VERSION ""

NS_ :

BS_:

BU_: TBOX Tester WCM MFS HUD CGW IHU

BO_ 3221225472 VECTOR__INDEPENDENT_SIG_MSG: 0 Vector__XXX
 SG_ SET_Rmirror_UD_Locaton : 0|6@0+ (2,-2) [0|100] "%" Vector__XXX
 SG_ SET_Rmirror_LR_Locaton : 0|6@0+ (2,-2) [0|100] "%" Vector__XXX
 SG_ SET_Lmirror_UD_Locaton : 0|6@0+ (2,-2) [0|100] "%" Vector__XXX
 SG_ SET_Lmirror_LR_Locaton : 0|6@0+ (2,-2) [0|100] "%" Vector__XXX
 SG_ HCU_HundECHis : 0|9@0+ (0.1,0) [0|51] "Kwh" Vector__XXX
 SG_ HCU_HundECAver : 0|9@0+ (0.1,0) [0|51] "Kwh" Vector__XXX
 SG_ CEM_IPM_FRSeatHeatVentSwSts : 0|3@0+ (1,0) [0|7] "Bit" Vector__XXX
 SG_ CEM_IPM_FLSeatHeatVentSwSts : 0|3@0+ (1,0) [0|7] "Bit" Vector__XXX
 SG_ IHU_StopChargeSW : 0|1@0+ (1,0) [0|1] "" Vector__XXX
 SG_ R_MsgAliveCounter : 0|4@0+ (1,0) [0|15] "" Vector__XXX

BO_ 1796 eLSD_Request: 8 IHU
 SG_ eLSD_Request_frame_type : 7|64@0+ (1,0) [0|7] ""  CGW

BO_ 1812 eLSD_response: 8 CGW
 SG_ eLSD_response_frame_type : 7|64@0+ (1,0) [0|7] ""  IHU

BO_ 1794 AWD_Request: 8 IHU
 SG_ AWD_Request_frame_type : 7|64@0+ (1,0) [0|7] ""  CGW

BO_ 1810 AWD_response: 8 CGW
 SG_ AWD_response_frame_type : 7|64@0+ (1,0) [0|7] ""  IHU

BO_ 1854 Diag_FCM_RES: 8 CGW
 SG_ Diag_FCM_RES : 7|64@0+ (1,0) [0|7] ""  IHU

BO_ 1838 Diag_FCM_REQ: 8 IHU
 SG_ FCM_Request_Frame_Type : 7|64@0+ (1,0) [0|7] ""  CGW

BO_ 1906 Diag_CGW_RES: 8 CGW
 SG_ Diag_CGW_RES : 7|64@0+ (1,0) [0|1] ""  IHU

BO_ 1890 Diag_CGW_REQ: 8 IHU
 SG_ Diag_CGW_REQ : 7|64@0+ (1,0) [0|1] ""  CGW

BO_ 933 FCM_FRM_2: 8 CGW
 SG_ PEBSObjectType : 54|3@0+ (1,0) [0|7] ""  IHU

BO_ 2015 Request_Broadcast: 8 IHU
 SG_ Request_Broadcast : 7|64@0+ (1,0) [0|1] ""  CGW

BO_ 1793 DVR_Request: 8 IHU
 SG_ DVR_Request_Frame_Type : 7|64@0+ (1,0) [0|1] ""  CGW

BO_ 1798 FPLA_Request: 8 IHU
 SG_ FPLA_Request_Frame_Type : 7|64@0+ (1,0) [0|1] ""  CGW

BO_ 1804 EAC_Request: 8 IHU
 SG_ EAC_Request_Frame_Type : 7|64@0+ (1,0) [0|1] ""  CGW

BO_ 1809 DVR_Response: 8 CGW
 SG_ DVR_Response_Frame_Type : 7|64@0+ (1,0) [0|1] ""  IHU

BO_ 1814 FPLA_Response: 8 CGW
 SG_ FPLA_Response_Frame_Type : 7|64@0+ (1,0) [0|1] ""  IHU

BO_ 1820 EAC_response: 8 CGW
 SG_ EAC_response_frame_type : 7|64@0+ (1,0) [0|1] ""  IHU

BO_ 1827 DWD_Request: 8 IHU
 SG_ DWD_Request_Frame_Type : 7|64@0+ (1,0) [0|1] ""  CGW

BO_ 1830 PLG_Request: 8 IHU
 SG_ PLG_Request : 7|64@0+ (1,0) [0|1] ""  CGW

BO_ 1833 ATCM_Request: 8 IHU
 SG_ ATCM_Request_frame_type : 7|64@0+ (1,0) [0|1] ""  CGW

BO_ 1843 DWD_Response: 8 CGW
 SG_ DWD_Response_Frame_Type : 7|64@0+ (1,0) [0|1] ""  IHU

BO_ 1846 PLG_response: 8 CGW
 SG_ PLG_response : 7|64@0+ (1,0) [0|1] ""  IHU

BO_ 1849 ATCM_Response: 8 CGW
 SG_ ATCMResponse_Frame_Type : 7|64@0+ (1,0) [0|1] ""  IHU

BO_ 1860 WCM_Request: 8 IHU
 SG_ WCM_Request_Frame_Type : 7|64@0+ (1,0) [0|1] ""  CGW

BO_ 1864 BSD_Request: 8 IHU
 SG_ BSD_Request_frame_type : 7|64@0+ (1,0) [0|1] ""  CGW

BO_ 1867 IPM_Request: 8 IHU
 SG_ IPM_Request_Frame_Type : 7|64@0+ (1,0) [0|1] ""  CGW

BO_ 1869 IMMO_Request: 8 IHU
 SG_ IMMO_Request_Frame_Type : 7|64@0+ (1,0) [0|1] ""  CGW

BO_ 1870 PTC_Request: 8 IHU
 SG_ PTC_Request_Frame_Type : 7|64@0+ (1,0) [0|1] ""  CGW

BO_ 1876 WCM_Response: 8 CGW
 SG_ WCM_Response_Frame_Type : 7|64@0+ (1,0) [0|1] ""  IHU

BO_ 1880 BSD_response: 8 CGW
 SG_ BSD_response_frame_type : 7|64@0+ (1,0) [0|1] ""  IHU

BO_ 1883 IPM_response: 8 CGW
 SG_ IPM_response_frame_type : 7|64@0+ (1,0) [0|1] ""  IHU

BO_ 1885 IMMO_response: 8 CGW
 SG_ IMMO_response_frame_type : 7|64@0+ (1,0) [0|1] ""  IHU

BO_ 1886 PTC_response: 8 CGW
 SG_ PTC_response_frame_type : 7|64@0+ (1,0) [0|1] ""  IHU

BO_ 1888 CEM_Request: 8 IHU
 SG_ CEM_Request_frame_type : 7|64@0+ (1,0) [0|1] ""  CGW

BO_ 1891 Radar_Request: 8 IHU
 SG_ Radar_Request_Frame_Type : 7|64@0+ (1,0) [0|1] ""  CGW

BO_ 1898 RFR_Request: 8 IHU
 SG_ RFR_Request_Frame_Type : 7|64@0+ (1,0) [0|1] ""  CGW

BO_ 1899 APM_Request: 8 IHU
 SG_ APM_Request_Frame_Type : 7|64@0+ (1,0) [0|1] ""  CGW

BO_ 1904 CEM_response: 8 CGW
 SG_ CEM_response_frame_type : 7|64@0+ (1,0) [0|1] ""  IHU

BO_ 1907 Radar_response: 8 CGW
 SG_ Radar_response_frame_type : 7|64@0+ (1,0) [0|1] ""  IHU

BO_ 1914 RFR_response: 8 CGW
 SG_ RFR_response_frame_type : 7|64@0+ (1,0) [0|1] ""  IHU

BO_ 1915 APM_response: 8 CGW
 SG_ APM_response_frame_type : 7|64@0+ (1,0) [0|1] ""  IHU

BO_ 1927 AMP_Request: 8 IHU
 SG_ AMPRequest_Frame_Type : 7|64@0+ (1,0) [0|1] ""  CGW

BO_ 1943 AMP_Response: 8 CGW
 SG_ AMPResponse_Frame_Type : 7|64@0+ (1,0) [0|1] ""  IHU

BO_ 1997 TRM_Request: 8 IHU
 SG_ TRM_Request_frame_type : 7|64@0+ (1,0) [0|1] ""  CGW

BO_ 2013 TRM_response: 8 CGW
 SG_ TRM_response_frame_type : 7|64@0+ (1,0) [0|1] ""  IHU

BO_ 1811 Diag_TCU_RES: 8 CGW
 SG_ DIAG_RESP_TCU : 7|64@0+ (1,0) [0|1] ""  IHU

BO_ 2017 Diag_TCU_REQ: 8 IHU
 SG_ Diag_TCU_REQ : 7|64@0+ (1,0) [0|1] ""  CGW

BO_ 1884 Diag_TBOX_RES: 8 CGW
 SG_ Diag_TBOX_RES : 7|64@0+ (1,0) [0|1] ""  IHU

BO_ 1868 Diag_TBOX_REQ: 8 IHU
 SG_ Diag_TBOX_REQ : 7|64@0+ (1,0) [0|1] ""  CGW

BO_ 1940 Diag_RRCR_RES: 8 CGW
 SG_ Diag_RRCR_RES : 7|64@0+ (1,0) [0|1] ""  IHU

BO_ 1924 Diag_RRCR_REQ: 8 IHU
 SG_ RRCR_Request_Frame_Type : 7|64@0+ (1,0) [0|1] ""  CGW

BO_ 1939 Diag_RLCR_RES: 8 CGW
 SG_ Diag_RLCR_RES : 7|64@0+ (1,0) [0|1] ""  IHU

BO_ 1923 Diag_RLCR_REQ: 8 IHU
 SG_ RLCR_Request_Frame_Type : 7|64@0+ (1,0) [0|1] ""  CGW

BO_ 1795 DIAG_REQ_TCU: 8 IHU
 SG_ DIAG_REQ_TCU : 7|64@0+ (1,0) [0|1] ""  CGW

BO_ 2031 Diag_OBDII_IPB_RES: 8 CGW
 SG_ Diag_OBD_ESP_RES : 7|64@0+ (1,0) [0|1] ""  IHU

BO_ 2023 Diag_OBDII_IPB_REQ: 8 IHU
 SG_ Diag_OBD_ESP_REQ : 7|64@0+ (1,0) [0|1] ""  CGW

BO_ 2025 DIAG_OBD_RESP_TCU: 8 CGW
 SG_ DIAG_OBD_RESP_TCU : 7|64@0+ (1,0) [0|1] ""  IHU

BO_ 2042 Diag_OBD_ESP_RES: 8 CGW
 SG_ Diag_OBD_ESP_RES : 7|64@0+ (1,0) [0|1] ""  IHU

BO_ 2034 Diag_OBD_ESP_REQ: 8 IHU
 SG_ Diag_OBD_ESP_REQ : 7|64@0+ (1,0) [0|1] ""  CGW

BO_ 1844 Diag_OBD_EPS_RES: 8 CGW
 SG_ Diag_OBD_EPS_RES : 7|64@0+ (1,0) [0|1] ""  IHU

BO_ 1828 Diag_OBD_EPS_REQ: 8 IHU
 SG_ Diag_OBD_EPS_REQ : 7|64@0+ (1,0) [0|1] ""  CGW

BO_ 1919 Diag_MFSR_RES: 8 CGW
 SG_ MFS_response_frame_type : 7|64@0+ (1,0) [0|1] ""  IHU

BO_ 1903 Diag_MFSR_Request: 8 IHU
 SG_ MFS_Request_Frame_Type : 7|64@0+ (1,0) [0|1] ""  CGW

BO_ 1918 Diag_MFSL_RES: 8 CGW
 SG_ MFS_response_frame_type : 7|64@0+ (1,0) [0|1] ""  IHU

BO_ 1902 Diag_MFSL_Request: 8 IHU
 SG_ MFS_Request_Frame_Type : 7|64@0+ (1,0) [0|1] ""  CGW

BO_ 1946 Diag_MCUR_RES: 8 CGW
 SG_ Diag_MCUR_RES : 7|64@0+ (1,0) [0|1] ""  IHU

BO_ 1818 Diag_MCUR_REQ: 8 IHU
 SG_ Diag_MCUR_REQ : 7|64@0+ (1,0) [0|1] ""  CGW

BO_ 2027 Diag_MCUF_RES: 8 CGW
 SG_ Diag_MCUF_RES : 7|64@0+ (1,0) [0|1] ""  IHU

BO_ 2019 Diag_MCUF_REQ: 8 IHU
 SG_ Diag_MCUF_REQ : 7|64@0+ (1,0) [0|1] ""  CGW

BO_ 1819 Diag_ISGF_RES: 8 CGW
 SG_ Diag_ISGF_RES : 7|64@0+ (1,0) [0|1] ""  IHU

BO_ 1803 Diag_ISGF_REQ: 8 IHU
 SG_ Diag_ISGF_REQ : 7|64@0+ (1,0) [0|1] ""  CGW

BO_ 1972 Diag_IPB2_RES: 8 CGW
 SG_ Diag_IPB2_RES : 7|64@0+ (1,0) [0|1] ""  IHU

BO_ 1953 Diag_IPB2_REQ: 8 IHU
 SG_ Diag_IPB2_REQ : 7|64@0+ (1,0) [0|1] ""  CGW

BO_ 1840 Diag_IPB_RES: 8 CGW
 SG_ Diag_IPB_RES : 7|64@0+ (1,0) [0|1] ""  IHU

BO_ 1824 Diag_IPB_REQ: 8 IHU
 SG_ Diag_IPB_REQ : 7|64@0+ (1,0) [0|1] ""  CGW

BO_ 1882 Diag_IHU_RES_1: 8 IHU
 SG_ IHU_Response_Frame_Type_1 : 7|64@0+ (1,0) [0|1] ""  CGW

BO_ 1866 Diag_IHU_Request_1: 8 CGW
 SG_ HUD_Request_Frame_Type : 7|64@0+ (1,0) [0|1] ""  IHU

BO_ 2026 DIAG_HCU_RES: 8 CGW
 SG_ DIAG_HCU_RES : 7|64@0+ (1,0) [0|1] ""  IHU

BO_ 2018 DIAG_HCU_REQ: 8 IHU
 SG_ DIAG_HCU_REQ : 7|64@0+ (1,0) [0|1] ""  CGW

BO_ 1855 Diag_FRM_RES: 8 CGW
 SG_ Diag_FRM_RES : 7|64@0+ (1,0) [0|1] ""  IHU

BO_ 1839 Diag_FRM_REQ: 8 IHU
 SG_ FRM_Request_Frame_Type : 7|64@0+ (1,0) [0|1] ""  CGW

BO_ 1841 DIAG_EPB_RES: 8 CGW
 SG_ DIAG_EPB_RES : 7|64@0+ (1,0) [0|1] ""  IHU

BO_ 1825 DIAG_EPB_REQ: 8 IHU
 SG_ DIAG_EPB_REQ : 7|64@0+ (1,0) [0|1] ""  CGW

BO_ 1822 Diag_EOP_RES: 8 CGW
 SG_ Diag_EOP_RES : 7|64@0+ (1,0) [0|1] ""  IHU

BO_ 1806 Diag_EOP_REQ: 8 IHU
 SG_ Diag_EOP_REQ : 7|64@0+ (1,0) [0|1] ""  CGW

BO_ 2024 Diag_EMS_RES: 8 CGW
 SG_ Diag_EMS_RES : 7|64@0+ (1,0) [0|1] ""  IHU

BO_ 2016 Diag_EMS_REQ: 8 IHU
 SG_ Diag_EMS_REQ : 7|64@0+ (1,0) [0|1] ""  CGW

BO_ 1947 Diag_EGS_SecondaryMCU_RES: 8 CGW
 SG_ EGS_Response_Frame_Type : 7|64@0+ (1,0) [0|1] ""  IHU

BO_ 1931 Diag_EGS_SecondaryMCU_REQ: 8 IHU
 SG_ EGS_Request_Frame_type : 7|64@0+ (1,0) [0|1] ""  CGW

BO_ 2008 Diag_EGS_RES: 8 CGW
 SG_ EGS_Response_Frame_Type1 : 7|64@0+ (1,0) [0|1] ""  IHU

BO_ 2000 Diag_EGS_REQ: 8 IHU
 SG_ EGS_Request_Frame_type1 : 7|64@0+ (1,0) [0|1] ""  CGW

BO_ 2030 Diag_CDU_RES: 8 CGW
 SG_ Diag_CDU_RES : 7|64@0+ (1,0) [0|1] ""  IHU

BO_ 2022 Diag_CDU_REQ: 8 IHU
 SG_ Diag_CDU_REQ : 7|64@0+ (1,0) [0|1] ""  CGW

BO_ 1942 Diag_BSCU_RES: 8 CGW
 SG_ BSCU_response_frame_type : 7|64@0+ (1,0) [0|1] ""  IHU

BO_ 1926 Diag_BSCU_REQ: 8 IHU
 SG_ BSCU_Request_Frame_Type : 7|64@0+ (1,0) [0|1] ""  CGW

BO_ 2029 Diag_BMS_RES: 8 CGW
 SG_ Diag_BMS_RES : 7|64@0+ (1,0) [0|1] ""  IHU

BO_ 2021 Diag_BMS_REQ: 8 IHU
 SG_ Diag_BMS_REQ : 7|64@0+ (1,0) [0|1] ""  CGW

BO_ 1968 Diag_BBCM_RES: 8 CGW
 SG_ BBCM_response_frame_type : 7|64@0+ (1,0) [0|1] ""  IHU

BO_ 1952 Diag_BBCM_REQ: 8 IHU
 SG_ BBCM_Request_Frame_Type : 7|64@0+ (1,0) [0|1] ""  CGW

BO_ 1975 Diag_AVAS_Response: 8 CGW
 SG_ AVAS_Response_Frame_Type : 7|64@0+ (1,0) [0|1] ""  IHU

BO_ 1959 Diag_AVAS_Request: 8 IHU
 SG_ AVAS_Request_frame_type : 7|64@0+ (1,0) [0|1] ""  CGW

BO_ 1910 Diag_APA_RES: 8 CGW
 SG_ APA_response_frame_type : 7|64@0+ (1,0) [0|1] ""  IHU

BO_ 1894 Diag_APA_REQ: 8 IHU
 SG_ APA_Request_Frame_Type : 7|64@0+ (1,0) [0|1] ""  CGW

BO_ 1845 Diag_ADCC_RES: 8 CGW
 SG_ Diag_ADCC_RES : 7|64@0+ (1,0) [0|1] ""  IHU

BO_ 1829 Diag_ADCC_REQ: 8 IHU
 SG_ ADCC_Request_Frame_Type : 7|64@0+ (1,0) [0|1] ""  CGW

BO_ 2041 Diag_ABM_RES_1: 8 CGW
 SG_ ABM_Response_Frame_Type_1 : 7|64@0+ (1,0) [0|1] ""  IHU

BO_ 2033 Diag_ABM_REQ_1: 8 IHU
 SG_ ABM_Request_Frame_Type_1 : 7|64@0+ (1,0) [0|1] ""  CGW

BO_ 1887 CLM_response: 8 CGW
 SG_ CLM_response_frame_type : 7|64@0+ (1,0) [0|1] ""  IHU

BO_ 1871 CLM_Request: 8 IHU
 SG_ CLM_Request_Frame_Type : 7|64@0+ (1,0) [0|1] ""  CGW

BO_ 1533 ADCC_4: 8 CGW
 SG_ AVM_1_BlindModeFeedback : 0|2@0+ (1,0) [0|3] ""  IHU
 SG_ AVM_1_AVM_Assist_DisplayMode : 14|4@0+ (1,0) [0|15] ""  IHU
 SG_ GearR_Open_APA_AVM_Feedback : 10|2@0+ (1,0) [0|3] ""  IHU
 SG_ AVM_1_SetPDCTriggerClassFeedback : 7|3@0+ (1,0) [0|7] ""  IHU
 SG_ AVM_1_OverspeedSwFeedback : 4|2@0+ (1,0) [0|3] ""  IHU
 SG_ AVM_1_BVSetFeedback : 2|2@0+ (1,0) [0|3] ""  IHU

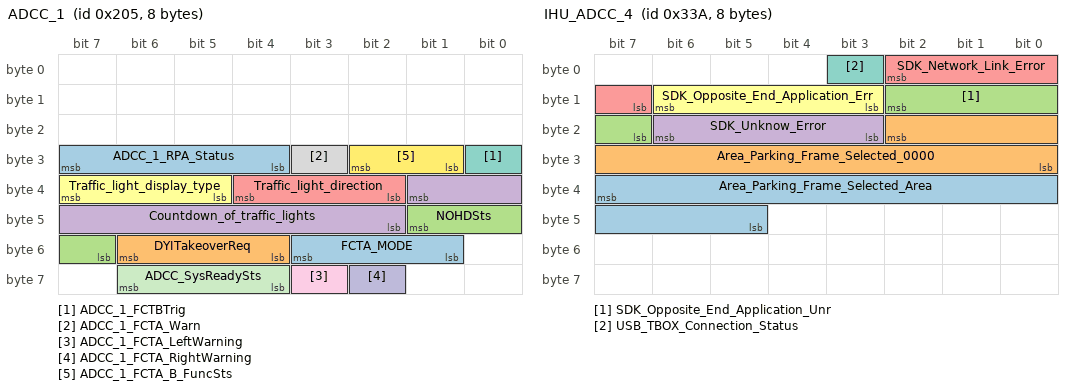
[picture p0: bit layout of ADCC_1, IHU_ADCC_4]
BO_ 517 ADCC_1: 8 CGW
 SG_ FCTA_MODE : 51|3@0+ (1,0) [0|7] ""  IHU
 SG_ DYITakeoverReq : 54|3@0+ (1,0) [0|7] ""  IHU
 SG_ NOHDSts : 41|3@0+ (1,0) [0|7] ""  IHU
 SG_ Countdown_of_traffic_lights : 33|8@0+ (1,0) [0|255] ""  IHU
 SG_ Traffic_light_direction : 36|3@0+ (1,0) [0|7] ""  IHU
 SG_ Traffic_light_display_type : 39|3@0+ (1,0) [0|7] ""  IHU
 SG_ ADCC_1_FCTBTrig : 24|1@0+ (1,0) [0|1] ""  IHU
 SG_ ADCC_1_FCTA_Warn : 27|1@0+ (1,0) [0|1] ""  IHU
 SG_ ADCC_1_FCTA_LeftWarning : 59|1@0+ (1,0) [0|1] ""  IHU
 SG_ ADCC_1_FCTA_RightWarning : 58|1@0+ (1,0) [0|1] ""  IHU
 SG_ ADCC_SysReadySts : 62|3@0+ (1,0) [0|5] ""  IHU
 SG_ ADCC_1_FCTA_B_FuncSts : 26|2@0+ (1,0) [0|3] ""  IHU
 SG_ ADCC_1_RPA_Status : 31|4@0+ (1,0) [0|15] ""  IHU

BO_ 826 IHU_ADCC_4: 8 IHU
 SG_ Area_Parking_Frame_Selected_Area : 39|11@0+ (20,-20480) [-20480|20460] ""  CGW
 SG_ Area_Parking_Frame_Selected_0000 : 18|11@0+ (20,-20480) [-20480|20460] ""  CGW
 SG_ SDK_Opposite_End_Application_Unr : 10|4@0+ (1,0) [0|15] ""  CGW
 SG_ SDK_Unknow_Error : 22|4@0+ (1,0) [0|15] ""  CGW
 SG_ SDK_Network_Link_Error : 2|4@0+ (1,0) [0|15] ""  CGW
 SG_ SDK_Opposite_End_Application_Err : 14|4@0+ (1,0) [0|15] ""  CGW
 SG_ USB_TBOX_Connection_Status : 3|1@0+ (1,0) [0|1] ""  CGW

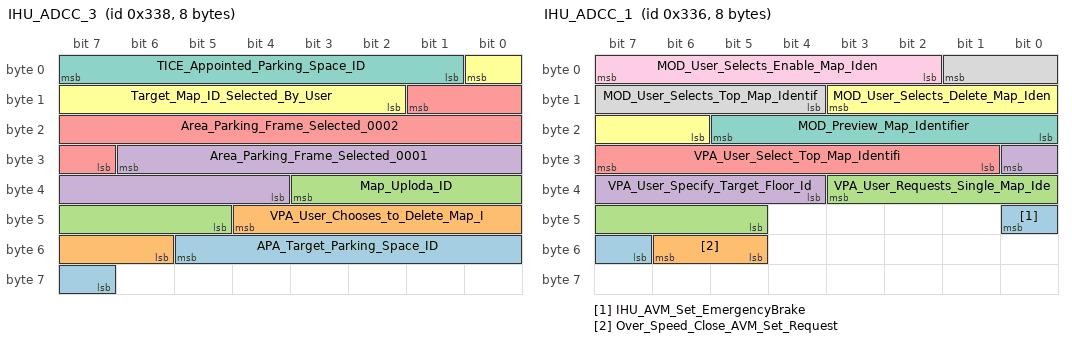
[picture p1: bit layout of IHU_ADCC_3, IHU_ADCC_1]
BO_ 824 IHU_ADCC_3: 8 IHU
 SG_ APA_Target_Parking_Space_ID : 53|7@0+ (1,0) [0|127] ""  CGW
 SG_ VPA_User_Chooses_to_Delete_Map_I : 44|7@0+ (1,0) [0|127] ""  CGW
 SG_ Map_Uploda_ID : 35|7@0+ (1,0) [0|127] ""  CGW
 SG_ Area_Parking_Frame_Selected_0001 : 30|11@0+ (20,-20480) [-20480|20460] ""  CGW
 SG_ Area_Parking_Frame_Selected_0002 : 9|11@0+ (20,-20480) [-20480|20460] ""  CGW
 SG_ Target_Map_ID_Selected_By_User : 0|7@0+ (1,0) [0|127] ""  CGW
 SG_ TICE_Appointed_Parking_Space_ID : 7|7@0+ (1,0) [0|127] ""  CGW

BO_ 823 IHU_ADCC_2: 8 IHU
 SG_ IHU_GearR_APA_AVM_OP_SW : 52|2@0+ (1,0) [0|3] ""  CGW
 SG_ Over_Speed_Remind_Warning_Mode_S : 47|2@0+ (1,0) [0|3] ""  CGW
 SG_ Map_Train_Type : 45|2@0+ (1,0) [0|3] ""  CGW
 SG_ IHU_AVM_Set_BV_OP_SW : 43|2@0+ (1,0) [0|3] ""  CGW
 SG_ Low_Speed_Auto_Parking_Space_Det : 39|2@0+ (1,0) [0|3] ""  CGW
 SG_ Map_Operation_Command : 37|4@0+ (1,0) [0|15] ""  CGW
 SG_ Trained_Parking_Mode_Selection : 33|2@0+ (1,0) [0|3] ""  CGW
 SG_ TRA_Command : 16|3@0+ (1,0) [0|7] ""  CGW
 SG_ TICE_Vehicle_Restore_Factory_Set : 29|1@0+ (1,0) [0|1] ""  CGW
 SG_ TICE_Vehicle_Restore_Factor_0000 : 28|1@0+ (1,0) [0|1] ""  CGW
 SG_ Initial_D_Gear_Open_AVM_Switch_S : 27|2@0+ (1,0) [0|3] ""  CGW
 SG_ Low_Speed_Auto_Location_Function : 25|2@0+ (1,0) [0|3] ""  CGW
 SG_ TICE_Trained_Parking_Command : 8|3@0+ (1,0) [0|7] ""  CGW
 SG_ TICE_Trained_Parking_Out_Command : 21|2@0+ (1,0) [0|3] ""  CGW
 SG_ Trained_Parking_Self_Learning_An : 19|3@0+ (1,0) [0|7] ""  CGW
 SG_ Driving_Function_User_Learning_S : 0|2@0+ (1,0) [0|3] ""  CGW
 SG_ MOD_Route_Map_Operation_Command : 14|4@0+ (1,0) [0|15] ""  CGW
 SG_ Location_Command : 10|2@0+ (1,0) [0|3] ""  CGW
 SG_ VPA_Request_to_Display_Route_Lis : 7|1@0+ (1,0) [0|1] ""  CGW
 SG_ Parking_Function_User_Learning_S : 6|2@0+ (1,0) [0|3] ""  CGW
 SG_ MOD_Function_Run_Operation_Comma : 4|3@0+ (1,0) [0|7] ""  CGW
 SG_ MOD_Request_to_Display_Route_Lis : 1|1@0+ (1,0) [0|1] ""  CGW

BO_ 822 IHU_ADCC_1: 8 IHU
 SG_ IHU_AVM_Set_EmergencyBrake : 40|2@0+ (1,0) [0|2] ""  CGW
 SG_ Over_Speed_Close_AVM_Set_Request : 54|2@0+ (1,0) [0|2] ""  CGW
 SG_ VPA_User_Requests_Single_Map_Ide : 35|7@0+ (1,0) [0|127] ""  CGW
 SG_ VPA_User_Specify_Target_Floor_Id : 24|5@0+ (1,0) [0|31] ""  CGW
 SG_ VPA_User_Select_Top_Map_Identifi : 31|7@0+ (1,0) [0|127] ""  CGW
 SG_ MOD_User_Selects_Delete_Map_Iden : 11|6@0+ (1,0) [0|63] ""  CGW
 SG_ MOD_Preview_Map_Identifier : 21|6@0+ (1,0) [0|63] ""  CGW
 SG_ MOD_User_Selects_Top_Map_Identif : 1|6@0+ (1,0) [0|63] ""  CGW
 SG_ MOD_User_Selects_Enable_Map_Iden : 7|6@0+ (1,0) [0|63] ""  CGW

BO_ 828 IHU_AVM_APA_RPA: 8 IHU
 SG_ APA_Pullout_Engage_Confirm : 63|2@0+ (1,0) [0|3] ""  CGW
 SG_ IHU_APA_PullOut_Direction : 61|4@0+ (1,0) [0|15] ""  CGW
 SG_ IHU_APA_Combi_Sw : 57|2@0+ (1,0) [0|3] ""  CGW
 SG_ IHU_APA_Prompt_Confirm : 55|1@0+ (1,0) [0|1] ""  CGW
 SG_ IHU_APA_Heartbeat : 54|1@0+ (1,0) [0|1] ""  CGW
 SG_ IHU_RPA_Engage_Confirm : 52|3@0+ (1,0) [0|7] ""  CGW
 SG_ IHU_RPA_OP_SW : 49|2@0+ (1,0) [0|3] ""  CGW
 SG_ IHU_AVM_Set_AutoExit : 47|2@0+ (1,0) [0|3] ""  CGW
 SG_ IHU_AVM_Set_LicensePlate : 45|2@0+ (1,0) [0|3] ""  CGW
 SG_ IHU_AVM_Set_GuideLine : 43|2@0+ (1,0) [0|3] ""  CGW
 SG_ IHU_AVM_Set_FactoryDefault : 41|2@0+ (1,0) [0|3] ""  CGW
 SG_ IHU_AVM_Set_PASTrigger : 24|2@0+ (1,0) [0|3] ""  CGW
 SG_ APA_Parkin_Engage_Confirm : 38|2@0+ (1,0) [0|3] ""  CGW
 SG_ DataCollAuthSw : 36|1@0+ (1,0) [0|1] ""  CGW
 SG_ FCTASwtSet : 35|2@0+ (1,0) [0|3] ""  CGW
 SG_ FCTBrkSwtSet : 33|2@0+ (1,0) [0|3] ""  CGW
 SG_ IHU_AVM_Set_TurnIndication : 31|2@0+ (1,0) [0|3] ""  CGW
 SG_ IHU_AVM_Set_BodyColor : 29|3@0+ (1,0) [0|7] ""  CGW
 SG_ IHU_AVM_Set_AutoZoom : 26|2@0+ (1,0) [0|3] ""  CGW
 SG_ IHU_AVM_OP_SW : 8|2@0+ (1,0) [0|3] ""  CGW
 SG_ IHU_AVM_Set_SteeringWheel : 22|2@0+ (1,0) [0|3] ""  CGW
 SG_ IHU_AVM_Set_Language : 20|3@0+ (1,0) [0|7] ""  CGW
 SG_ IHU_AVM_Set_RadarWarining : 17|2@0+ (1,0) [0|3] ""  CGW
 SG_ IHU_APA_PullOut_Option : 15|2@0+ (1,0) [0|3] ""  CGW
 SG_ IHU_APA_ParkIn_Direction : 10|2@0+ (1,0) [0|3] ""  CGW
 SG_ IHU_APA_Suspend_Resume : 1|2@0+ (1,0) [0|3] ""  CGW
 SG_ IHU_APA_Engage_Confirm : 13|3@0+ (1,0) [0|7] ""  CGW
 SG_ IHU_APA_Slot_Chosen : 5|4@0+ (1,0) [0|15] ""  CGW
 SG_ IHU_APA_OP_SW : 7|2@0+ (1,0) [0|3] ""  CGW

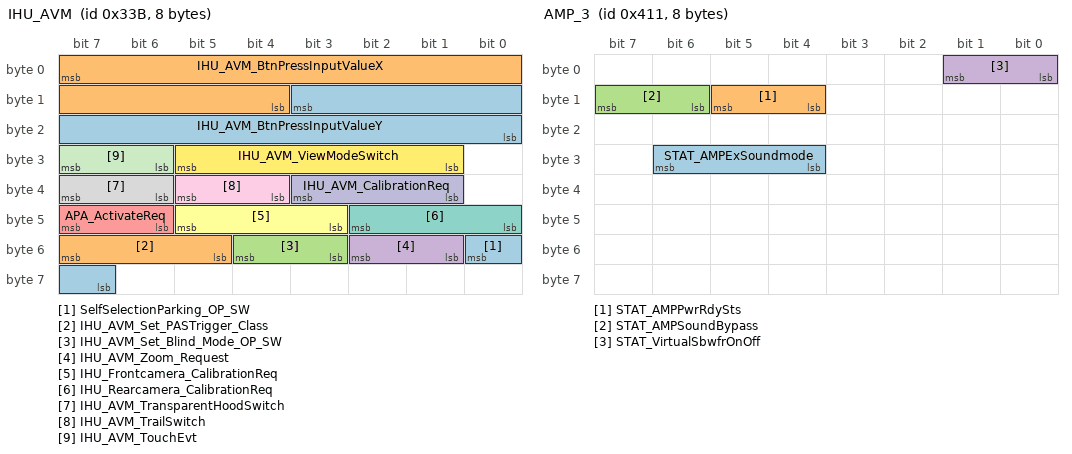
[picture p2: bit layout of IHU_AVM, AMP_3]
BO_ 827 IHU_AVM: 8 IHU
 SG_ SelfSelectionParking_OP_SW : 48|2@0+ (1,0) [0|3] ""  CGW
 SG_ IHU_AVM_Set_PASTrigger_Class : 55|3@0+ (1,0) [0|7] ""  CGW
 SG_ IHU_AVM_Set_Blind_Mode_OP_SW : 52|2@0+ (1,0) [0|3] ""  CGW
 SG_ IHU_AVM_Zoom_Request : 50|2@0+ (1,0) [0|3] ""  CGW
 SG_ APA_ActivateReq : 47|2@0+ (1,0) [0|3] ""  CGW
 SG_ IHU_Frontcamera_CalibrationReq : 45|3@0+ (1,0) [0|7] ""  CGW
 SG_ IHU_Rearcamera_CalibrationReq : 42|3@0+ (1,0) [0|7] ""  CGW
 SG_ IHU_AVM_TransparentHoodSwitch : 39|2@0+ (1,0) [0|3] ""  CGW
 SG_ IHU_AVM_TrailSwitch : 37|2@0+ (1,0) [0|3] ""  CGW
 SG_ IHU_AVM_CalibrationReq : 35|3@0+ (1,0) [0|7] ""  CGW
 SG_ IHU_AVM_TouchEvt : 31|2@0+ (1,0) [0|3] ""  CGW
 SG_ IHU_AVM_ViewModeSwitch : 29|5@0+ (1,0) [0|31] ""  CGW
 SG_ IHU_AVM_BtnPressInputValueY : 11|12@0+ (1,0) [0|4095] ""  CGW
 SG_ IHU_AVM_BtnPressInputValueX : 7|12@0+ (1,0) [0|4095] ""  CGW

BO_ 1073 CEM_BCM_9: 8 CGW
 SG_ CEM_CarMode : 7|3@0+ (1,0) [0|7] ""  IHU

BO_ 1015 ADCC_9: 8 CGW
 SG_ ADCC_9_HighVoltageReq : 17|1@0+ (1,0) [0|1] ""  IHU
 SG_ ADCC_9_SentinelModeExitReasonSts : 11|4@0+ (1,0) [0|15] ""  IHU
 SG_ ADCC_9_SentinelModeAlarmSts : 23|2@0+ (1,0) [0|3] ""  IHU
 SG_ ADCC_9_SentrySts : 13|2@0+ (1,0) [0|3] ""  IHU
 SG_ ADCC_9_SentinelModeWorkingSts : 3|4@0+ (1,0) [0|15] ""  IHU
 SG_ ADCC_9_SentinelModeSts : 15|2@0+ (1,0) [0|3] ""  IHU
 SG_ ADCC_9_SentinelModeSwitchSts : 5|2@0+ (1,0) [0|3] ""  IHU
 SG_ ADCC_9_SentinelMode_SensitivityS : 7|2@0+ (1,0) [0|3] ""  IHU

BO_ 934 CEM_BCM_12: 8 CGW
 SG_ BCM_12_EBS_Current : 39|16@0+ (0.0078125,-200) [0|200] ""  IHU
 SG_ BCM_12_EBS_Voltage : 21|14@0+ (0.0009765625,3) [3|18] ""  IHU

BO_ 1105 CGW_1: 8 CGW
 SG_ OBDDiagnosisReqInd : 7|1@0+ (1,0) [0|1] ""  IHU

BO_ 746 CEM_BCM_10: 8 CGW
 SG_ OTAPwrOnReqFb : 19|2@0+ (1,0) [0|3] ""  IHU
 SG_ OTAPwrDwnReqFb : 17|2@0+ (1,0) [0|3] ""  IHU
 SG_ OTAModStsFb : 7|1@0+ (1,0) [0|1] ""  IHU

BO_ 1216 SCU_1: 8 CGW
 SG_ RestAreaFb : 57|2@0+ (1,0) [0|3] ""  IHU

BO_ 1041 AMP_3: 8 CGW
 SG_ STAT_AMPExSoundmode : 30|3@0+ (1,0) [0|7] ""  IHU
 SG_ STAT_AMPPwrRdySts : 13|2@0+ (1,0) [0|3] ""  IHU
 SG_ STAT_AMPSoundBypass : 15|2@0+ (1,0) [0|3] ""  IHU
 SG_ STAT_VirtualSbwfrOnOff : 1|2@0+ (1,0) [0|3] ""  IHU

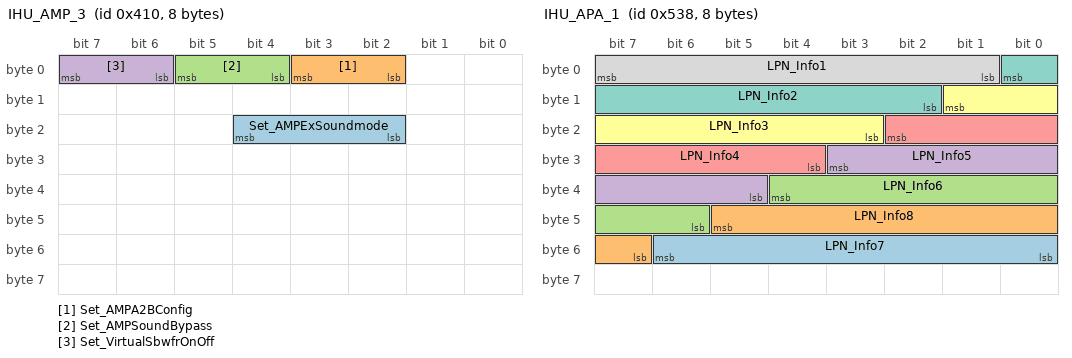
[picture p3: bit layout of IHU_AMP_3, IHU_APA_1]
BO_ 1040 IHU_AMP_3: 8 IHU
 SG_ Set_AMPExSoundmode : 20|3@0+ (1,0) [0|7] ""  CGW
 SG_ Set_AMPA2BConfig : 3|2@0+ (1,0) [0|3] ""  CGW
 SG_ Set_AMPSoundBypass : 5|2@0+ (1,0) [0|3] ""  CGW
 SG_ Set_VirtualSbwfrOnOff : 7|2@0+ (1,0) [0|1] ""  CGW

BO_ 1167 ICC: 8 IHU
 SG_ ICC_DrivePowerDispSet : 15|2@0+ (1,0) [0|3] ""  CGW
 SG_ ICC_V2L_IntlDisChg : 7|8@0+ (1,0) [0|255] ""  CGW

BO_ 1143 OBC: 8 CGW
 SG_ OBC_InnerDischgReq : 33|1@0+ (1,0) [0|1] ""  IHU

BO_ 1299 IHU_22: 8 IHU
 SG_ Queen_bed_mode_Swt : 7|3@0+ (1,0) [0|7] ""  CGW

BO_ 1336 IHU_APA_1: 8 IHU
 SG_ LPN_Info7 : 54|7@0+ (1,0) [0|127] ""  CGW
 SG_ LPN_Info8 : 45|7@0+ (1,0) [0|127] ""  CGW
 SG_ LPN_Info6 : 36|7@0+ (1,0) [0|127] ""  CGW
 SG_ LPN_Info5 : 27|7@0+ (1,0) [0|127] ""  CGW
 SG_ LPN_Info4 : 18|7@0+ (1,0) [0|127] ""  CGW
 SG_ LPN_Info3 : 9|7@0+ (1,0) [0|127] ""  CGW
 SG_ LPN_Info2 : 0|7@0+ (1,0) [0|127] ""  CGW
 SG_ LPN_Info1 : 7|7@0+ (1,0) [0|127] ""  CGW

BO_ 1526 CEM_BCM_DoorSrv_Sts: 8 CGW
 SG_ FRSeatliedownwarning : 7|1@0+ (1,0) [0|1] ""  IHU
 SG_ FRSeatliedownsts : 6|2@0+ (1,0) [0|3] ""  IHU

BO_ 1298 IHU_18: 8 IHU
 SG_ IHU_RestAreaSet : 16|2@0+ (1,0) [0|3] ""  CGW
 SG_ SET_DriverSeat_MassageModeReq : 2|4@0+ (1,0) [0|15] ""  CGW
 SG_ SET_DriverSeat_MassageStsReq : 7|2@0+ (1,0) [0|3] ""  CGW
 SG_ SET_DriverSeat_MassageVibrationR : 5|3@0+ (1,0) [0|7] ""  CGW

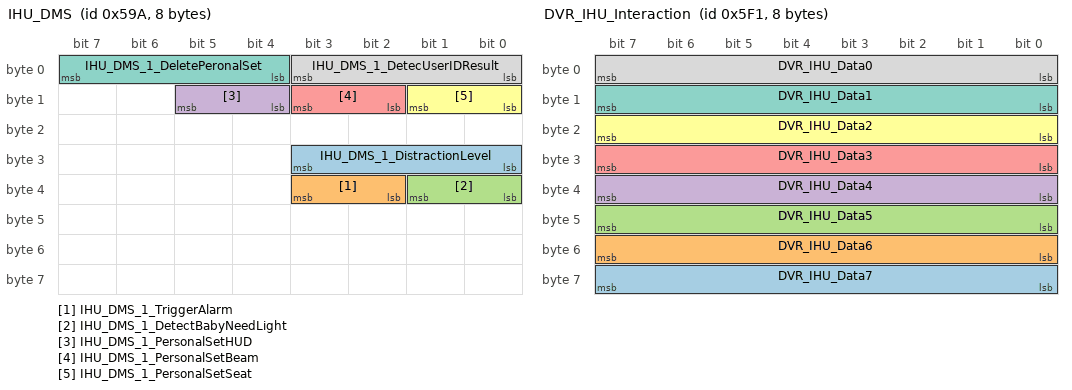
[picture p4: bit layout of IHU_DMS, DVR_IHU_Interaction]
BO_ 1434 IHU_DMS: 8 IHU
 SG_ IHU_DMS_1_DistractionLevel : 27|4@0+ (1,0) [0|15] ""  CGW
 SG_ IHU_DMS_1_TriggerAlarm : 35|2@0+ (1,0) [0|3] ""  CGW
 SG_ IHU_DMS_1_DetectBabyNeedLight : 33|2@0+ (1,0) [0|3] ""  CGW
 SG_ IHU_DMS_1_PersonalSetHUD : 13|2@0+ (1,0) [0|3] ""  CGW
 SG_ IHU_DMS_1_PersonalSetBeam : 11|2@0+ (1,0) [0|3] ""  CGW
 SG_ IHU_DMS_1_PersonalSetSeat : 9|2@0+ (1,0) [0|3] ""  CGW
 SG_ IHU_DMS_1_DeletePeronalSet : 7|4@0+ (1,0) [0|15] ""  CGW
 SG_ IHU_DMS_1_DetecUserIDResult : 3|4@0+ (1,0) [0|15] ""  CGW

BO_ 1184 WCM_NFC: 8 CGW
 SG_ WCM_NFC_Status : 0|1@0+ (1,0) [0|1] ""  IHU

BO_ 1418 DVR_1: 8 CGW
 SG_ DVR_1_RecordSts : 25|2@0+ (1,0) [0|3] ""  IHU
 SG_ DVR_1_Sdcard_Sts : 2|3@0+ (1,0) [0|7] "bit"  IHU
 SG_ DVR_1_SystemSts : 21|1@0+ (1,0) [0|1] ""  IHU

BO_ 1521 DVR_IHU_Interaction: 8 CGW
 SG_ DVR_IHU_Data7 : 63|8@0+ (1,0) [0|255] ""  IHU
 SG_ DVR_IHU_Data6 : 55|8@0+ (1,0) [0|255] ""  IHU
 SG_ DVR_IHU_Data5 : 47|8@0+ (1,0) [0|255] ""  IHU
 SG_ DVR_IHU_Data4 : 39|8@0+ (1,0) [0|0] ""  IHU
 SG_ DVR_IHU_Data3 : 31|8@0+ (1,0) [0|255] ""  IHU
 SG_ DVR_IHU_Data2 : 23|8@0+ (1,0) [0|255] ""  IHU
 SG_ DVR_IHU_Data1 : 15|8@0+ (1,0) [0|255] ""  IHU
 SG_ DVR_IHU_Data0 : 7|8@0+ (1,0) [0|255] ""  IHU

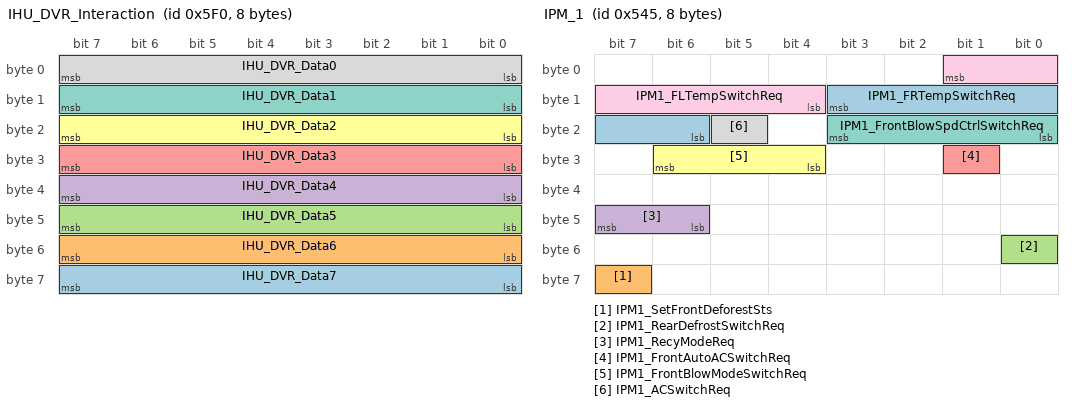
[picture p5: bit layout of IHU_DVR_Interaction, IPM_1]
BO_ 1520 IHU_DVR_Interaction: 8 IHU
 SG_ IHU_DVR_Data7 : 63|8@0+ (1,0) [0|255] ""  CGW
 SG_ IHU_DVR_Data6 : 55|8@0+ (1,0) [0|255] ""  CGW
 SG_ IHU_DVR_Data5 : 47|8@0+ (1,0) [0|255] ""  CGW
 SG_ IHU_DVR_Data4 : 39|8@0+ (1,0) [0|255] ""  CGW
 SG_ IHU_DVR_Data3 : 31|8@0+ (1,0) [0|255] ""  CGW
 SG_ IHU_DVR_Data2 : 23|8@0+ (1,0) [0|255] ""  CGW
 SG_ IHU_DVR_Data1 : 15|8@0+ (1,0) [0|255] ""  CGW
 SG_ IHU_DVR_Data0 : 7|8@0+ (1,0) [0|255] ""  CGW

BO_ 1487 TRM_1: 8 CGW
 SG_ TRM_1_MotorHomeConnectSts : 6|1@0+ (1,0) [0|1] ""  IHU

BO_ 1349 IPM_1: 8 CGW
 SG_ IPM1_FRTempSwitchReq : 11|6@0+ (0.5,0) [16|30] ""  IHU
 SG_ IPM1_SetFrontDeforestSts : 63|1@0+ (1,0) [0|1] ""  IHU
 SG_ IPM1_RearDefrostSwitchReq : 48|1@0+ (1,0) [0|1] ""  IHU
 SG_ IPM1_RecyModeReq : 47|2@0+ (1,0) [0|3] ""  IHU
 SG_ IPM1_FrontAutoACSwitchReq : 25|1@0+ (1,0) [0|1] ""  IHU
 SG_ IPM1_FrontBlowModeSwitchReq : 30|3@0+ (1,0) [0|7] ""  IHU
 SG_ IPM1_FrontBlowSpdCtrlSwitchReq : 19|4@0+ (1,0) [0|15] ""  IHU
 SG_ IPM1_ACSwitchReq : 21|1@0+ (1,0) [0|1] ""  IHU
 SG_ IPM1_FLTempSwitchReq : 1|6@0+ (0.5,0) [16|30] "℃"  IHU

BO_ 809 ZDC_DCLC_1: 8 CGW
 SG_ Rear_Camera_Textinfo : 27|3@0+ (1,0) [0|3] ""  IHU
 SG_ ELK_Sts : 32|3@0+ (1,0) [0|7] ""  IHU
 SG_ RCW_OnOffStFeedback : 44|1@0+ (1,0) [0|1] ""  IHU
 SG_ RCTB_OnOffStFeedback : 43|1@0+ (1,0) [0|1] ""  IHU
 SG_ TJA_ICA_WarmingSwitchFeedback : 42|1@0+ (1,0) [0|1] ""  IHU
 SG_ IESSwtSetFeedback : 41|1@0+ (1,0) [0|1] ""  IHU
 SG_ LDPSwitchFeedback : 40|1@0+ (1,0) [0|1] ""  IHU
 SG_ RCW_Warning : 37|2@0+ (1,0) [0|3] ""  IHU
 SG_ LDW_Status : 35|3@0+ (1,0) [0|7] ""  IHU
 SG_ RCTB_Mode : 31|2@0+ (1,0) [0|3] ""  IHU
 SG_ RCW_Mode : 29|2@0+ (1,0) [0|3] ""  IHU
 SG_ DCLCChange_Status : 8|3@0+ (1,0) [0|7] ""  IHU
 SG_ DCLC_Warning : 21|1@0+ (1,0) [0|1] ""  IHU
 SG_ RCTB_LeftWarning : 20|2@0+ (1,0) [0|3] ""  IHU
 SG_ RCTB_RightWarning : 18|2@0+ (1,0) [0|3] ""  IHU
 SG_ DCLCLaneChangePossible : 0|2@0+ (1,0) [0|3] ""  IHU
 SG_ DCLCLaneChangeReason : 14|4@0+ (1,0) [0|15] ""  IHU
 SG_ DCLCLaneChange_Type : 10|2@0+ (1,0) [0|3] ""  IHU
 SG_ IES_Status : 7|2@0+ (1,0) [0|3] ""  IHU
 SG_ ELKA_On_Off_Feedback : 5|2@0+ (1,0) [0|3] ""  IHU
 SG_ ELKA_Active : 3|1@0+ (1,0) [0|1] ""  IHU
 SG_ DCLCEnabled_Request : 2|2@0+ (1,0) [0|3] ""  IHU

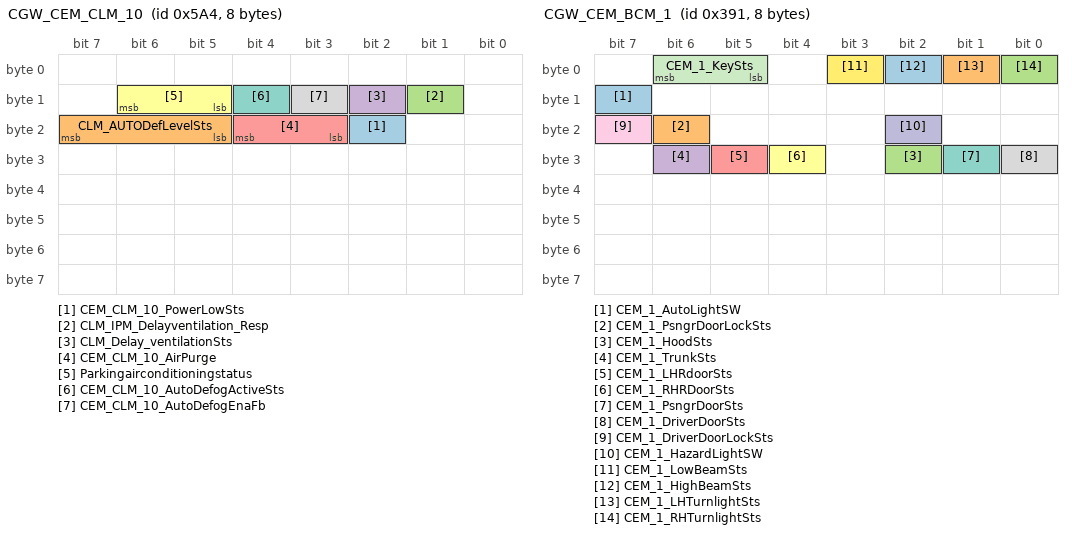
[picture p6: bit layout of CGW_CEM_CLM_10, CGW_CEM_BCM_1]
BO_ 1444 CGW_CEM_CLM_10: 8 Vector__XXX
 SG_ CEM_CLM_10_PowerLowSts : 18|1@0+ (1,0) [0|1] ""  IHU
 SG_ CLM_AUTODefLevelSts : 23|3@0+ (1,0) [0|7] ""  IHU
 SG_ CLM_IPM_Delayventilation_Resp : 9|1@0+ (1,0) [0|1] ""  IHU
 SG_ CLM_Delay_ventilationSts : 10|1@0+ (1,0) [0|1] ""  IHU
 SG_ CEM_CLM_10_AirPurge : 20|2@0+ (1,0) [0|3] ""  IHU
 SG_ Parkingairconditioningstatus : 14|2@0+ (1,0) [0|3] ""  IHU
 SG_ CEM_CLM_10_AutoDefogActiveSts : 12|1@0+ (1,0) [0|1] ""  IHU
 SG_ CEM_CLM_10_AutoDefogEnaFb : 11|1@0+ (1,0) [0|1] ""  IHU

BO_ 1534 CGW_CLM_UVC: 8 CGW
 SG_ CEM_3_UVC_LuminanceBf : 47|3@0+ (1,0) [0|7] ""  IHU
 SG_ CEM_3_UVC_WorkingBf : 36|2@0+ (1,0) [0|3] ""  IHU
 SG_ CLM_Coollantfillsts : 0|1@0+ (1,0) [0|1] ""  IHU

BO_ 1480 TIHU_IHU_20: 8 IHU
 SG_ NextTrafficSts : 31|2@0+ (1,0) [0|3] ""  CGW
 SG_ TrafficSts : 17|2@0+ (1,0) [0|3] ""  CGW
 SG_ NavDistance : 7|22@0+ (20,0) [0|83886060] ""  CGW

BO_ 1416 IHU_24: 8 IHU
 SG_ IHU_24_Reservation_SentinelReq : 41|2@0+ (1,0) [0|3] ""  CGW
 SG_ IHU_24_TimeToStopSentinelMinuteS : 47|6@0+ (1,0) [0|63] ""  CGW
 SG_ IHU_24_TimeToStopSentinelHourSet : 36|5@0+ (1,0) [0|31] ""  CGW
 SG_ IHU_24_TimeToStartSentinelMinute : 26|6@0+ (1,0) [0|63] ""  CGW
 SG_ IHU_24_TimeToStartSentinelHourSe : 31|5@0+ (1,0) [0|31] ""  CGW
 SG_ IHU_24_TimeToStartSentinelDaySet : 17|2@0+ (1,0) [0|3] ""  CGW
 SG_ IHU_24_SentinelMode_SensitivityR : 19|2@0+ (1,0) [0|3] ""  CGW
 SG_ IHU_24_SentinelModeSwitchReq : 21|2@0+ (1,0) [0|3] ""  CGW
 SG_ IHU_24_Sentinel_RemoteLockFeedba : 23|2@0+ (1,0) [0|3] ""  CGW
 SG_ FollowingTrackToReverse : 9|1@0+ (1,0) [0|1] ""  CGW
 SG_ RPASwitch : 8|1@0+ (1,0) [0|1] ""  CGW
 SG_ Ready2GoSwitch : 11|2@0+ (1,0) [0|3] ""  CGW
 SG_ IESSwtSet : 13|2@0+ (1,0) [0|3] ""  CGW
 SG_ IHU_11_TSISwtSet : 15|2@0+ (1,0) [0|3] ""  CGW
 SG_ ELK_Switch : 7|2@0+ (1,0) [0|3] ""  CGW
 SG_ DCLC_Switch : 5|2@0+ (1,0) [0|3] ""  CGW
 SG_ RCW_OnOffSt : 3|2@0+ (1,0) [0|3] ""  CGW
 SG_ RCTB_OnOffSt : 1|2@0+ (1,0) [0|3] ""  CGW

BO_ 1330 IHU_29: 8 IHU
 SG_ ElectcUnlckCmd : 15|1@0+ (1,0) [0|1] ""  CGW
 SG_ IHU_29_DchaSet : 57|2@0+ (1,0) [0|3] ""  CGW

BO_ 805 ABS_ESP_17: 8 CGW
 SG_ TMF_TMFSysFault : 8|1@0+ (1,0) [0|1] ""  IHU
 SG_ TMF_SpdAct : 39|16@0+ (1,0) [0|131071] ""  IHU
 SG_ ABS_ESP_17_ATM_ESPShiftAllwd : 9|1@0+ (1,0) [0|1] ""  IHU

BO_ 896 CGW_EPS_1: 3 TBOX
 SG_ EPS_1__MFS_ShakeSts : 7|1@0+ (1,0) [0|1] ""  IHU
 SG_ EPS_1_EPSModeSts : 9|2@0+ (1,0) [0|3] ""  IHU
 SG_ EPS_1_RecoverableFault : 23|5@0+ (1,0) [0|31] ""  IHU
 SG_ EPS_1_AssociWithDriverModeSts : 11|1@0+ (1,0) [0|1] ""  IHU

BO_ 913 CGW_CEM_BCM_1: 8 CGW
 SG_ CEM_1_AutoLightSW : 15|1@0+ (1,0) [0|1] ""  IHU
 SG_ CEM_1_PsngrDoorLockSts : 22|1@0+ (1,0) [0|1] ""  IHU
 SG_ CEM_1_HoodSts : 26|1@0+ (1,0) [0|1] ""  IHU
 SG_ CEM_1_TrunkSts : 30|1@0+ (1,0) [0|1] ""  IHU
 SG_ CEM_1_LHRdoorSts : 29|1@0+ (1,0) [0|1] ""  IHU
 SG_ CEM_1_RHRDoorSts : 28|1@0+ (1,0) [0|1] ""  IHU
 SG_ CEM_1_PsngrDoorSts : 25|1@0+ (1,0) [0|1] ""  IHU
 SG_ CEM_1_DriverDoorSts : 24|1@0+ (1,0) [0|1] ""  IHU
 SG_ CEM_1_DriverDoorLockSts : 23|1@0+ (1,0) [0|1] ""  IHU
 SG_ CEM_1_HazardLightSW : 18|1@0+ (1,0) [0|1] ""  IHU
 SG_ CEM_1_KeySts : 6|2@0+ (1,0) [0|3] ""  IHU
 SG_ CEM_1_LowBeamSts : 3|1@0+ (1,0) [0|1] ""  IHU
 SG_ CEM_1_HighBeamSts : 2|1@0+ (1,0) [0|1] ""  IHU
 SG_ CEM_1_LHTurnlightSts : 1|1@0+ (1,0) [0|1] ""  IHU
 SG_ CEM_1_RHTurnlightSts : 0|1@0+ (1,0) [0|1] ""  IHU

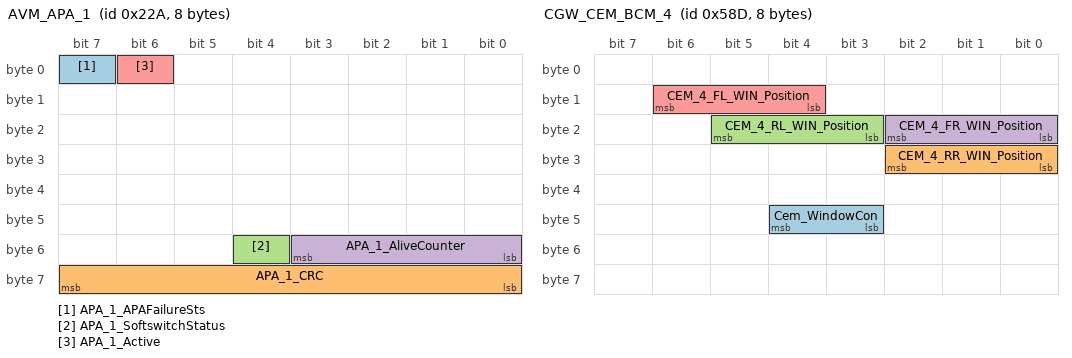
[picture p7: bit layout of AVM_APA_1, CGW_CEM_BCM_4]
BO_ 554 AVM_APA_1: 8 CGW
 SG_ APA_1_APAFailureSts : 7|1@0+ (1,0) [0|1] ""  IHU
 SG_ APA_1_CRC : 63|8@0+ (1,0) [0|255] ""  IHU
 SG_ APA_1_SoftswitchStatus : 52|1@0+ (1,0) [0|1] ""  IHU
 SG_ APA_1_AliveCounter : 51|4@0+ (1,0) [0|15] ""  IHU
 SG_ APA_1_Active : 6|1@0+ (1,0) [0|1] ""  IHU

BO_ 1421 CGW_CEM_BCM_4: 8 CGW
 SG_ Cem_WindowCon : 44|2@0+ (1,0) [0|3] ""  IHU
 SG_ CEM_4_RR_WIN_Position : 26|3@0+ (1,0) [0|7] ""  IHU
 SG_ CEM_4_RL_WIN_Position : 21|3@0+ (1,0) [0|7] ""  IHU
 SG_ CEM_4_FR_WIN_Position : 18|3@0+ (1,0) [0|7] ""  IHU
 SG_ CEM_4_FL_WIN_Position : 14|3@0+ (1,0) [0|7] ""  IHU

BO_ 1253 CGW_ABS_ESP_5: 8 TBOX
 SG_ ESP_5_LHFPulseCounter : 44|13@0+ (1,0) [0|8191] ""  IHU
 SG_ ESP_5_RHFPulseCounter : 25|13@0+ (1,0) [0|8191] ""  IHU
 SG_ ESP_5_RHRPulseCounter : 23|13@0+ (1,0) [0|8191] ""  IHU
 SG_ ESP_5_LHRPulseCounter : 7|13@0+ (1,0) [0|8191] ""  IHU

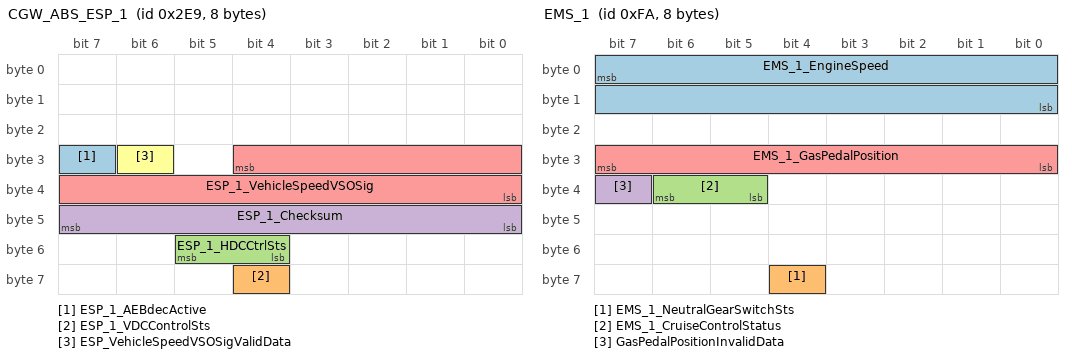
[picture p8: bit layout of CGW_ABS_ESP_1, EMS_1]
BO_ 745 CGW_ABS_ESP_1: 8 CGW
 SG_ ESP_1_AEBdecActive : 31|1@0+ (1,0) [0|1] ""  IHU
 SG_ ESP_1_VDCControlSts : 60|1@0+ (1,0) [0|1] ""  IHU
 SG_ ESP_1_HDCCtrlSts : 53|2@0+ (1,0) [0|3] ""  IHU
 SG_ ESP_1_Checksum : 47|8@0+ (1,0) [0|255] ""  IHU
 SG_ ESP_1_VehicleSpeedVSOSig : 28|13@0+ (0.0625,0) [0|511.9375] "km/h"  IHU
 SG_ ESP_VehicleSpeedVSOSigValidData : 30|1@0+ (1,0) [0|1] ""  IHU

BO_ 250 EMS_1: 8 CGW
 SG_ EMS_1_EngineSpeed : 7|16@0+ (0.25,0) [0|16383] ""  IHU
 SG_ EMS_1_NeutralGearSwitchSts : 60|1@0+ (1,0) [0|1] ""  IHU
 SG_ EMS_1_CruiseControlStatus : 38|2@0+ (1,0) [0|3] ""  IHU
 SG_ GasPedalPositionInvalidData : 39|1@0+ (1,0) [0|1] ""  IHU
 SG_ EMS_1_GasPedalPosition : 31|8@0+ (0.392,0) [0|99.96] ""  IHU

BO_ 932 CGW_ABS_ESP_18: 8 CGW
 SG_ ESP_18_CCO_Warn : 9|2@0+ (1,0) [0|3] ""  IHU
 SG_ ESP_18_CCO_TgtVel : 6|5@0+ (1,0) [0|30] ""  IHU
 SG_ CCO_Active : 1|2@0+ (1,0) [0|3] ""  IHU

BO_ 1414 IHU_AMP_2: 8 IHU
 SG_ IHU_AMP_2_Set_AMPENCReq : 17|2@0+ (1,0) [0|3] ""  CGW
 SG_ IHU_AMP_2__AMPA2BENCSound : 20|3@0+ (1,0) [0|7] ""  CGW
 SG_ IHU_AMP_2_SoundEffectMidtreble : 63|4@0+ (1,0) [0|15] ""  CGW
 SG_ IHU_AMP_2_SoundEffectBassMid : 59|4@0+ (1,0) [0|15] ""  CGW
 SG_ IHU_19_Set_HdrestSpkrMod : 40|3@0+ (1,0) [0|7] ""  CGW
 SG_ REQ_AMPA2BMediaSound : 9|2@0+ (1,0) [0|3] ""  CGW
 SG_ IHU_19_SetIHUAlarm : 53|6@0+ (1,0) [0|63] ""  CGW
 SG_ IHU_19_Set_AMPESEVol : 46|6@0+ (1,0) [0|63] ""  CGW
 SG_ IHU_19_Set_AMPWelVol : 36|6@0+ (1,0) [0|63] ""  CGW
 SG_ IHU_19_Set_AMPBTMediVol : 26|6@0+ (1,0) [0|63] ""  CGW
 SG_ IHU_19_REQ_AMPA2BMediSound : 29|3@0+ (1,0) [0|7] ""  CGW
 SG_ IHU_19_REQ_AMPA2BESESound : 31|2@0+ (1,0) [0|3] ""  CGW
 SG_ REQ_AMPA2BKeyTone : 22|2@0+ (1,0) [0|3] ""  CGW
 SG_ REQ_AMPA2BTTSSound : 15|2@0+ (1,0) [0|3] ""  CGW
 SG_ REQ_AMPA2BVRSound : 13|2@0+ (1,0) [0|3] ""  CGW
 SG_ REQ_AMPA2BNaviSound : 11|2@0+ (1,0) [0|3] ""  CGW
 SG_ Set_AMPMute : 7|2@0+ (1,0) [0|3] ""  CGW
 SG_ Set_AMPSpeedVolume : 5|3@0+ (1,0) [0|7] ""  CGW
 SG_ REQ_AMPA2BPhoneSound : 2|3@0+ (1,0) [0|7] ""  CGW

BO_ 1413 IHU_AMP_1: 8 IHU
 SG_ Set_AMPAlarmVolume : 63|4@0+ (1,0) [0|15] ""  CGW
 SG_ Set_AMPLoudness : 59|2@0+ (1,0) [0|3] ""  CGW
 SG_ Set_AMPLiveAcoustics : 57|2@0+ (1,0) [0|3] ""  CGW
 SG_ Set_AMPSoundFieldFader : 55|4@0+ (1,0) [0|15] ""  CGW
 SG_ Set_AMPSoundFieldBalance : 51|4@0+ (1,0) [0|15] ""  CGW
 SG_ Set_AMPSoundEffectTreble : 47|4@0+ (1,0) [0|15] ""  CGW
 SG_ Set_AMPSoundEffectMidrange : 43|4@0+ (1,0) [0|15] ""  CGW
 SG_ Set_AMPSoundEffectBass : 39|4@0+ (1,0) [0|15] ""  CGW
 SG_ Set_AMPSoundEffect : 35|4@0+ (1,0) [0|15] ""  CGW
 SG_ Set_AMPRestoreDefaults : 31|2@0+ (1,0) [0|3] ""  CGW
 SG_ Set_AMPDefaultVolume : 29|6@0+ (1,0) [0|63] ""  CGW
 SG_ Set_AMPSoundFocus : 23|3@0+ (1,0) [0|7] ""  CGW
 SG_ Set_AMPPhoneVolume : 20|5@0+ (1,0) [0|31] ""  CGW
 SG_ Set_AMPMediaVolume : 15|6@0+ (1,0) [0|63] ""  CGW
 SG_ Set_AMPKeyTone : 9|2@0+ (1,0) [0|3] ""  CGW
 SG_ Set_AMPVRVolume : 7|4@0+ (1,0) [0|15] ""  CGW
 SG_ Set_AMPNaviVolume : 3|4@0+ (1,0) [0|15] ""  CGW

BO_ 923 AMP_2: 8 CGW
 SG_ AMP_2_STAT_AMPENC : 55|2@0+ (1,0) [0|3] ""  IHU
 SG_ STAT_AMPA2BENCSound : 26|3@0+ (1,0) [0|7] ""  IHU
 SG_ AMP_2_STAT_SoundEffectMidtreble : 35|4@0+ (1,0) [0|15] ""  IHU
 SG_ AMP_2_STAT_AMPSoundEffectBassMid : 39|4@0+ (1,0) [0|15] ""  IHU
 SG_ STAT_A2B_MUTE_IN : 63|1@0+ (1,0) [0|1] ""  IHU
 SG_ STAT_AMPSlot7 : 62|1@0+ (1,0) [0|1] ""  IHU
 SG_ STAT_AMPSlot6 : 61|1@0+ (1,0) [0|1] ""  IHU
 SG_ STAT_AMPSlot4_5 : 60|1@0+ (1,0) [0|1] ""  IHU
 SG_ STAT_AMPSlot3 : 59|1@0+ (1,0) [0|1] ""  IHU
 SG_ STAT_AMPSlot2 : 58|1@0+ (1,0) [0|1] ""  IHU
 SG_ STAT_AMPSlot1 : 57|1@0+ (1,0) [0|1] ""  IHU
 SG_ STAT_AMPSlot0 : 56|1@0+ (1,0) [0|1] ""  IHU
 SG_ STAT_AMPA2BESESound : 53|2@0+ (1,0) [0|3] ""  IHU
 SG_ STAT_IHU19_AMPA2BMediSound : 51|3@0+ (1,0) [0|7] ""  IHU
 SG_ STAT_ICMAlarm : 48|1@0+ (1,0) [0|1] ""  IHU
 SG_ STAT_AMPA2BPhoneSound : 47|2@0+ (1,0) [0|3] ""  IHU
 SG_ STAT_AMPA2BTTSSound : 45|2@0+ (1,0) [0|3] ""  IHU
 SG_ STAT_AMPA2BNaviSound : 43|2@0+ (1,0) [0|3] ""  IHU
 SG_ STAT_AMPA2BKeyTone : 41|2@0+ (1,0) [0|3] ""  IHU
 SG_ STAT_AMPTEMP : 15|3@0+ (1,0) [0|7] ""  IHU
 SG_ EAMP_2_HdrestSpkrMod : 2|3@0+ (1,0) [0|7] ""  IHU
 SG_ STAT_AMPESEVol : 16|6@0+ (1,0) [0|63] ""  IHU
 SG_ STAT_AMPWelVol : 22|6@0+ (1,0) [0|63] ""  IHU
 SG_ STAT_AMPBTMediVol : 12|6@0+ (1,0) [0|63] ""  IHU
 SG_ STAT_AMPMute : 7|2@0+ (1,0) [0|3] ""  IHU
 SG_ STAT_AMPSpeedVolume : 5|3@0+ (1,0) [0|7] ""  IHU

BO_ 922 AMP_1: 8 CGW
 SG_ STAT_AMPAlarmVolume : 63|4@0+ (1,0) [0|15] ""  IHU
 SG_ STAT_AMPLoudness : 59|2@0+ (1,0) [0|3] ""  IHU
 SG_ STAT_AMPLiveAcoustics : 57|2@0+ (1,0) [0|3] ""  IHU
 SG_ STAT_AMPSoundFieldFader : 55|4@0+ (1,0) [0|15] ""  IHU
 SG_ STAT_AMPSoundFieldBalance : 51|4@0+ (1,0) [0|15] ""  IHU
 SG_ STAT_AMPSoundEffectTreble : 47|4@0+ (1,0) [0|15] ""  IHU
 SG_ STAT_AMPSoundEffectMidrange : 43|4@0+ (1,0) [0|15] ""  IHU
 SG_ STAT_AMPSoundEffectBass : 39|4@0+ (1,0) [0|15] ""  IHU
 SG_ STAT_AMPSoundEffect : 35|4@0+ (1,0) [0|15] ""  IHU
 SG_ STAT_AMPRestoreDefaults : 31|2@0+ (1,0) [0|3] ""  IHU
 SG_ STAT_AMPDefaultVolume : 29|6@0+ (1,0) [0|63] ""  IHU
 SG_ STAT_AMPSoundFocus : 23|3@0+ (1,0) [0|7] ""  IHU
 SG_ STAT_AMPPhoneVolume : 20|5@0+ (1,0) [0|31] ""  IHU
 SG_ STAT_AMPMediaVolume : 15|6@0+ (1,0) [0|63] ""  IHU
 SG_ STAT_AMPKeyTone : 9|2@0+ (1,0) [0|3] ""  IHU
 SG_ STAT_AMPVRVolume : 7|4@0+ (1,0) [0|15] ""  IHU
 SG_ STAT_AMPNaviVolume : 3|4@0+ (1,0) [0|15] ""  IHU

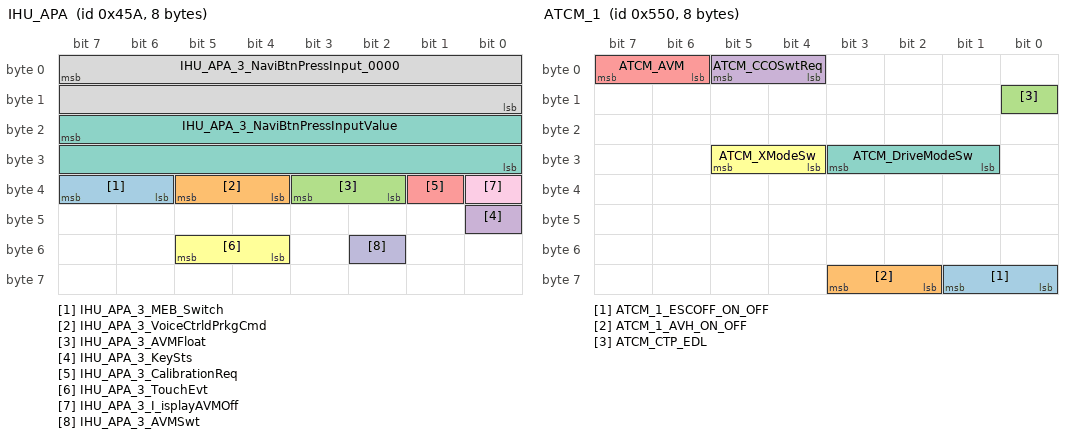
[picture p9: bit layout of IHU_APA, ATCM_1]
BO_ 1114 IHU_APA: 8 IHU
 SG_ IHU_APA_3_MEB_Switch : 39|2@0+ (1,0) [0|3] ""  CGW
 SG_ IHU_APA_3_VoiceCtrldPrkgCmd : 37|2@0+ (1,0) [0|3] ""  CGW
 SG_ IHU_APA_3_AVMFloat : 35|2@0+ (1,0) [0|3] ""  CGW
 SG_ IHU_APA_3_KeySts : 40|1@0+ (1,0) [0|1] "Bit"  CGW
 SG_ IHU_APA_3_CalibrationReq : 33|1@0+ (1,0) [0|1] "Bit"  CGW
 SG_ IHU_APA_3_TouchEvt : 53|2@0+ (1,0) [0|3] "Bit"  CGW
 SG_ IHU_APA_3_NaviBtnPressInputValue : 23|16@0+ (1,0) [0|65535] "Bit"  CGW
 SG_ IHU_APA_3_NaviBtnPressInput_0000 : 7|16@0+ (1,0) [0|65535] "Bit"  CGW
 SG_ IHU_APA_3_I_isplayAVMOff : 32|1@0+ (1,0) [0|1] "Bit"  CGW
 SG_ IHU_APA_3_AVMSwt : 50|1@0+ (1,0) [0|1] "Bit"  CGW

BO_ 804 MFS_2: 8 MFS
 SG_ MFS_Customize : 51|2@0+ (1,0) [0|3] ""  IHU
 SG_ MFS_Voice_SW : 47|2@0+ (1,0) [0|3] ""  IHU
 SG_ MFS_Mute_SW : 37|2@0+ (1,0) [0|3] ""  IHU
 SG_ MFS_Next_SW : 35|2@0+ (1,0) [0|3] ""  IHU
 SG_ MFS_Previous_SW : 33|2@0+ (1,0) [0|3] ""  IHU
 SG_ MFS_Volume_reduction_SW : 31|2@0+ (1,0) [0|3] ""  IHU
 SG_ MFS_Volume_increase_SW : 29|2@0+ (1,0) [0|3] ""  IHU
 SG_ MFS_OK_SW_324h : 25|2@0+ (1,0) [0|3] ""  IHU
 SG_ R_GearPlusSW : 17|2@0+ (1,0) [0|3] ""  IHU
 SG_ R_USER_SW : 11|2@0+ (1,0) [0|3] ""  IHU
 SG_ R_Checksum_CRC : 63|8@0+ (1,0) [0|255] ""  IHU
 SG_ R_MODE_SW : 15|2@0+ (1,0) [0|3] ""  IHU
 SG_ R_SPEECH_SW : 13|2@0+ (1,0) [0|3] ""  IHU
 SG_ R_MUTE_SW : 9|2@0+ (1,0) [0|3] ""  IHU
 SG_ R_RIGHT_SW : 7|2@0+ (1,0) [0|3] ""  IHU
 SG_ R_LEFT_SW : 5|2@0+ (1,0) [0|3] ""  IHU
 SG_ R_DW_SW : 3|2@0+ (1,0) [0|3] ""  IHU
 SG_ R_UP_SW : 1|2@0+ (1,0) [0|3] ""  IHU

BO_ 1360 ATCM_1: 8 CGW
 SG_ ATCM_1_ESCOFF_ON_OFF : 57|2@0+ (1,0) [0|3] ""  IHU
 SG_ ATCM_1_AVH_ON_OFF : 59|2@0+ (1,0) [0|3] ""  IHU,HUD
 SG_ ATCM_CTP_EDL : 8|1@0+ (1,0) [0|1] ""  IHU
 SG_ ATCM_CCOSwtReq : 5|2@0+ (1,0) [0|3] ""  IHU
 SG_ ATCM_AVM : 7|2@0+ (1,0) [0|3] ""  IHU
 SG_ ATCM_XModeSw : 29|2@0+ (1,0) [0|3] ""  IHU
 SG_ ATCM_DriveModeSw : 27|3@0+ (1,0) [0|7] ""  IHU

BO_ 1240 CGW_EMS_3_G: 8 CGW
 SG_ EMS_3_G_electric_fan_on_feedback : 31|8@0+ (1,0) [0|255] "%"  IHU

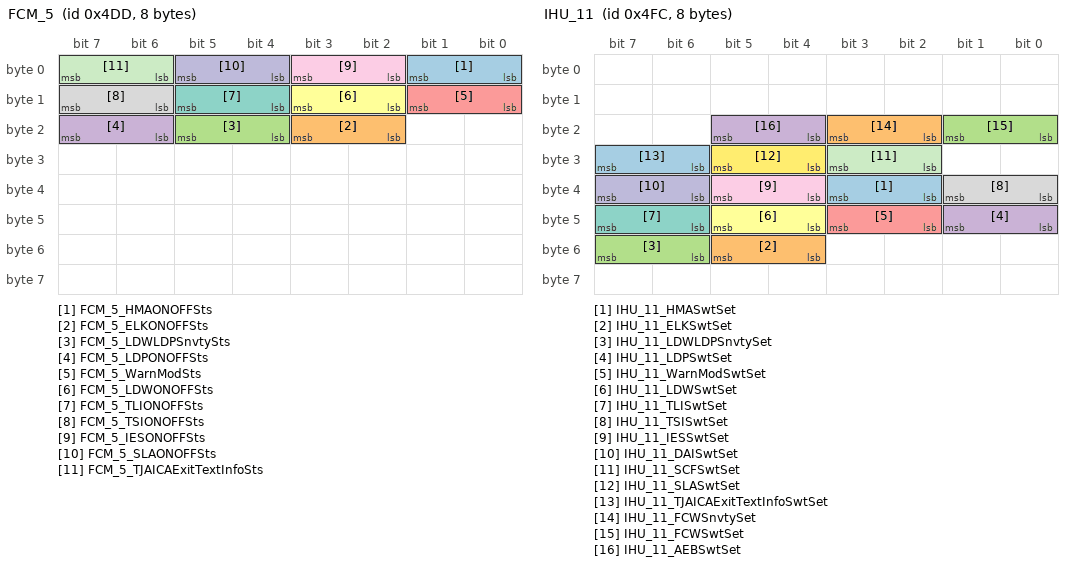
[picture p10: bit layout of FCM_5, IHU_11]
BO_ 1245 FCM_5: 8 CGW
 SG_ FCM_5_HMAONOFFSts : 1|2@0+ (1,0) [0|3] "bit"  IHU
 SG_ FCM_5_ELKONOFFSts : 19|2@0+ (1,0) [0|3] ""  IHU
 SG_ FCM_5_LDWLDPSnvtySts : 21|2@0+ (1,0) [0|3] ""  IHU
 SG_ FCM_5_LDPONOFFSts : 23|2@0+ (1,0) [0|3] ""  IHU
 SG_ FCM_5_WarnModSts : 9|2@0+ (1,0) [0|3] ""  IHU
 SG_ FCM_5_LDWONOFFSts : 11|2@0+ (1,0) [0|3] ""  IHU
 SG_ FCM_5_TLIONOFFSts : 13|2@0+ (1,0) [0|3] ""  IHU
 SG_ FCM_5_TSIONOFFSts : 15|2@0+ (1,0) [0|3] ""  IHU
 SG_ FCM_5_IESONOFFSts : 3|2@0+ (1,0) [0|3] ""  IHU
 SG_ FCM_5_SLAONOFFSts : 5|2@0+ (1,0) [0|3] ""  IHU
 SG_ FCM_5_TJAICAExitTextInfoSts : 7|2@0+ (1,0) [0|3] ""  IHU

BO_ 1276 IHU_11: 8 IHU
 SG_ IHU_11_HMASwtSet : 35|2@0+ (1,0) [0|3] "bit"  CGW
 SG_ IHU_11_ELKSwtSet : 53|2@0+ (1,0) [0|3] ""  CGW
 SG_ IHU_11_LDWLDPSnvtySet : 55|2@0+ (1,0) [0|3] ""  CGW
 SG_ IHU_11_LDPSwtSet : 41|2@0+ (1,0) [0|3] ""  CGW
 SG_ IHU_11_WarnModSwtSet : 43|2@0+ (1,0) [0|3] ""  CGW
 SG_ IHU_11_LDWSwtSet : 45|2@0+ (1,0) [0|3] ""  CGW
 SG_ IHU_11_TLISwtSet : 47|2@0+ (1,0) [0|3] ""  CGW
 SG_ IHU_11_TSISwtSet : 33|2@0+ (1,0) [0|3] ""  CGW
 SG_ IHU_11_IESSwtSet : 37|2@0+ (1,0) [0|3] ""  CGW
 SG_ IHU_11_DAISwtSet : 39|2@0+ (1,0) [0|3] ""  CGW
 SG_ IHU_11_SCFSwtSet : 27|2@0+ (1,0) [0|3] ""  CGW
 SG_ IHU_11_SLASwtSet : 29|2@0+ (1,0) [0|3] ""  CGW
 SG_ IHU_11_TJAICAExitTextInfoSwtSet : 31|2@0+ (1,0) [0|3] ""  CGW
 SG_ IHU_11_FCWSnvtySet : 19|2@0+ (1,0) [0|3] ""  CGW
 SG_ IHU_11_FCWSwtSet : 17|2@0+ (1,0) [0|3] ""  CGW
 SG_ IHU_11_AEBSwtSet : 21|2@0+ (1,0) [0|3] ""  CGW

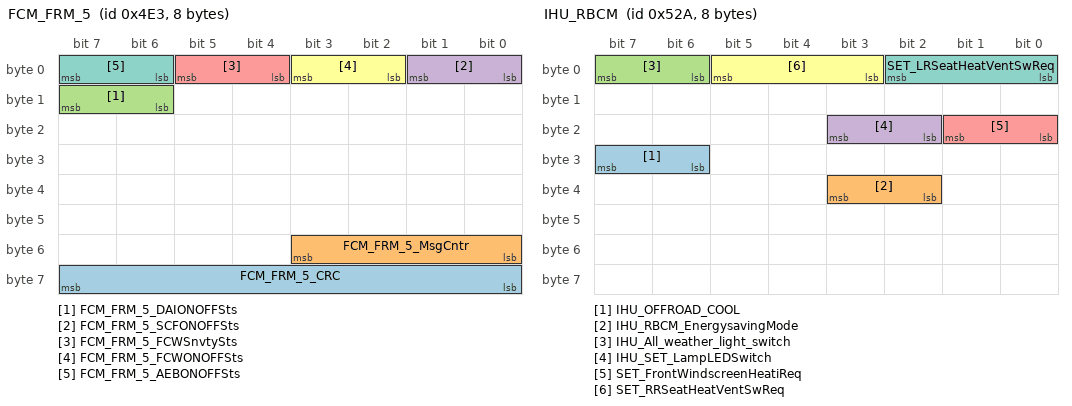
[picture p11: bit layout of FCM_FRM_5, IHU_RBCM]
BO_ 1251 FCM_FRM_5: 8 CGW
 SG_ FCM_FRM_5_CRC : 63|8@0+ (1,0) [0|255] ""  IHU
 SG_ FCM_FRM_5_MsgCntr : 51|4@0+ (1,0) [0|15] ""  IHU
 SG_ FCM_FRM_5_DAIONOFFSts : 15|2@0+ (1,0) [0|3] ""  IHU
 SG_ FCM_FRM_5_SCFONOFFSts : 1|2@0+ (1,0) [0|3] ""  IHU
 SG_ FCM_FRM_5_FCWSnvtySts : 5|2@0+ (1,0) [0|3] ""  IHU
 SG_ FCM_FRM_5_FCWONOFFSts : 3|2@0+ (1,0) [0|3] ""  IHU
 SG_ FCM_FRM_5_AEBONOFFSts : 7|2@0+ (1,0) [0|3] ""  IHU

BO_ 1262 RLC_1: 8 CGW
 SG_ LightShowSts : 22|5@0+ (1,0) [0|31] ""  IHU

BO_ 1322 IHU_RBCM: 8 IHU
 SG_ IHU_OFFROAD_COOL : 31|2@0+ (1,0) [0|3] ""  CGW
 SG_ IHU_RBCM_EnergysavingMode : 35|2@0+ (1,0) [0|3] ""  CGW
 SG_ IHU_All_weather_light_switch : 7|2@0+ (1,0) [0|3] "Bit"  CGW
 SG_ IHU_SET_LampLEDSwitch : 19|2@0+ (1,0) [0|3] "Bit"  CGW
 SG_ SET_FrontWindscreenHeatiReq : 17|2@0+ (1,0) [0|3] "Bit"  CGW
 SG_ SET_RRSeatHeatVentSwReq : 5|3@0+ (1,0) [0|7] "Bit"  CGW
 SG_ SET_LRSeatHeatVentSwReq : 2|3@0+ (1,0) [0|7] "Bit"  CGW

BO_ 295 YAS_1: 8 CGW
 SG_ YAS_1_YawRate : 39|16@0+ (0.01,-180) [-180|180] "Deg/sec"  IHU
 SG_ YAS_1_LateraAccaleleration : 23|16@0+ (0.001,-2) [-2|2] "G"  IHU

BO_ 1111 AVAS_1: 8 CGW
 SG_ AVAS_FunctionSts : 4|1@0+ (1,0) [0|1] ""  IHU

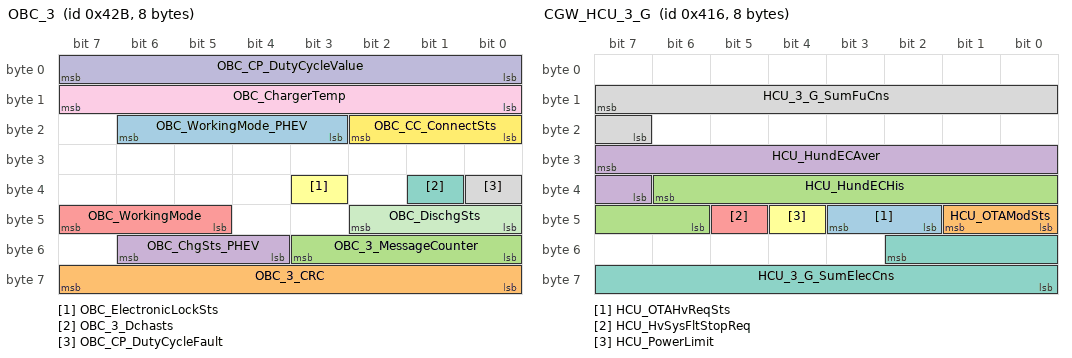
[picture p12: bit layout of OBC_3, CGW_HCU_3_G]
BO_ 1067 OBC_3: 8 CGW
 SG_ OBC_WorkingMode_PHEV : 22|4@0+ (1,0) [0|0] ""  IHU
 SG_ OBC_3_CRC : 63|8@0+ (1,0) [0|255] ""  IHU
 SG_ OBC_3_MessageCounter : 51|4@0+ (1,0) [0|15] ""  IHU
 SG_ OBC_ChgSts_PHEV : 54|3@0+ (1,0) [0|7] ""  IHU
 SG_ OBC_WorkingMode : 47|3@0+ (1,0) [0|7] ""  IHU
 SG_ OBC_ElectronicLockSts : 35|1@0+ (1,0) [0|1] ""  IHU
 SG_ OBC_3_Dchasts : 33|1@0+ (1,0) [0|1] ""  IHU
 SG_ OBC_CP_DutyCycleFault : 32|1@0+ (1,0) [0|1] ""  IHU
 SG_ OBC_ChargerTemp : 15|8@0+ (1,-40) [-40|213] ""  IHU
 SG_ OBC_CP_DutyCycleValue : 7|8@0+ (1,0) [0|100] "%"  IHU
 SG_ OBC_DischgSts : 42|3@0+ (1,0) [0|7] ""  IHU
 SG_ OBC_CC_ConnectSts : 18|3@0+ (1,0) [0|7] ""  IHU

BO_ 1057 HCU_EMS_2_G: 8 CGW
 SG_ LimitSpeedSts : 10|3@0+ (1,0) [0|7] ""  IHU
 SG_ CruiseLimitSpeedValue : 7|13@0+ (0.0625,0) [0|511.875] "Km/h"  IHU

BO_ 1046 CGW_HCU_3_G: 8 CGW
 SG_ HCU_OTAHvReqSts : 43|2@0+ (1,0) [0|3] ""  IHU
 SG_ HCU_OTAModSts : 41|2@0+ (1,0) [0|3] ""  IHU
 SG_ HCU_HundECHis : 38|9@0+ (0.1,0) [0|51] ""  IHU
 SG_ HCU_HundECAver : 31|9@0+ (0.1,0) [0|51] ""  IHU
 SG_ HCU_HvSysFltStopReq : 45|1@0+ (1,0) [0|1] ""  IHU
 SG_ HCU_PowerLimit : 44|1@0+ (1,0) [0|1] ""  IHU
 SG_ HCU_3_G_SumElecCns : 50|11@0+ (0.1,-100) [-100|100] "Kw.h/100km"  IHU
 SG_ HCU_3_G_SumFuCns : 15|9@0+ (0.1,0) [0|51] "L/100km"  IHU

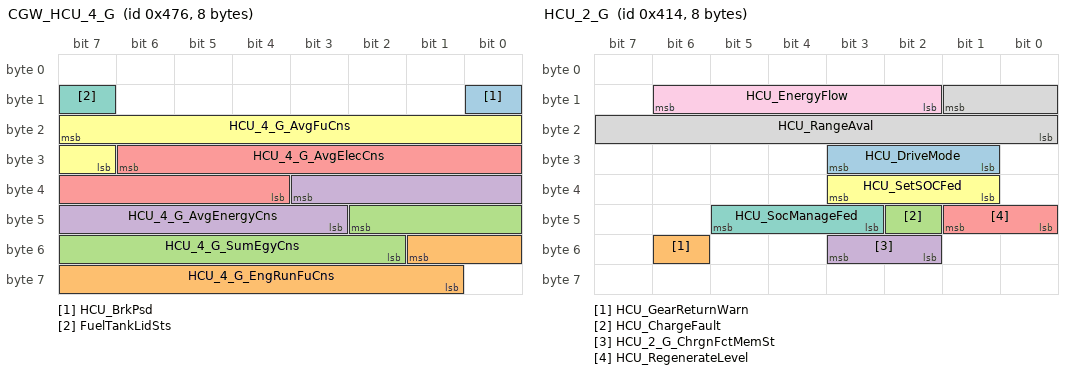
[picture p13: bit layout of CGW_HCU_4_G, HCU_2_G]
BO_ 1142 CGW_HCU_4_G: 8 CGW
 SG_ HCU_BrkPsd : 8|1@0+ (1,0) [0|1] "Bit"  IHU
 SG_ HCU_4_G_EngRunFuCns : 49|9@0+ (0.1,0) [0|50] "L/km"  IHU
 SG_ HCU_4_G_SumEgyCns : 42|9@0+ (0.1,-25) [-25|25] "L/100km"  IHU
 SG_ HCU_4_G_AvgEnergyCns : 35|9@0+ (0.1,-25) [-25|25] "L/100km"  IHU
 SG_ HCU_4_G_AvgElecCns : 30|11@0+ (0.1,-100) [-100|100] "kW.h/100km"  IHU
 SG_ HCU_4_G_AvgFuCns : 23|9@0+ (0.1,0) [0|50] "L/100km"  IHU
 SG_ FuelTankLidSts : 15|1@0+ (1,0) [0|1] ""  IHU

BO_ 1044 HCU_2_G: 8 CGW
 SG_ HCU_DriveMode : 27|3@0+ (1,0) [0|7] ""  IHU
 SG_ HCU_GearReturnWarn : 54|1@0+ (1,0) [0|1] ""  IHU
 SG_ HCU_ChargeFault : 42|1@0+ (1,0) [0|1] ""  IHU
 SG_ HCU_2_G_ChrgnFctMemSt : 51|2@0+ (1,0) [0|3] ""  IHU
 SG_ HCU_RegenerateLevel : 41|2@0+ (1,0) [0|3] ""  IHU
 SG_ HCU_SetSOCFed : 35|3@0+ (1,0) [0|7] ""  IHU
 SG_ HCU_SocManageFed : 45|3@0+ (1,0) [0|7] ""  IHU
 SG_ HCU_RangeAval : 9|10@0+ (1,0) [0|1022] "km"  IHU
 SG_ HCU_EnergyFlow : 14|5@0+ (1,0) [0|31] ""  IHU

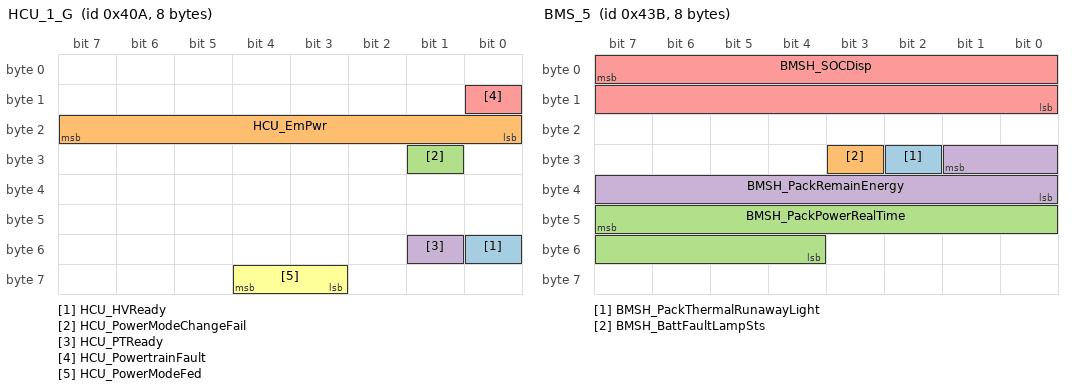
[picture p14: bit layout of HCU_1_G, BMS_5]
BO_ 1034 HCU_1_G: 8 CGW
 SG_ HCU_HVReady : 48|1@0+ (1,0) [0|1] ""  IHU
 SG_ HCU_EmPwr : 23|8@0+ (1,-128) [-100|100] "%"  IHU
 SG_ HCU_PowerModeChangeFail : 25|1@0+ (1,0) [0|1] ""  IHU
 SG_ HCU_PTReady : 49|1@0+ (1,0) [0|1] ""  IHU
 SG_ HCU_PowertrainFault : 8|1@0+ (1,0) [0|1] ""  IHU
 SG_ HCU_PowerModeFed : 60|2@0+ (1,0) [0|3] ""  IHU

BO_ 1183 CGW_BMS_24: 8 CGW
 SG_ BMSH_SOC : 7|16@0+ (0.01,0) [0|100] "%"  IHU
 SG_ BMSH_InsulationSts : 55|2@0+ (1,0) [0|3] ""  IHU
 SG_ BMSH_PackChargingThermalSt : 60|3@0+ (1,0) [0|7] ""  IHU
 SG_ BMSH_BattVolt : 39|16@0+ (0.05,0) [0|1000] "V"  IHU
 SG_ BMSH_BatteryCurrent : 23|16@0+ (0.05,-1600) [-700|700] "A"  IHU

BO_ 1472 BMS_20: 8 CGW
 SG_ BMSH_SingleDisChargeEnergy : 23|16@0+ (0.01,0) [0|655] "Kwh"  IHU
 SG_ BMSH_SingleChargeEnergy : 7|16@0+ (0.01,0) [0|655] "Kwh"  IHU

BO_ 1449 BMS_11: 8 CGW
 SG_ BMSH_CellVoltMin_Num : 31|8@0+ (1,0) [0|255] ""  IHU
 SG_ BMSH_CellVoltMax_Num : 23|8@0+ (1,0) [0|255] ""  IHU
 SG_ BMSH_CellVoltMin : 55|16@0+ (1,0) [0|5000] "mV"  IHU
 SG_ BMSH_CellVoltMax : 39|16@0+ (1,0) [0|5000] "mV"  IHU

BO_ 1448 BMS_10: 8 CGW
 SG_ BMSH_TempSensor_TempMinNum : 39|8@0+ (1,0) [0|255] ""  IHU
 SG_ BMSH_TempSensor_TempMaxNum : 23|8@0+ (1,0) [0|255] ""  IHU
 SG_ BMSH_TempSensor_MinTemp : 47|8@0+ (1,-40) [-40|123] "oC"  IHU
 SG_ BMSH_TempSensor_MaxTemp : 31|8@0+ (1,-40) [-40|123] "oC"  IHU

BO_ 1436 BMS_9: 8 CGW
 SG_ BMSH_InsulationResis : 55|16@0+ (10,0) [0|65533] "10k"  IHU

BO_ 1103 BMS_8: 8 CGW
 SG_ BMS_8_CC2Sts : 33|1@0+ (1,0) [0|1] ""  IHU
 SG_ BMSH_SOH : 47|8@0+ (1,0) [0|100] "%"  IHU
 SG_ BMS_8_PackDCChargingSt : 37|4@0+ (1,0) [0|15] "Bit"  IHU
 SG_ BMSH_LeftChargeTime : 31|10@0+ (1,0) [0|1022] "Minute"  IHU

BO_ 1083 BMS_5: 8 CGW
 SG_ BMSH_PackThermalRunawayLight : 26|1@0+ (1,0) [0|1] ""  IHU
 SG_ BMSH_BattFaultLampSts : 27|1@0+ (1,0) [0|1] ""  IHU
 SG_ BMSH_PackPowerRealTime : 47|12@0+ (1,-2000) [-400|400] "Kw"  IHU
 SG_ BMSH_PackRemainEnergy : 25|10@0+ (0.1,0) [0|100] "KwH"  IHU
 SG_ BMSH_SOCDisp : 7|16@0+ (0.01,0) [0|100] "%"  IHU

BO_ 2047 TEST_MSG_FOR_FACTORY: 8 CGW
 SG_ Start_Aging : 7|8@0+ (1,0) [0|1] ""  IHU

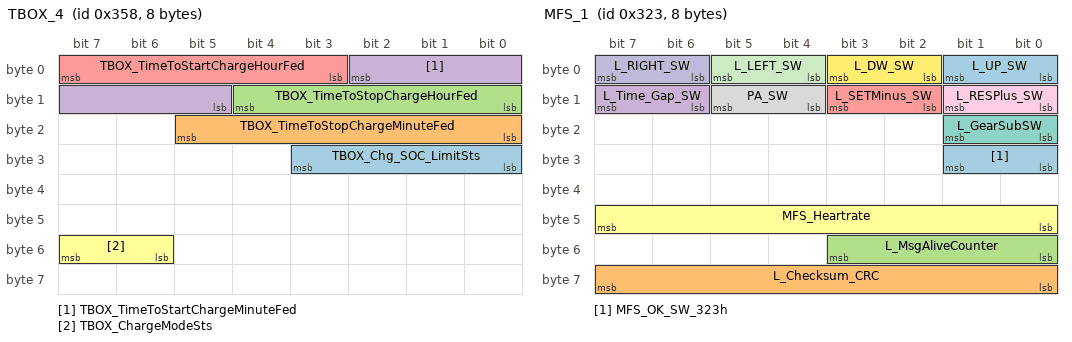
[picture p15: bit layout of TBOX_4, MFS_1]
BO_ 856 TBOX_4: 8 CGW
 SG_ TBOX_Chg_SOC_LimitSts : 27|4@0+ (1,0) [0|15] ""  IHU
 SG_ TBOX_TimeToStopChargeMinuteFed : 21|6@0+ (1,0) [0|59] "Minute"  IHU
 SG_ TBOX_TimeToStopChargeHourFed : 12|5@0+ (1,0) [0|23] "h"  IHU
 SG_ TBOX_TimeToStartChargeMinuteFed : 2|6@0+ (1,0) [0|59] "minute"  IHU
 SG_ TBOX_TimeToStartChargeHourFed : 7|5@0+ (1,0) [0|23] "h"  IHU
 SG_ TBOX_ChargeModeSts : 55|2@0+ (1,0) [0|3] ""  IHU

BO_ 1314 TBOX_3: 8 CGW
 SG_ HCU_V2l_IntlDisChgBck : 23|2@0+ (1,0) [0|3] ""  IHU
 SG_ TBOX_3_BatteryPowerLimit : 1|2@0+ (1,0) [0|3] "Bit"  IHU

BO_ 1025 CGW_WSD_1: 4 CGW
 SG_ Welcome_OutsoundSts : 3|2@0+ (1,0) [0|3] "Bit"  IHU
 SG_ Person_RemindSts : 1|1@0+ (1,0) [0|1] ""  IHU
 SG_ Welcome_Outsound_SwitchSts : 0|1@0+ (1,0) [0|1] "Bit"  IHU

BO_ 803 MFS_1: 8 MFS
 SG_ MFS_OK_SW_323h : 25|2@0+ (1,0) [0|3] ""  IHU
 SG_ L_Checksum_CRC : 63|8@0+ (1,0) [0|255] ""  IHU
 SG_ L_MsgAliveCounter : 51|4@0+ (1,0) [0|15] ""  IHU
 SG_ L_Time_Gap_SW : 15|2@0+ (1,0) [0|3] "bit"  IHU
 SG_ L_SETMinus_SW : 11|2@0+ (1,0) [0|3] "bit"  IHU
 SG_ MFS_Heartrate : 47|8@0+ (1,0) [0|255] ""  IHU
 SG_ L_GearSubSW : 17|2@0+ (1,0) [0|3] "bit"  IHU
 SG_ PA_SW : 13|2@0+ (1,0) [0|3] "bit"  IHU
 SG_ L_RESPlus_SW : 9|2@0+ (1,0) [0|3] "bit"  IHU
 SG_ L_RIGHT_SW : 7|2@0+ (1,0) [0|3] "bit"  IHU
 SG_ L_LEFT_SW : 5|2@0+ (1,0) [0|3] "bit"  IHU
 SG_ L_DW_SW : 3|2@0+ (1,0) [0|3] "bit"  IHU
 SG_ L_UP_SW : 1|2@0+ (1,0) [0|3] "bit"  IHU

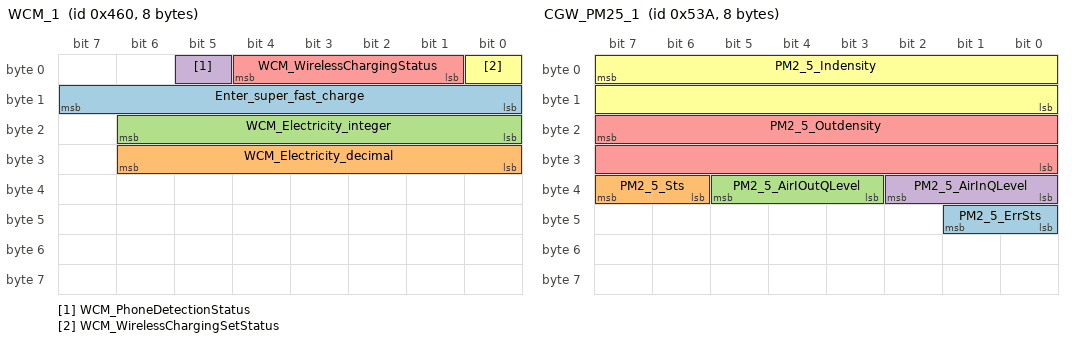
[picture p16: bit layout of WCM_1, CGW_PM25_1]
BO_ 1120 WCM_1: 8 WCM
 SG_ Enter_super_fast_charge : 15|8@0+ (1,0) [0|255] "Bit"  IHU
 SG_ WCM_Electricity_decimal : 30|7@0+ (1,0) [0|100] "%"  IHU
 SG_ WCM_Electricity_integer : 22|7@0+ (1,0) [0|100] "%"  IHU
 SG_ WCM_PhoneDetectionStatus : 5|1@0+ (1,0) [0|1] "Bit"  IHU
 SG_ WCM_WirelessChargingStatus : 4|4@0+ (1,0) [0|15] "Bit"  IHU
 SG_ WCM_WirelessChargingSetStatus : 0|1@0+ (1,0) [0|1] "Bit"  IHU

BO_ 1338 CGW_PM25_1: 8 CGW
 SG_ PM2_5_ErrSts : 41|2@0+ (1,0) [0|3] "Bit"  IHU
 SG_ PM2_5_Sts : 39|2@0+ (1,0) [0|3] "Bit"  IHU
 SG_ PM2_5_AirIOutQLevel : 37|3@0+ (1,0) [0|7] "Bit"  IHU
 SG_ PM2_5_AirInQLevel : 34|3@0+ (1,0) [0|7] "Bit"  IHU
 SG_ PM2_5_Outdensity : 23|16@0+ (1,0) [0|999] "Ug/m^3"  IHU
 SG_ PM2_5_Indensity : 7|16@0+ (1,0) [0|999] "Ug/m^3"  IHU

BO_ 787 CGW_ABS_ESP_3: 8 CGW
 SG_ IPB_RHFWheelSpeedRPM : 23|16@0+ (0.0625,0) [0|4095.9375] "Rpm"  IHU
 SG_ IPB_LHFWheelSpeedRPM : 7|16@0+ (0.0625,0) [0|4095.9375] "Rpm"  IHU
 SG_ ESP_3_AVHSts : 53|2@0+ (1,0) [0|3] "Bit"  IHU

BO_ 1136 CGW_YAS_2: 8 CGW
 SG_ YAS_2_LongitudinalAcceleration : 23|16@0+ (0.001,-2) [-2|2] "G"  IHU

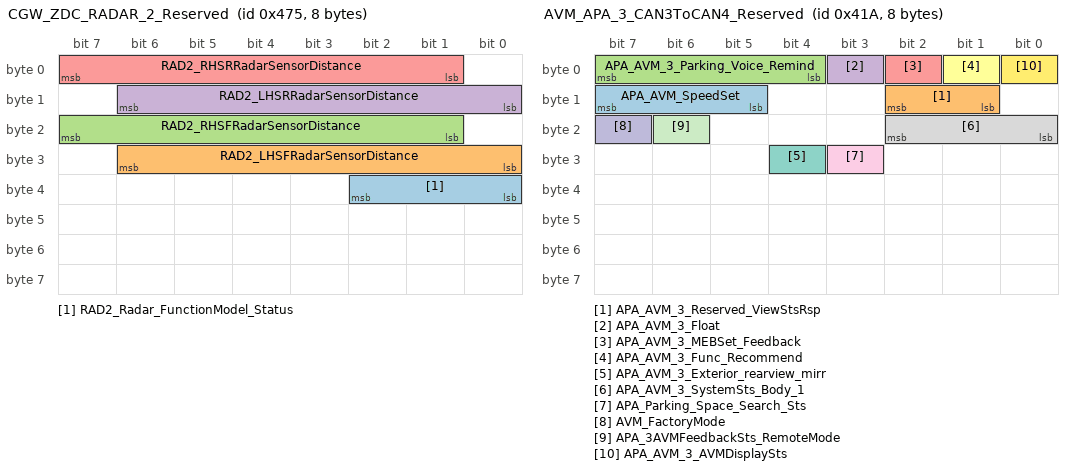
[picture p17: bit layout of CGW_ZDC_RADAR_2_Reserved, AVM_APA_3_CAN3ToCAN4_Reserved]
BO_ 1141 CGW_ZDC_RADAR_2_Reserved: 8 CGW
 SG_ RAD2_Radar_FunctionModel_Status : 34|3@0+ (1,0) [0|7] "bit"  IHU
 SG_ RAD2_LHSFRadarSensorDistance : 30|7@0+ (5,30) [30|180] "Cm"  IHU
 SG_ RAD2_RHSFRadarSensorDistance : 23|7@0+ (5,30) [30|180] "Cm"  IHU
 SG_ RAD2_LHSRRadarSensorDistance : 14|7@0+ (5,30) [30|180] "Cm"  IHU
 SG_ RAD2_RHSRRadarSensorDistance : 7|7@0+ (5,30) [30|180] "Cm"  IHU

BO_ 1050 AVM_APA_3_CAN3ToCAN4_Reserved: 8 CGW
 SG_ APA_AVM_SpeedSet : 15|3@0+ (1,0) [0|7] ""  IHU
 SG_ APA_AVM_3_Reserved_ViewStsRsp : 10|2@0+ (1,0) [0|3] ""  IHU
 SG_ APA_AVM_3_Parking_Voice_Remind : 7|4@0+ (1,0) [0|15] ""  IHU
 SG_ APA_AVM_3_Float : 3|1@0+ (1,0) [0|1] ""  IHU
 SG_ APA_AVM_3_MEBSet_Feedback : 2|1@0+ (1,0) [0|1] ""  IHU
 SG_ APA_AVM_3_Func_Recommend : 1|1@0+ (1,0) [0|1] ""  IHU
 SG_ APA_AVM_3_Exterior_rearview_mirr : 28|1@0+ (1,0) [0|1] ""  IHU
 SG_ APA_AVM_3_SystemSts_Body_1 : 18|3@0+ (1,0) [0|7] "Bit"  IHU
 SG_ APA_Parking_Space_Search_Sts : 27|1@0+ (1,0) [0|1] "Bit"  IHU
 SG_ AVM_FactoryMode : 23|1@0+ (1,0) [0|1] "Bit"  IHU
 SG_ APA_3AVMFeedbackSts_RemoteMode : 22|1@0+ (1,0) [0|1] "Bit"  IHU
 SG_ APA_AVM_3_AVMDisplaySts : 0|1@0+ (1,0) [0|1] "Bit"  IHU

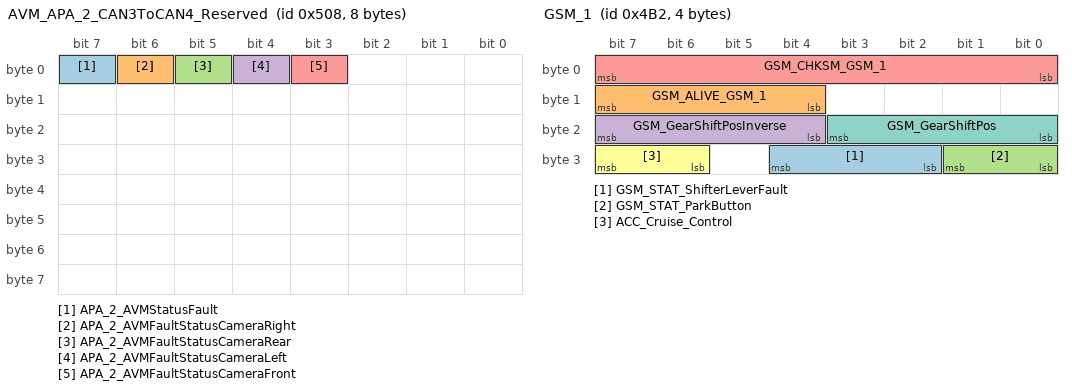
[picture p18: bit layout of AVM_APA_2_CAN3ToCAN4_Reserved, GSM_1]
BO_ 1288 AVM_APA_2_CAN3ToCAN4_Reserved: 8 CGW
 SG_ APA_2_AVMStatusFault : 7|1@0+ (1,0) [0|1] "Bit"  IHU
 SG_ APA_2_AVMFaultStatusCameraRight : 6|1@0+ (1,0) [0|1] "Bit"  IHU
 SG_ APA_2_AVMFaultStatusCameraRear : 5|1@0+ (1,0) [0|1] "Bit"  IHU
 SG_ APA_2_AVMFaultStatusCameraLeft : 4|1@0+ (1,0) [0|1] "Bit"  IHU
 SG_ APA_2_AVMFaultStatusCameraFront : 3|1@0+ (1,0) [0|1] "Bit"  IHU

BO_ 773 CGW_FRM_3: 8 CGW
 SG_ FRM_3_CRC : 63|8@0+ (1,0) [0|255] "Bit"  IHU
 SG_ FRM_3_MessageCounter : 51|4@0+ (1,0) [0|15] "Bit"  IHU
 SG_ FRM_3_AEB_ON_OFF_Sts : 53|1@0+ (1,0) [0|1] "Bit"  IHU
 SG_ FRM_3_FCW_OPTION_Sts : 55|2@0+ (1,0) [0|3] "Bit"  IHU
 SG_ FRM_3_FCW_ON_OFF_Sts : 40|1@0+ (1,0) [0|1] "Bit"  IHU
 SG_ FRM_3_FCW_PreWarning : 42|1@0+ (1,0) [0|1] "Bit"  IHU
 SG_ FRM_3_DistanceWarning : 43|1@0+ (1,0) [0|1] "Bit"  IHU
 SG_ FRM_3_AEBMode : 46|3@0+ (1,0) [0|7] "Bit"  IHU
 SG_ FRM_3_FCWMode : 33|3@0+ (1,0) [0|7] "Bit"  IHU
 SG_ FRM_3_Obiect_Dx : 29|8@0+ (0.5,0) [0|127] "M"  IHU
 SG_ FRM_3_ACCMode : 37|4@0+ (1,0) [0|15] "Bit"  IHU
 SG_ FRM_3_TimeGapSet_ICM : 17|2@0+ (1,0) [0|3] "Bit"  IHU
 SG_ FRM_3_TakeOverReq : 18|1@0+ (1,0) [0|1] "Bit"  IHU
 SG_ FRM_3_Textinfo : 23|5@0+ (1,0) [0|31] "Bit"  IHU
 SG_ FRM_3_FrontObject_Type : 11|3@0+ (1,0) [0|7] "Bit"  IHU
 SG_ FRM_3_ObjValid : 8|1@0+ (1,0) [0|1] "Bit"  IHU
 SG_ FRM_3_DxTarObj : 14|3@0+ (1,0) [0|7] "Bit"  IHU
 SG_ FRM_3_VSetDis : 7|9@0+ (0.5,0) [0|255.5] "KPH"  IHU

BO_ 1241 CGW_EMS_4_G: 8 CGW
 SG_ FuelTankLidSystemFailureSts : 18|1@0+ (1,0) [0|1] ""  IHU
 SG_ FuelTankPressureConditionReached : 20|2@0+ (1,0) [0|3] ""  IHU

BO_ 632 CGW_EMS_4: 8 CGW
 SG_ EMS_4_IntakeAirPressure : 63|8@0+ (1,0) [0|254] "Kpa"  IHU
 SG_ EMS_4_EngineSts : 14|1@0+ (1,0) [0|1] "Bit"  IHU

BO_ 1202 GSM_1: 4 CGW
 SG_ GSM_STAT_ShifterLeverFault : 28|3@0+ (1,0) [0|7] ""  IHU
 SG_ GSM_ALIVE_GSM_1 : 15|4@0+ (1,0) [0|15] ""  IHU
 SG_ GSM_STAT_ParkButton : 25|2@0+ (1,0) [0|3] ""  IHU
 SG_ GSM_GearShiftPosInverse : 23|4@0+ (1,0) [0|15] ""  IHU
 SG_ GSM_CHKSM_GSM_1 : 7|8@0+ (1,0) [0|255] ""  IHU
 SG_ ACC_Cruise_Control : 31|2@0+ (1,0) [0|3] "Bit"  IHU
 SG_ GSM_GearShiftPos : 19|4@0+ (1,0) [0|15] "Bit"  IHU

BO_ 1507 CGW_DHM_1: 8 CGW
 SG_ DHM_1_Doorkonb_time_freeback : 35|2@0+ (1,0) [0|3] "bit"  IHU

BO_ 1518 CGW_CEM_DHM_Control: 8 CGW
 SG_ CEM_DHM_handlelockswitchfeedback : 4|1@0+ (1,0) [0|1] "bit"  IHU
 SG_ CEM_DHM_handleunlockswitchfeedba : 3|1@0+ (1,0) [0|1] "bit"  IHU

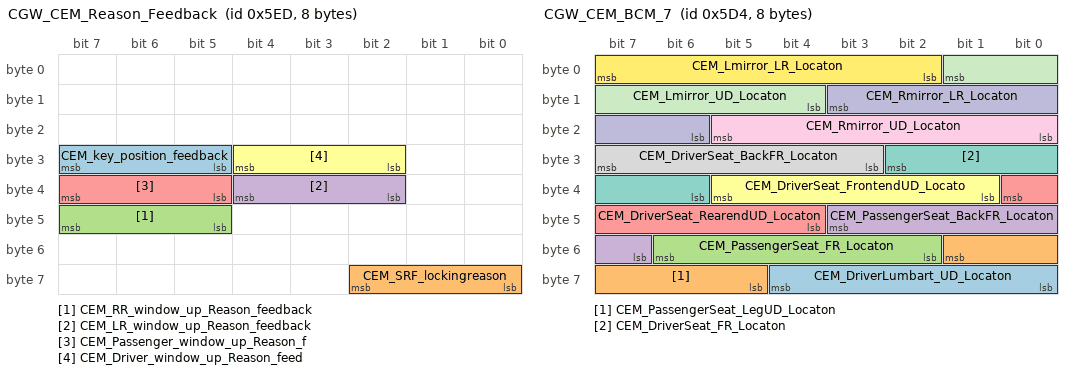
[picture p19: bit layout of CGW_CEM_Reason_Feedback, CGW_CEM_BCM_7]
BO_ 1517 CGW_CEM_Reason_Feedback: 8 CGW
 SG_ CEM_key_position_feedback : 31|3@0+ (1,0) [0|7] ""  IHU
 SG_ CEM_SRF_lockingreason : 58|3@0+ (1,0) [0|7] "Bit"  IHU
 SG_ CEM_RR_window_up_Reason_feedback : 47|3@0+ (1,0) [0|7] "Bit"  IHU
 SG_ CEM_LR_window_up_Reason_feedback : 36|3@0+ (1,0) [0|7] "Bit"  IHU
 SG_ CEM_Passenger_window_up_Reason_f : 39|3@0+ (1,0) [0|7] "Bit"  IHU
 SG_ CEM_Driver_window_up_Reason_feed : 28|3@0+ (1,0) [0|7] "Bit"  IHU

BO_ 1504 CGW_CEM_SRF: 8 CGW
 SG_ CEM_SRFclosingConditions : 15|4@0+ (1,0) [0|15] ""  IHU
 SG_ CEM_Abat_VentCMDSts : 7|4@0+ (1,0) [0|15] "Bit"  IHU
 SG_ CEM_PSRFCMDSts : 3|4@0+ (1,0) [0|15] "Bit"  IHU

BO_ 1168 CGW_CEM_ALM_1: 8 CGW
 SG_ ALM_1_SET_LampLEDSwitch : 26|1@0+ (1,0) [0|1] "Bit"  IHU
 SG_ ALM_1_NavigationSwitch : 25|1@0+ (1,0) [0|1] "Bit"  IHU
 SG_ CEM_ALM_1_SceneMode_ControlSwitc : 29|2@0+ (1,0) [0|3] "Bit"  IHU
 SG_ CEM_ALM_1_DeletePeronalSet_FB : 63|4@0+ (1,0) [0|15] "Bit"  IHU
 SG_ CEM_ALM_1_PersonalBeamEn : 59|2@0+ (1,0) [0|3] "Bit"  IHU
 SG_ CEM_ALM_1_PersonalSeatEn : 57|2@0+ (1,0) [0|3] "Bit"  IHU
 SG_ CEM_ALM_1_Seat_Set_Status : 55|4@0+ (1,0) [0|15] "Bit"  IHU
 SG_ CEM_ALM_1_Seat_Set_Pop_Up : 51|2@0+ (1,0) [0|3] "Bit"  IHU
 SG_ CEM_ALM_1_Wash_Car_Status : 49|2@0+ (1,0) [0|3] "Bit"  IHU
 SG_ CEM_ALM_1_PersonalSetSts : 38|1@0+ (1,0) [0|1] "Bit"  IHU
 SG_ CEM_ALM_1_STAT_WelcomeWaterLamp : 37|2@0+ (1,0) [0|3] "Bit"  IHU
 SG_ CEM_ALM_1_STAT_AssociatedWithDri : 35|2@0+ (1,0) [0|3] "Bit"  IHU
 SG_ CEM_ALM_1_STAT_Music : 33|2@0+ (1,0) [0|3] "Bit"  IHU
 SG_ CEM_ALM_1_STAT_Apiluminance : 19|4@0+ (1,0) [0|15] "Bit"  IHU
 SG_ CEM_ALM_1_STAT_Static_Colour : 23|4@0+ (1,0) [0|15] "Bit"  IHU
 SG_ CEM_ALM_1_STAT_StaticEffect : 12|3@0+ (1,0) [0|7] "Bit"  IHU
 SG_ CEM_ALM_1_STAT_ControlSwitch : 9|2@0+ (1,0) [0|3] "Bit"  IHU
 SG_ CEM_ALM_1_STAT_DMSMonitoring : 31|2@0+ (1,0) [0|3] "Bit"  IHU
 SG_ CEM_ALM_1_STAT_PM2_5Monitoring : 14|2@0+ (1,0) [0|3] "Bit"  IHU
 SG_ CEM_ALM_1_STAT_DriveApiluminance : 0|2@0+ (1,0) [0|3] "Bit"  IHU
 SG_ CEM_ALM_1_STAT_64Colour : 7|7@0+ (1,0) [0|64] "Bit"  IHU

BO_ 936 CGW_CEM_BCM_13_Reserved: 8 CGW
 SG_ BCM_13_EBS_SOC : 23|8@0+ (1,0) [0|255] "%"  IHU

BO_ 1492 CGW_CEM_BCM_7: 8 CGW
 SG_ CEM_DriverLumbart_UD_Locaton : 60|5@0+ (5,0) [0|100] "%"  IHU
 SG_ CEM_PassengerSeat_LegUD_Locaton : 49|5@0+ (5,0) [0|100] "%"  IHU
 SG_ CEM_PassengerSeat_FR_Locaton : 54|5@0+ (5,0) [0|100] "%"  IHU
 SG_ CEM_PassengerSeat_BackFR_Locaton : 43|5@0+ (5,0) [0|100] "%"  IHU
 SG_ CEM_DriverSeat_RearendUD_Locaton : 32|5@0+ (5,0) [0|100] "%"  IHU
 SG_ CEM_DriverSeat_FrontendUD_Locato : 37|5@0+ (5,0) [0|100] "%"  IHU
 SG_ CEM_DriverSeat_FR_Locaton : 26|5@0+ (5,0) [0|100] "%"  IHU
 SG_ CEM_DriverSeat_BackFR_Locaton : 31|5@0+ (5,0) [0|100] "%"  IHU
 SG_ CEM_Rmirror_UD_Locaton : 21|6@0+ (2,-2) [0|100] "%"  IHU
 SG_ CEM_Rmirror_LR_Locaton : 11|6@0+ (2,-2) [0|100] "%"  IHU
 SG_ CEM_Lmirror_UD_Locaton : 1|6@0+ (2,-2) [0|100] "%"  IHU
 SG_ CEM_Lmirror_LR_Locaton : 7|6@0+ (2,-2) [0|100] "%"  IHU

BO_ 1476 CGW_CEM_BCM_6: 8 CGW
 SG_ CEM_Psngrseat_Location : 55|4@0+ (1,0) [0|15] "bit"  IHU
 SG_ CEM_PassengerSeat_LegUDSts : 31|2@0+ (1,0) [0|3] "bit"  IHU
 SG_ CEM_PassengerSeat_BackFRSts : 39|2@0+ (1,0) [0|3] "bit"  IHU
 SG_ CEM_PassengerSeat_FRSts : 29|2@0+ (1,0) [0|3] "bit"  IHU
 SG_ CEM_massagemodeSts : 60|3@0+ (1,0) [0|4] "Bit"  IHU
 SG_ CEM_passageVibrationSts : 57|2@0+ (1,0) [0|3] "Bit"  IHU
 SG_ CEM_Passenger_massageSts : 51|1@0+ (1,0) [0|1] "Bit"  IHU
 SG_ CEM_DriverLumbart_FR_Locaton : 50|5@0+ (5,0) [0|100] "%"  IHU
 SG_ CEM_Mirror_Driverseat_Location : 47|5@0+ (1,0) [0|21] "Bit"  IHU
 SG_ CEM_UnderVoltageSts : 61|1@0+ (1,0) [0|1] "bit"  IHU
 SG_ CEM_RearWiper_SwitchSts : 42|1@0+ (1,0) [0|1] "bit"  IHU
 SG_ CEM_Wiper_MaintenanceSts : 41|1@0+ (1,0) [0|1] "bit"  IHU
 SG_ CEM_Mirror_Fold_SwitchSts : 40|1@0+ (1,0) [0|1] "bit"  IHU
 SG_ CEM_IPM__FRSeatHeatVentSwSts : 37|3@0+ (1,0) [0|7] "bit"  IHU
 SG_ CEM_IPM_FLSeatHeatVentSwSts : 34|3@0+ (1,0) [0|7] "bit"  IHU
 SG_ CEM_DriverLumbart_UDSts : 27|2@0+ (1,0) [0|3] "bit"  IHU
 SG_ CEM_DriverLumbart_FRSts : 25|2@0+ (1,0) [0|3] "bit"  IHU
 SG_ CEM_DriverSeat_RearendUDSts : 23|2@0+ (1,0) [0|3] "bit"  IHU
 SG_ CEM_DriverSeat_FrontendUDSts : 21|2@0+ (1,0) [0|3] "bit"  IHU
 SG_ CEM_DriverSeat_FRSts : 19|2@0+ (1,0) [0|3] "bit"  IHU
 SG_ CEM_DriverSeat_BackFRSts : 17|2@0+ (1,0) [0|3] "bit"  IHU
 SG_ CEM_MirrorFlip_CFGSts : 15|2@0+ (1,0) [0|3] "bit"  IHU
 SG_ CEM_RightMirrorCtrlSts : 13|3@0+ (1,0) [0|7] "bit"  IHU
 SG_ CEM_LeftMirrorCtrlSts : 10|3@0+ (1,0) [0|7] "bit"  IHU
 SG_ CEM_RHRdoor_buttonsts : 5|1@0+ (1,0) [0|1] "bit"  IHU
 SG_ CEM_LHRdoor_buttonsts : 4|1@0+ (1,0) [0|1] "bit"  IHU
 SG_ CEM_PsngrDoor_buttonsts : 3|1@0+ (1,0) [0|1] "bit"  IHU
 SG_ CEM_Smart_HighBeamSts : 2|1@0+ (1,0) [0|1] "bit"  IHU
 SG_ CEM_HighBeam_AdjustSts : 1|2@0+ (1,0) [0|3] "bit"  IHU

CM_ BO_ 3221225472 "This is a message for not used signals, created by Vector CANdb++ DBC OLE DB Provider.";
CM_ SG_ 3221225472 SET_Rmirror_UD_Locaton "右后视镜上下调节指定位置
Feedback:0x5D4：CEM_Rmirror_UD_Locaton";
CM_ SG_ 3221225472 SET_Rmirror_LR_Locaton "右后视镜左右调节指定位置
Feedback:0x5D4：CEM_Rmirror_LR_Locaton";
CM_ SG_ 3221225472 SET_Lmirror_UD_Locaton "左后视镜上下调节指定位置
Feedback:0x5D4：CEM_Lmirror_UD_Locaton";
CM_ SG_ 3221225472 SET_Lmirror_LR_Locaton "左后视镜左右调节指定位置
Feedback:0x5D4：CEM_Lmirror_LR_Locaton";
CM_ SG_ 3221225472 HCU_HundECHis "历史平均电量消耗";
CM_ SG_ 3221225472 HCU_HundECAver "当前平均电量消耗";
CM_ SG_ 3221225472 CEM_IPM_FRSeatHeatVentSwSts "副驾驶座椅通风加热状态
(主项目使用）";
CM_ SG_ 3221225472 CEM_IPM_FLSeatHeatVentSwSts "主驾驶座椅通风加热状态
（主项目使用）";
CM_ SG_ 3221225472 IHU_StopChargeSW "充电中止";
CM_ SG_ 1262 LightShowSts "灯光秀过程/状态
增加灯光秀状态反馈的逻辑：对于灯光秀反馈的ID：0x4EE是周期信号，在灯光秀没有启动之前一直反馈的是默认值(0x0)。
当灯光秀启动之后就会反馈灯光秀开启状态(0x1)，当灯光秀结束之后就会反馈灯光秀结束的状态，灯光秀结束（包含灯光秀正常结束和打断的结束）之后会持续反馈2s灯光秀结束状态(0x2)，
中途开启了任何灯光秀就会重新反馈开启的状态，在2s之内没有在收到灯光秀开启指令之后进行反馈默认值。";
CM_ BO_ 1322 "JX65国际二阶段用";
CM_ SG_ 1322 IHU_All_weather_light_switch "全天候灯激活开关";
CM_ SG_ 1322 IHU_SET_LampLEDSwitch "氛围灯照明开关";
CM_ SG_ 1322 SET_FrontWindscreenHeatiReq "前风挡电加热请求";
CM_ SG_ 1322 SET_RRSeatHeatVentSwReq "右后座位温度设置";
CM_ SG_ 1322 SET_LRSeatHeatVentSwReq "左后座位温度设置";
CM_ BO_ 295 "横向加速度";
CM_ SG_ 295 YAS_1_LateraAccaleleration "横向加速度";
CM_ SG_ 1111 AVAS_FunctionSts "行人提示设置反馈";
CM_ SG_ 1067 OBC_CC_ConnectSts "充电枪连接状态";
CM_ SG_ 1057 LimitSpeedSts "主动限速功能状态
Off:关闭主动限速功能
Standby:打开主动限速功能但未激活
Overspeed:限速功能激活后当前车速超过限速值
Limit:限速功能激活
Cancel:暂时退出主动限速状态
Kickdown:油门踩到底";
CM_ SG_ 1057 CruiseLimitSpeedValue "巡航设定值/限速值";
CM_ SG_ 1046 HCU_3_G_SumFuCns "SumFuelConsumption
自清零后累计百公里油耗 L/100km";
CM_ SG_ 1142 HCU_4_G_SumEgyCns "Sum Energy Consumption
自清零后累计百公里能耗 L/100km";
CM_ SG_ 1142 HCU_4_G_AvgEnergyCns "Avg Energy Consumption
近50km平均百公里能耗 L/100km";
CM_ SG_ 1142 HCU_4_G_AvgElecCns "Avg Electric Consumption
近50km平均百公里电耗 kW.h/100km";
CM_ SG_ 1142 HCU_4_G_AvgFuCns "Avg Fuel Consumption
近50km平均百公里油耗 L/100km";
CM_ SG_ 1142 FuelTankLidSts "加油小门开关状态";
CM_ SG_ 1044 HCU_RegenerateLevel "能量回收等级反馈";
CM_ SG_ 1044 HCU_SetSOCFed "SOC设置反馈";
CM_ SG_ 1044 HCU_SocManageFed "电量模式反馈";
CM_ SG_ 1044 HCU_RangeAval "纯电续航里程";
CM_ SG_ 1044 HCU_EnergyFlow "能量流";
CM_ SG_ 1034 HCU_PowertrainFault "动力系统故障";
CM_ SG_ 1034 HCU_PowerModeFed "动力模式反馈";
CM_ SG_ 1183 BMSH_PackChargingThermalSt "充电及加热状态
慢充充电状态及加热状态提示，0X5接受不处理，收到0x2,0x均为充电中；0x1为电池加热中；0x4为充电完成;0x6为均温充电中；0x7为电池冷却中";
CM_ SG_ 1183 BMSH_BattVolt "电池包系统电压";
CM_ SG_ 1183 BMSH_BatteryCurrent "高压电池包系统高压电流，针对电池包而言，负值表示给电池包充电:正值表示给电池包放电。";
CM_ SG_ 1472 BMSH_SingleDisChargeEnergy "单次放电能量";
CM_ SG_ 1472 BMSH_SingleChargeEnergy "单次充电能量";
CM_ SG_ 1449 BMSH_CellVoltMin "高压电池系统内最低单体电压";
CM_ SG_ 1449 BMSH_CellVoltMax "高压电池系统内最高单体电压";
CM_ SG_ 1448 BMSH_TempSensor_MinTemp "电池最低温度";
CM_ SG_ 1448 BMSH_TempSensor_MaxTemp "电池最高温度";
CM_ SG_ 1436 BMSH_InsulationResis "高压电池包检测的绝缘电阻值0xFFFE:Abnormal";
CM_ SG_ 1103 BMS_8_CC2Sts "仪表可用于显示充电连接";
CM_ SG_ 1103 BMSH_SOH "电池健康指数";
CM_ SG_ 1103 BMSH_LeftChargeTime "剩余充电时间";
CM_ SG_ 1083 BMSH_PackPowerRealTime "动力电池包实时功率";
CM_ SG_ 1083 BMSH_PackRemainEnergy "电池系统剩余电量";
CM_ SG_ 1083 BMSH_SOCDisp "电池电量显示";
CM_ SG_ 856 TBOX_TimeToStopChargeMinuteFed "充电时间反馈";
CM_ SG_ 856 TBOX_TimeToStopChargeHourFed "充电时间反馈";
CM_ SG_ 856 TBOX_TimeToStartChargeMinuteFed "充电时间反馈";
CM_ SG_ 856 TBOX_TimeToStartChargeHourFed "充电时间反馈";
CM_ SG_ 856 TBOX_ChargeModeSts "充电模式状态反馈";
CM_ SG_ 1314 TBOX_3_BatteryPowerLimit "电源限制等级";
CM_ BO_ 1025 "外部音效控制模块";
CM_ SG_ 1025 Welcome_OutsoundSts "车外迎宾音效选项状态";
CM_ SG_ 1025 Person_RemindSts "行人提醒开关";
CM_ SG_ 1025 Welcome_Outsound_SwitchSts "车外迎宾音效开关状态";
CM_ SG_ 803 PA_SW "左侧方控自定义按键";
CM_ SG_ 803 L_RESPlus_SW "左侧方控OK按键";
CM_ SG_ 803 L_RIGHT_SW "左侧方控右按键";
CM_ SG_ 803 L_LEFT_SW "左侧方控左按键";
CM_ SG_ 803 L_DW_SW "左侧方控向下按键";
CM_ SG_ 803 L_UP_SW "左侧方控向上按键";
CM_ SG_ 1120 Enter_super_fast_charge "进入超级快充信号反馈
0x00：未进入超级快充
0x01：进入华为超级快充
0x02：进入小米超级快充
0x03：进入OPPO超级快充
0x04~0xff：预留";
CM_ SG_ 1120 WCM_Electricity_decimal "无线充电电量反馈_小数部分";
CM_ SG_ 1120 WCM_Electricity_integer "无线充电电量反馈_整数部分";
CM_ SG_ 1120 WCM_PhoneDetectionStatus "手机遗忘提醒信号";
CM_ SG_ 1120 WCM_WirelessChargingStatus "无线充电工作状态反馈信号
0x01：待机
0x02：充电中
0x03：输入过压保护
0x04：输入欠压保护
0x05：FOD
0x06：过温保护
0x07：充电完成（需要手机支持该功能）
0x08：其它故障（一般为接收端故障）
0x09：PEPS停止充电
0x0A~0x0F：Reserved";
CM_ SG_ 1120 WCM_WirelessChargingSetStatus "无线充电模块设置反馈信号";
CM_ SG_ 1338 PM2_5_ErrSts "PM25错误状态";
CM_ SG_ 1338 PM2_5_Sts "PM25传感器状态";
CM_ SG_ 1338 PM2_5_AirIOutQLevel "室外空气质量等级";
CM_ SG_ 1338 PM2_5_AirInQLevel "室内空气质量等级";
CM_ SG_ 1338 PM2_5_Outdensity "室外空气PM2_5浓度";
CM_ SG_ 1338 PM2_5_Indensity "室内空气PM2_5浓度";
CM_ SG_ 787 ESP_3_AVHSts "AVH状态";
CM_ SG_ 1136 YAS_2_LongitudinalAcceleration "纵向加速度";
CM_ SG_ 1141 RAD2_Radar_FunctionModel_Status "雷达故障状态";
CM_ SG_ 1141 RAD2_LHSFRadarSensorDistance "左前侧探头信息";
CM_ SG_ 1141 RAD2_RHSFRadarSensorDistance "右前侧探头信息";
CM_ SG_ 1141 RAD2_LHSRRadarSensorDistance "左后侧探头信息";
CM_ SG_ 1141 RAD2_RHSRRadarSensorDistance "右后侧探头信息";
CM_ SG_ 1050 APA_AVM_3_SystemSts_Body_1 "APA功能内容状态
0x0:供应商内部没有开启APA功能时，此信号发0x0
0x1:standby模式
0x2:寻车过程中
0x3:泊车过程中
0x4:当车辆停止在目标的泊车位置时，此信号发0x4
0x5:APA故障
0x6:APA中断";
CM_ SG_ 1050 APA_Parking_Space_Search_Sts "车位搜索状态，用于中控声音提示";
CM_ SG_ 1050 AVM_FactoryMode "AVM工作模式";
CM_ SG_ 1050 APA_3AVMFeedbackSts_RemoteMode "远程状态下_AVM工作状态";
CM_ SG_ 1050 APA_AVM_3_AVMDisplaySts "AVM显示开关状态";
CM_ SG_ 1288 APA_2_AVMStatusFault "AVM系统故障_正常";
CM_ SG_ 1288 APA_2_AVMFaultStatusCameraRight "右摄像头故障_正常";
CM_ SG_ 1288 APA_2_AVMFaultStatusCameraRear "后摄像头故障_正常";
CM_ SG_ 1288 APA_2_AVMFaultStatusCameraLeft "左摄像头故障_正常";
CM_ SG_ 1288 APA_2_AVMFaultStatusCameraFront "前摄像头故障_正常";
CM_ SG_ 773 FRM_3_CRC "CRC (SAE J1850 CRC-8)";
CM_ SG_ 773 FRM_3_MessageCounter "报文计数";
CM_ SG_ 773 FRM_3_AEB_ON_OFF_Sts "紧急制动开关";
CM_ SG_ 773 FRM_3_FCW_OPTION_Sts "前碰撞预警距离设置";
CM_ SG_ 773 FRM_3_FCW_ON_OFF_Sts "前碰撞预警开关";
CM_ SG_ 773 FRM_3_FCW_PreWarning "FCW预警";
CM_ SG_ 773 FRM_3_DistanceWarning "FDW报警";
CM_ SG_ 773 FRM_3_AEBMode "AEB模式";
CM_ SG_ 773 FRM_3_FCWMode "FCW模式";
CM_ SG_ 773 FRM_3_Obiect_Dx "目标车辆在X向的位置";
CM_ SG_ 773 FRM_3_ACCMode "ACC模式";
CM_ SG_ 773 FRM_3_TimeGapSet_ICM "时距设置";
CM_ SG_ 773 FRM_3_TakeOverReq "脱手检测";
CM_ SG_ 773 FRM_3_Textinfo "文字提示";
CM_ SG_ 773 FRM_3_FrontObject_Type "触发报警时刻的目标车辆类型";
CM_ SG_ 773 FRM_3_ObjValid "发现目标车辆";
CM_ SG_ 773 FRM_3_DxTarObj "与其他车距距离";
CM_ SG_ 773 FRM_3_VSetDis "期望车速";
CM_ SG_ 1241 FuelTankLidSystemFailureSts "加油小门系统故障信号";
CM_ SG_ 1241 FuelTankPressureConditionReached "油箱压力状态信号";
CM_ SG_ 632 EMS_4_IntakeAirPressure "进气压力";
CM_ SG_ 632 EMS_4_EngineSts "发动机状态";
CM_ SG_ 1202 GSM_CHKSM_GSM_1 "((Byte0+Byte1+Byte2)AND 0xFF) XOR 0xFF";
CM_ SG_ 1202 ACC_Cruise_Control "ACC巡航控制";
CM_ SG_ 1202 GSM_GearShiftPos "挡位";
CM_ SG_ 1507 DHM_1_Doorkonb_time_freeback "门把手收回时间反馈";
CM_ SG_ 1518 CEM_DHM_handlelockswitchfeedback "隐藏式门把手闭锁反馈";
CM_ SG_ 1518 CEM_DHM_handleunlockswitchfeedba "隐藏式门把手解锁反馈";
CM_ SG_ 1517 CEM_SRF_lockingreason "天窗关闭原因反馈";
CM_ SG_ 1517 CEM_RR_window_up_Reason_feedback "右后乘客侧车窗上升原因反馈";
CM_ SG_ 1517 CEM_LR_window_up_Reason_feedback "左后乘客侧车窗上升原因反馈";
CM_ SG_ 1517 CEM_Passenger_window_up_Reason_f "副驾车窗上升原因反馈";
CM_ SG_ 1517 CEM_Driver_window_up_Reason_feed "主驾车窗上升原因反馈";
CM_ SG_ 1504 CEM_SRFclosingConditions "天窗关闭条件";
CM_ SG_ 1504 CEM_Abat_VentCMDSts "遮阳帘开启百分制反馈";
CM_ SG_ 1504 CEM_PSRFCMDSts "天窗开启百分制反馈";
CM_ SG_ 1168 CEM_ALM_1_SceneMode_ControlSwitc "关联智能场景氛围灯控制开关";
CM_ SG_ 1168 CEM_ALM_1_DeletePeronalSet_FB "删除自定义设置反馈";
CM_ SG_ 1168 CEM_ALM_1_PersonalBeamEn "灯光自定义设置使能信号";
CM_ SG_ 1168 CEM_ALM_1_PersonalSeatEn "座椅自定义设置使能信号";
CM_ SG_ 1168 CEM_ALM_1_Seat_Set_Status "座椅设置状态";
CM_ SG_ 1168 CEM_ALM_1_Seat_Set_Pop_Up "座椅设置弹出";
CM_ SG_ 1168 CEM_ALM_1_Wash_Car_Status "洗车模式状态";
CM_ SG_ 1168 CEM_ALM_1_PersonalSetSts "自定义设置状态";
CM_ SG_ 1168 CEM_ALM_1_STAT_WelcomeWaterLamp "迎宾流水灯开关";
CM_ SG_ 1168 CEM_ALM_1_STAT_AssociatedWithDri "关联驾驶模式开关";
CM_ SG_ 1168 CEM_ALM_1_STAT_Music "是否允许音乐律动";
CM_ SG_ 1168 CEM_ALM_1_STAT_Apiluminance "氛围灯亮度";
CM_ SG_ 1168 CEM_ALM_1_STAT_Static_Colour "静态颜色";
CM_ SG_ 1168 CEM_ALM_1_STAT_StaticEffect "静态效果";
CM_ SG_ 1168 CEM_ALM_1_STAT_ControlSwitch "氛围灯开关状态";
CM_ SG_ 1168 CEM_ALM_1_STAT_DMSMonitoring "DMS监测开关状态";
CM_ SG_ 1168 CEM_ALM_1_STAT_PM2_5Monitoring "PM2.5监测状态";
CM_ SG_ 1168 CEM_ALM_1_STAT_DriveApiluminance "行驶中氛围灯亮度状态";
CM_ SG_ 1168 CEM_ALM_1_STAT_64Colour "多元颜色设置状态";
CM_ SG_ 936 BCM_13_EBS_SOC "蓄电池电量";
CM_ SG_ 1492 CEM_DriverLumbart_UD_Locaton "主驾腰托上下调节位置反馈";
CM_ SG_ 1492 CEM_PassengerSeat_LegUD_Locaton "副驾腿托上下调节位置反馈";
CM_ SG_ 1492 CEM_PassengerSeat_FR_Locaton "副驾座椅前后调节位置反馈";
CM_ SG_ 1492 CEM_PassengerSeat_BackFR_Locaton "副驾靠背前后调节位置反馈";
CM_ SG_ 1492 CEM_DriverSeat_RearendUD_Locaton "主驾座椅后端上下调节位置反馈";
CM_ SG_ 1492 CEM_DriverSeat_FrontendUD_Locato "主驾座椅前端上下调节位置反馈";
CM_ SG_ 1492 CEM_DriverSeat_FR_Locaton "主驾座椅前后调节位置反馈";
CM_ SG_ 1492 CEM_DriverSeat_BackFR_Locaton "主驾靠背前后调节位置反馈";
CM_ SG_ 1492 CEM_Rmirror_UD_Locaton "右后视镜上下调节位置反馈";
CM_ SG_ 1492 CEM_Rmirror_LR_Locaton "右后视镜左右调节位置反馈";
CM_ SG_ 1492 CEM_Lmirror_UD_Locaton "左后视镜上下调节位置反馈";
CM_ SG_ 1492 CEM_Lmirror_LR_Locaton "左后视镜左右调节位置反馈";
CM_ SG_ 1476 CEM_Psngrseat_Location "副驾座椅记忆反馈";
CM_ SG_ 1476 CEM_PassengerSeat_LegUDSts "副驾座椅腿托上下调节反馈";
CM_ SG_ 1476 CEM_PassengerSeat_BackFRSts "副驾座椅靠背前后调节反馈";
CM_ SG_ 1476 CEM_PassengerSeat_FRSts "副驾座椅前后调节反馈";
CM_ SG_ 1476 CEM_massagemodeSts "副驾按摩模式设置反馈";
CM_ SG_ 1476 CEM_passageVibrationSts "副驾按摩强度设置反馈";
CM_ SG_ 1476 CEM_Passenger_massageSts "副驾按摩开关反馈";
CM_ SG_ 1476 CEM_DriverLumbart_FR_Locaton "主驾腰托前后调节位置反馈";
CM_ SG_ 1476 CEM_Mirror_Driverseat_Location "外后视镜及主驾座椅记忆反馈";
CM_ SG_ 1476 CEM_UnderVoltageSts "亏电提醒开关反馈";
CM_ SG_ 1476 CEM_RearWiper_SwitchSts "自动雨刮使能开关反馈";
CM_ SG_ 1476 CEM_Wiper_MaintenanceSts "雨刮维修模式状态";
CM_ SG_ 1476 CEM_Mirror_Fold_SwitchSts "当前后视镜折叠状态";
CM_ SG_ 1476 CEM_IPM__FRSeatHeatVentSwSts "副驾座椅通风加热状态
（PHEV项目使用）";
CM_ SG_ 1476 CEM_IPM_FLSeatHeatVentSwSts "主驾座椅通风加热状态
(PHEV项目使用）";
CM_ SG_ 1476 CEM_DriverLumbart_UDSts "主驾腰托上下调节反馈";
CM_ SG_ 1476 CEM_DriverLumbart_FRSts "主驾腰托前后调节反馈";
CM_ SG_ 1476 CEM_DriverSeat_RearendUDSts "主驾座椅后端上下调节反馈";
CM_ SG_ 1476 CEM_DriverSeat_FrontendUDSts "主驾座椅前端上下调节反馈";
CM_ SG_ 1476 CEM_DriverSeat_FRSts "主驾座椅前后调节反馈";
CM_ SG_ 1476 CEM_DriverSeat_BackFRSts "主机座椅靠背前后调节反馈";
CM_ SG_ 1476 CEM_MirrorFlip_CFGSts "外后视镜倒车翻转设置反馈";
CM_ SG_ 1476 CEM_RightMirrorCtrlSts "右后视镜镜片被控制状态";
CM_ SG_ 1476 CEM_LeftMirrorCtrlSts "左后视镜镜片被控制状态";
CM_ SG_ 1476 CEM_RHRdoor_buttonsts "右后侧自定义开关";
CM_ SG_ 1476 CEM_LHRdoor_buttonsts "左后侧自定义开关";
CM_ SG_ 1476 CEM_PsngrDoor_buttonsts "副驾侧自定义开关";
CM_ SG_ 1476 CEM_Smart_HighBeamSts "智能大灯使能开关状态";
CM_ SG_ 1476 CEM_HighBeam_AdjustSts "大灯高度调节状态";
BA_DEF_  "NmAsrCanMsgCycleTime" INT 1000 1000;
BA_DEF_  "NmAsrRepeatMessageTime" INT 3000 3000;
BA_DEF_  "NmAsrWaitBusSleepTime" INT 1500 1500;
BA_DEF_  "NmAsrTimeoutTime" INT 2500 2500;
BA_DEF_  "NmAsrBaseAddress" HEX 0 2047;
BA_DEF_  "NmAsrMessageCount" INT 128 128;
BA_DEF_  "NmType" STRING ;
BA_DEF_  "ILTxTimeout" INT 0 65535;
BA_DEF_  "Manufacturer" STRING ;
BA_DEF_ SG_  "GenSigTimeoutValue" INT 0 2147483647;
BA_DEF_ SG_  "GenSigStartValue" INT 0 2147483647;
BA_DEF_ SG_  "GenSigInactiveValue" INT 0 2147483647;
BA_DEF_ BO_  "TpTxIndex" INT 0 255;
BA_DEF_ BO_  "DiagUudtResponse" ENUM  "False","True";
BA_DEF_ BO_  "DiagResponse" ENUM  "No","Yes";
BA_DEF_ BO_  "DiagRequest" ENUM  "No","Yes";
BA_DEF_ BO_  "DiagState" ENUM  "No","Yes";
BA_DEF_ BO_  "NmAsrMessage" ENUM  "No","Yes";
BA_DEF_ BO_  "GenMsgFastOnStart" INT 0 65535;
BA_DEF_ BO_  "GenMsgCycleTimeFast" INT 0 65535;
BA_DEF_ BO_  "GenMsgNrOfRepetition" INT 0 65535;
BA_DEF_ BO_  "GenMsgStartDelayTime" INT 0 65535;
BA_DEF_ BO_  "GenMsgCycleTime" INT 0 65535;
BA_DEF_ BO_  "GenMsgDelayTime" INT 0 65535;
BA_DEF_ SG_  "GenSigSendType" ENUM  "Cyclic","OnWrite","OnWriteWithRepetition","OnChange","OnChangeWithRepetition","IfActive","IfActiveWithRepetition","NoSigSendType","OnChangeAndIfActive","OnChangeAndIfActiveWithRepetition";
BA_DEF_ BO_  "GenMsgSendType" ENUM  "Cyclic","NotUsed","NotUsed","NotUsed","NotUsed","NotUsed","NotUsed","IfActive","NoMsgSendType";
BA_DEF_ BO_  "GenMsgILSupport" ENUM  "No","Yes";
BA_DEF_ BU_  "NmStationAddress" HEX 0 255;
BA_DEF_ BU_  "NmAsrCanMsgReducedTime" INT 500 818;
BA_DEF_ BU_  "NmAsrCanMsgCycleOffset" INT 0 635;
BA_DEF_ BU_  "NmAsrNodeIdentifier" HEX 0 255;
BA_DEF_ BU_  "NmAsrNode" ENUM  "No","Yes";
BA_DEF_ BU_  "ILUsed" ENUM  "No","Yes";
BA_DEF_ SG_  "SystemSignalLongSymbol" STRING ;
BA_DEF_REL_ BU_SG_REL_  "GenSigTimeoutTime" INT 0 65535;
BA_DEF_DEF_  "NmAsrCanMsgCycleTime" 1000;
BA_DEF_DEF_  "NmAsrRepeatMessageTime" 3000;
BA_DEF_DEF_  "NmAsrWaitBusSleepTime" 1500;
BA_DEF_DEF_  "NmAsrTimeoutTime" 2500;
BA_DEF_DEF_  "NmAsrBaseAddress" 1536;
BA_DEF_DEF_  "NmAsrMessageCount" 128;
BA_DEF_DEF_  "NmType" "NmAsr";
BA_DEF_DEF_  "ILTxTimeout" 0;
BA_DEF_DEF_  "Manufacturer" "Vector";
BA_DEF_DEF_  "GenSigTimeoutValue" 0;
BA_DEF_DEF_  "GenSigStartValue" 0;
BA_DEF_DEF_  "GenSigInactiveValue" 0;
BA_DEF_DEF_  "TpTxIndex" 0;
BA_DEF_DEF_  "DiagUudtResponse" "False";
BA_DEF_DEF_  "DiagResponse" "No";
BA_DEF_DEF_  "DiagRequest" "No";
BA_DEF_DEF_  "DiagState" "No";
BA_DEF_DEF_  "NmAsrMessage" "No";
BA_DEF_DEF_  "GenMsgFastOnStart" 0;
BA_DEF_DEF_  "GenMsgCycleTimeFast" 0;
BA_DEF_DEF_  "GenMsgNrOfRepetition" 3;
BA_DEF_DEF_  "GenMsgStartDelayTime" 0;
BA_DEF_DEF_  "GenMsgCycleTime" 0;
BA_DEF_DEF_  "GenMsgDelayTime" 0;
BA_DEF_DEF_  "GenSigSendType" "Cyclic";
BA_DEF_DEF_  "GenMsgSendType" "Cyclic";
BA_DEF_DEF_  "GenMsgILSupport" "No";
BA_DEF_DEF_  "NmStationAddress" 255;
BA_DEF_DEF_  "NmAsrCanMsgReducedTime" 575;
BA_DEF_DEF_  "NmAsrCanMsgCycleOffset" 0;
BA_DEF_DEF_  "NmAsrNodeIdentifier" 255;
BA_DEF_DEF_  "NmAsrNode" "No";
BA_DEF_DEF_  "ILUsed" "No";
BA_DEF_DEF_REL_ "GenSigTimeoutTime" 0;
BA_DEF_DEF_  "SystemSignalLongSymbol" "";
BA_ "NmAsrNodeIdentifier" BU_ Tester 0;
BA_ "NmAsrNodeIdentifier" BU_ WCM 0;
BA_ "NmAsrNodeIdentifier" BU_ MFS 0;
BA_ "NmStationAddress" BU_ HUD 21;
BA_ "NmAsrNodeIdentifier" BU_ HUD 21;
BA_ "NmAsrNode" BU_ HUD 1;
BA_ "ILUsed" BU_ HUD 1;
BA_ "NmStationAddress" BU_ CGW 0;
BA_ "NmAsrNodeIdentifier" BU_ CGW 0;
BA_ "NmAsrNode" BU_ CGW 1;
BA_ "ILUsed" BU_ CGW 1;
BA_ "NmStationAddress" BU_ IHU 0;
BA_ "NmAsrNodeIdentifier" BU_ IHU 24;
BA_ "GenMsgSendType" BO_ 1796 8;
BA_ "GenMsgNrOfRepetition" BO_ 1796 0;
BA_ "DiagRequest" BO_ 1796 1;
BA_ "DiagResponse" BO_ 1812 1;
BA_ "GenMsgSendType" BO_ 1812 8;
BA_ "GenMsgNrOfRepetition" BO_ 1812 0;
BA_ "GenMsgSendType" BO_ 1794 8;
BA_ "GenMsgNrOfRepetition" BO_ 1794 0;
BA_ "DiagRequest" BO_ 1794 1;
BA_ "GenMsgSendType" BO_ 1810 8;
BA_ "GenMsgNrOfRepetition" BO_ 1810 0;
BA_ "DiagResponse" BO_ 1810 1;
BA_ "GenMsgSendType" BO_ 1854 8;
BA_ "GenMsgNrOfRepetition" BO_ 1854 0;
BA_ "DiagResponse" BO_ 1854 1;
BA_ "GenMsgSendType" BO_ 1838 8;
BA_ "GenMsgNrOfRepetition" BO_ 1838 0;
BA_ "DiagRequest" BO_ 1838 1;
BA_ "GenMsgSendType" BO_ 1906 8;
BA_ "GenMsgNrOfRepetition" BO_ 1906 0;
BA_ "DiagResponse" BO_ 1906 1;
BA_ "GenMsgSendType" BO_ 1890 8;
BA_ "GenMsgNrOfRepetition" BO_ 1890 0;
BA_ "DiagRequest" BO_ 1890 1;
BA_ "GenMsgILSupport" BO_ 933 1;
BA_ "GenMsgCycleTime" BO_ 933 20;
BA_ "GenMsgNrOfRepetition" BO_ 933 0;
BA_ "DiagRequest" BO_ 2015 1;
BA_ "GenMsgNrOfRepetition" BO_ 2015 0;
BA_ "GenMsgSendType" BO_ 2015 8;
BA_ "DiagRequest" BO_ 1793 1;
BA_ "GenMsgNrOfRepetition" BO_ 1793 0;
BA_ "GenMsgSendType" BO_ 1793 8;
BA_ "DiagRequest" BO_ 1798 1;
BA_ "GenMsgNrOfRepetition" BO_ 1798 0;
BA_ "GenMsgSendType" BO_ 1798 8;
BA_ "DiagRequest" BO_ 1804 1;
BA_ "GenMsgNrOfRepetition" BO_ 1804 0;
BA_ "GenMsgSendType" BO_ 1804 8;
BA_ "DiagResponse" BO_ 1809 1;
BA_ "GenMsgNrOfRepetition" BO_ 1809 0;
BA_ "GenMsgSendType" BO_ 1809 8;
BA_ "DiagResponse" BO_ 1814 1;
BA_ "GenMsgNrOfRepetition" BO_ 1814 0;
BA_ "GenMsgSendType" BO_ 1814 8;
BA_ "DiagResponse" BO_ 1820 1;
BA_ "GenMsgNrOfRepetition" BO_ 1820 0;
BA_ "GenMsgSendType" BO_ 1820 8;
BA_ "DiagRequest" BO_ 1827 1;
BA_ "GenMsgNrOfRepetition" BO_ 1827 0;
BA_ "GenMsgSendType" BO_ 1827 8;
BA_ "DiagRequest" BO_ 1830 1;
BA_ "GenMsgNrOfRepetition" BO_ 1830 0;
BA_ "GenMsgSendType" BO_ 1830 8;
BA_ "DiagRequest" BO_ 1833 1;
BA_ "GenMsgNrOfRepetition" BO_ 1833 0;
BA_ "GenMsgSendType" BO_ 1833 8;
BA_ "DiagResponse" BO_ 1843 1;
BA_ "GenMsgNrOfRepetition" BO_ 1843 0;
BA_ "GenMsgSendType" BO_ 1843 8;
BA_ "DiagResponse" BO_ 1846 1;
BA_ "GenMsgNrOfRepetition" BO_ 1846 0;
BA_ "GenMsgSendType" BO_ 1846 8;
BA_ "DiagResponse" BO_ 1849 1;
BA_ "GenMsgNrOfRepetition" BO_ 1849 0;
BA_ "GenMsgSendType" BO_ 1849 8;
BA_ "DiagRequest" BO_ 1860 1;
BA_ "GenMsgNrOfRepetition" BO_ 1860 0;
BA_ "GenMsgSendType" BO_ 1860 8;
BA_ "DiagRequest" BO_ 1864 1;
BA_ "GenMsgNrOfRepetition" BO_ 1864 0;
BA_ "GenMsgSendType" BO_ 1864 8;
BA_ "DiagRequest" BO_ 1867 1;
BA_ "GenMsgNrOfRepetition" BO_ 1867 0;
BA_ "GenMsgSendType" BO_ 1867 8;
BA_ "DiagRequest" BO_ 1869 1;
BA_ "GenMsgNrOfRepetition" BO_ 1869 0;
BA_ "GenMsgSendType" BO_ 1869 8;
BA_ "DiagRequest" BO_ 1870 1;
BA_ "GenMsgNrOfRepetition" BO_ 1870 0;
BA_ "GenMsgSendType" BO_ 1870 8;
BA_ "DiagResponse" BO_ 1876 1;
BA_ "GenMsgNrOfRepetition" BO_ 1876 0;
BA_ "GenMsgSendType" BO_ 1876 8;
BA_ "DiagResponse" BO_ 1880 1;
BA_ "GenMsgNrOfRepetition" BO_ 1880 0;
BA_ "GenMsgSendType" BO_ 1880 8;
BA_ "DiagResponse" BO_ 1883 1;
BA_ "GenMsgNrOfRepetition" BO_ 1883 0;
BA_ "GenMsgSendType" BO_ 1883 8;
BA_ "DiagResponse" BO_ 1885 1;
BA_ "GenMsgNrOfRepetition" BO_ 1885 0;
BA_ "GenMsgSendType" BO_ 1885 8;
BA_ "DiagResponse" BO_ 1886 1;
BA_ "GenMsgNrOfRepetition" BO_ 1886 0;
BA_ "GenMsgSendType" BO_ 1886 8;
BA_ "DiagRequest" BO_ 1888 1;
BA_ "GenMsgNrOfRepetition" BO_ 1888 0;
BA_ "GenMsgSendType" BO_ 1888 8;
BA_ "DiagRequest" BO_ 1891 1;
BA_ "GenMsgNrOfRepetition" BO_ 1891 0;
BA_ "GenMsgSendType" BO_ 1891 8;
BA_ "DiagRequest" BO_ 1898 1;
BA_ "GenMsgNrOfRepetition" BO_ 1898 0;
BA_ "GenMsgSendType" BO_ 1898 8;
BA_ "DiagRequest" BO_ 1899 1;
BA_ "GenMsgNrOfRepetition" BO_ 1899 0;
BA_ "GenMsgSendType" BO_ 1899 8;
BA_ "DiagResponse" BO_ 1904 1;
BA_ "GenMsgNrOfRepetition" BO_ 1904 0;
BA_ "GenMsgSendType" BO_ 1904 8;
BA_ "DiagResponse" BO_ 1907 1;
BA_ "GenMsgNrOfRepetition" BO_ 1907 0;
BA_ "GenMsgSendType" BO_ 1907 8;
BA_ "DiagResponse" BO_ 1914 1;
BA_ "GenMsgNrOfRepetition" BO_ 1914 0;
BA_ "GenMsgSendType" BO_ 1914 8;
BA_ "DiagResponse" BO_ 1915 1;
BA_ "GenMsgNrOfRepetition" BO_ 1915 0;
BA_ "GenMsgSendType" BO_ 1915 8;
BA_ "DiagRequest" BO_ 1927 1;
BA_ "GenMsgNrOfRepetition" BO_ 1927 0;
BA_ "GenMsgSendType" BO_ 1927 8;
BA_ "DiagResponse" BO_ 1943 1;
BA_ "GenMsgNrOfRepetition" BO_ 1943 0;
BA_ "GenMsgSendType" BO_ 1943 8;
BA_ "DiagRequest" BO_ 1997 1;
BA_ "GenMsgNrOfRepetition" BO_ 1997 0;
BA_ "GenMsgSendType" BO_ 1997 8;
BA_ "DiagResponse" BO_ 2013 1;
BA_ "GenMsgNrOfRepetition" BO_ 2013 0;
BA_ "GenMsgSendType" BO_ 2013 8;
BA_ "DiagResponse" BO_ 1811 1;
BA_ "GenMsgNrOfRepetition" BO_ 1811 0;
BA_ "GenMsgSendType" BO_ 1811 8;
BA_ "DiagRequest" BO_ 2017 1;
BA_ "GenMsgNrOfRepetition" BO_ 2017 0;
BA_ "GenMsgSendType" BO_ 2017 8;
BA_ "DiagResponse" BO_ 1884 1;
BA_ "GenMsgNrOfRepetition" BO_ 1884 0;
BA_ "GenMsgSendType" BO_ 1884 8;
BA_ "DiagRequest" BO_ 1868 1;
BA_ "GenMsgNrOfRepetition" BO_ 1868 0;
BA_ "GenMsgSendType" BO_ 1868 8;
BA_ "DiagResponse" BO_ 1940 1;
BA_ "GenMsgNrOfRepetition" BO_ 1940 0;
BA_ "GenMsgSendType" BO_ 1940 8;
BA_ "DiagRequest" BO_ 1924 1;
BA_ "GenMsgNrOfRepetition" BO_ 1924 0;
BA_ "GenMsgSendType" BO_ 1924 8;
BA_ "DiagResponse" BO_ 1939 1;
BA_ "GenMsgNrOfRepetition" BO_ 1939 0;
BA_ "GenMsgSendType" BO_ 1939 8;
BA_ "DiagRequest" BO_ 1923 1;
BA_ "GenMsgNrOfRepetition" BO_ 1923 0;
BA_ "GenMsgSendType" BO_ 1923 8;
BA_ "DiagRequest" BO_ 1795 1;
BA_ "GenMsgNrOfRepetition" BO_ 1795 0;
BA_ "GenMsgSendType" BO_ 1795 8;
BA_ "DiagResponse" BO_ 2031 1;
BA_ "GenMsgNrOfRepetition" BO_ 2031 0;
BA_ "GenMsgSendType" BO_ 2031 8;
BA_ "DiagRequest" BO_ 2023 1;
BA_ "GenMsgNrOfRepetition" BO_ 2023 0;
BA_ "GenMsgSendType" BO_ 2023 8;
BA_ "DiagResponse" BO_ 2025 1;
BA_ "GenMsgNrOfRepetition" BO_ 2025 0;
BA_ "GenMsgSendType" BO_ 2025 8;
BA_ "DiagResponse" BO_ 2042 1;
BA_ "GenMsgNrOfRepetition" BO_ 2042 0;
BA_ "GenMsgSendType" BO_ 2042 8;
BA_ "DiagRequest" BO_ 2034 1;
BA_ "GenMsgNrOfRepetition" BO_ 2034 0;
BA_ "GenMsgSendType" BO_ 2034 8;
BA_ "DiagResponse" BO_ 1844 1;
BA_ "GenMsgNrOfRepetition" BO_ 1844 0;
BA_ "GenMsgSendType" BO_ 1844 8;
BA_ "DiagRequest" BO_ 1828 1;
BA_ "GenMsgNrOfRepetition" BO_ 1828 0;
BA_ "GenMsgSendType" BO_ 1828 8;
BA_ "DiagResponse" BO_ 1919 1;
BA_ "GenMsgNrOfRepetition" BO_ 1919 0;
BA_ "GenMsgSendType" BO_ 1919 8;
BA_ "DiagRequest" BO_ 1903 1;
BA_ "GenMsgNrOfRepetition" BO_ 1903 0;
BA_ "GenMsgSendType" BO_ 1903 8;
BA_ "DiagResponse" BO_ 1918 1;
BA_ "GenMsgNrOfRepetition" BO_ 1918 0;
BA_ "GenMsgSendType" BO_ 1918 8;
BA_ "DiagRequest" BO_ 1902 1;
BA_ "GenMsgNrOfRepetition" BO_ 1902 0;
BA_ "GenMsgSendType" BO_ 1902 8;
BA_ "DiagResponse" BO_ 1946 1;
BA_ "GenMsgNrOfRepetition" BO_ 1946 0;
BA_ "GenMsgSendType" BO_ 1946 8;
BA_ "DiagRequest" BO_ 1818 1;
BA_ "GenMsgNrOfRepetition" BO_ 1818 0;
BA_ "GenMsgSendType" BO_ 1818 8;
BA_ "DiagResponse" BO_ 2027 1;
BA_ "GenMsgNrOfRepetition" BO_ 2027 0;
BA_ "GenMsgSendType" BO_ 2027 8;
BA_ "DiagRequest" BO_ 2019 1;
BA_ "GenMsgNrOfRepetition" BO_ 2019 0;
BA_ "GenMsgSendType" BO_ 2019 8;
BA_ "DiagResponse" BO_ 1819 1;
BA_ "GenMsgNrOfRepetition" BO_ 1819 0;
BA_ "GenMsgSendType" BO_ 1819 8;
BA_ "DiagRequest" BO_ 1803 1;
BA_ "GenMsgNrOfRepetition" BO_ 1803 0;
BA_ "GenMsgSendType" BO_ 1803 8;
BA_ "DiagResponse" BO_ 1972 1;
BA_ "GenMsgNrOfRepetition" BO_ 1972 0;
BA_ "GenMsgSendType" BO_ 1972 8;
BA_ "DiagRequest" BO_ 1953 1;
BA_ "GenMsgNrOfRepetition" BO_ 1953 0;
BA_ "GenMsgSendType" BO_ 1953 8;
BA_ "DiagResponse" BO_ 1840 1;
BA_ "GenMsgNrOfRepetition" BO_ 1840 0;
BA_ "GenMsgSendType" BO_ 1840 8;
BA_ "DiagRequest" BO_ 1824 1;
BA_ "GenMsgNrOfRepetition" BO_ 1824 0;
BA_ "GenMsgSendType" BO_ 1824 8;
BA_ "DiagResponse" BO_ 1882 1;
BA_ "GenMsgNrOfRepetition" BO_ 1882 0;
BA_ "GenMsgSendType" BO_ 1882 8;
BA_ "DiagRequest" BO_ 1866 1;
BA_ "GenMsgNrOfRepetition" BO_ 1866 0;
BA_ "GenMsgSendType" BO_ 1866 8;
BA_ "DiagResponse" BO_ 2026 1;
BA_ "GenMsgNrOfRepetition" BO_ 2026 0;
BA_ "GenMsgSendType" BO_ 2026 8;
BA_ "DiagRequest" BO_ 2018 1;
BA_ "GenMsgNrOfRepetition" BO_ 2018 0;
BA_ "GenMsgSendType" BO_ 2018 8;
BA_ "DiagResponse" BO_ 1855 1;
BA_ "GenMsgNrOfRepetition" BO_ 1855 0;
BA_ "GenMsgSendType" BO_ 1855 8;
BA_ "DiagRequest" BO_ 1839 1;
BA_ "GenMsgNrOfRepetition" BO_ 1839 0;
BA_ "GenMsgSendType" BO_ 1839 8;
BA_ "DiagResponse" BO_ 1841 1;
BA_ "GenMsgNrOfRepetition" BO_ 1841 0;
BA_ "GenMsgSendType" BO_ 1841 8;
BA_ "DiagRequest" BO_ 1825 1;
BA_ "GenMsgNrOfRepetition" BO_ 1825 0;
BA_ "GenMsgSendType" BO_ 1825 8;
BA_ "DiagResponse" BO_ 1822 1;
BA_ "GenMsgNrOfRepetition" BO_ 1822 0;
BA_ "GenMsgSendType" BO_ 1822 8;
BA_ "DiagRequest" BO_ 1806 1;
BA_ "GenMsgNrOfRepetition" BO_ 1806 0;
BA_ "GenMsgSendType" BO_ 1806 8;
BA_ "DiagResponse" BO_ 2024 1;
BA_ "GenMsgNrOfRepetition" BO_ 2024 0;
BA_ "GenMsgSendType" BO_ 2024 8;
BA_ "DiagRequest" BO_ 2016 1;
BA_ "GenMsgNrOfRepetition" BO_ 2016 0;
BA_ "GenMsgSendType" BO_ 2016 8;
BA_ "DiagResponse" BO_ 1947 1;
BA_ "GenMsgNrOfRepetition" BO_ 1947 0;
BA_ "GenMsgSendType" BO_ 1947 8;
BA_ "DiagRequest" BO_ 1931 1;
BA_ "GenMsgNrOfRepetition" BO_ 1931 0;
BA_ "GenMsgSendType" BO_ 1931 8;
BA_ "DiagResponse" BO_ 2008 1;
BA_ "GenMsgNrOfRepetition" BO_ 2008 0;
BA_ "GenMsgSendType" BO_ 2008 8;
BA_ "DiagRequest" BO_ 2000 1;
BA_ "GenMsgNrOfRepetition" BO_ 2000 0;
BA_ "GenMsgSendType" BO_ 2000 8;
BA_ "DiagResponse" BO_ 2030 1;
BA_ "GenMsgNrOfRepetition" BO_ 2030 0;
BA_ "GenMsgSendType" BO_ 2030 8;
BA_ "DiagRequest" BO_ 2022 1;
BA_ "GenMsgNrOfRepetition" BO_ 2022 0;
BA_ "GenMsgSendType" BO_ 2022 8;
BA_ "DiagResponse" BO_ 1942 1;
BA_ "GenMsgNrOfRepetition" BO_ 1942 0;
BA_ "GenMsgSendType" BO_ 1942 8;
BA_ "DiagRequest" BO_ 1926 1;
BA_ "GenMsgNrOfRepetition" BO_ 1926 0;
BA_ "GenMsgSendType" BO_ 1926 8;
BA_ "DiagResponse" BO_ 2029 1;
BA_ "GenMsgNrOfRepetition" BO_ 2029 0;
BA_ "GenMsgSendType" BO_ 2029 8;
BA_ "DiagRequest" BO_ 2021 1;
BA_ "GenMsgNrOfRepetition" BO_ 2021 0;
BA_ "GenMsgSendType" BO_ 2021 8;
BA_ "DiagResponse" BO_ 1968 1;
BA_ "GenMsgNrOfRepetition" BO_ 1968 0;
BA_ "GenMsgSendType" BO_ 1968 8;
BA_ "DiagRequest" BO_ 1952 1;
BA_ "GenMsgNrOfRepetition" BO_ 1952 0;
BA_ "GenMsgSendType" BO_ 1952 8;
BA_ "DiagResponse" BO_ 1975 1;
BA_ "GenMsgNrOfRepetition" BO_ 1975 0;
BA_ "GenMsgSendType" BO_ 1975 8;
BA_ "DiagRequest" BO_ 1959 1;
BA_ "GenMsgNrOfRepetition" BO_ 1959 0;
BA_ "GenMsgSendType" BO_ 1959 8;
BA_ "DiagResponse" BO_ 1910 1;
BA_ "GenMsgNrOfRepetition" BO_ 1910 0;
BA_ "GenMsgSendType" BO_ 1910 8;
BA_ "DiagRequest" BO_ 1894 1;
BA_ "GenMsgNrOfRepetition" BO_ 1894 0;
BA_ "GenMsgSendType" BO_ 1894 8;
BA_ "DiagResponse" BO_ 1845 1;
BA_ "GenMsgNrOfRepetition" BO_ 1845 0;
BA_ "GenMsgSendType" BO_ 1845 8;
BA_ "DiagRequest" BO_ 1829 1;
BA_ "GenMsgNrOfRepetition" BO_ 1829 0;
BA_ "GenMsgSendType" BO_ 1829 8;
BA_ "DiagResponse" BO_ 2041 1;
BA_ "GenMsgNrOfRepetition" BO_ 2041 0;
BA_ "GenMsgSendType" BO_ 2041 8;
BA_ "DiagRequest" BO_ 2033 1;
BA_ "GenMsgNrOfRepetition" BO_ 2033 0;
BA_ "GenMsgSendType" BO_ 2033 8;
BA_ "DiagResponse" BO_ 1887 1;
BA_ "GenMsgNrOfRepetition" BO_ 1887 0;
BA_ "GenMsgSendType" BO_ 1887 8;
BA_ "DiagRequest" BO_ 1871 1;
BA_ "GenMsgNrOfRepetition" BO_ 1871 0;
BA_ "GenMsgSendType" BO_ 1871 8;
BA_ "GenMsgILSupport" BO_ 1533 1;
BA_ "GenMsgSendType" BO_ 1533 8;
BA_ "GenMsgNrOfRepetition" BO_ 1533 2;
BA_ "GenMsgCycleTimeFast" BO_ 1533 100;
BA_ "GenMsgILSupport" BO_ 517 1;
BA_ "GenMsgCycleTime" BO_ 517 20;
BA_ "GenMsgNrOfRepetition" BO_ 517 0;
BA_ "GenMsgCycleTimeFast" BO_ 826 100;
BA_ "GenMsgNrOfRepetition" BO_ 826 2;
BA_ "GenMsgSendType" BO_ 826 8;
BA_ "GenMsgILSupport" BO_ 826 1;
BA_ "GenMsgCycleTimeFast" BO_ 824 100;
BA_ "GenMsgNrOfRepetition" BO_ 824 2;
BA_ "GenMsgSendType" BO_ 824 8;
BA_ "GenMsgILSupport" BO_ 824 1;
BA_ "GenMsgCycleTimeFast" BO_ 823 100;
BA_ "GenMsgNrOfRepetition" BO_ 823 2;
BA_ "GenMsgSendType" BO_ 823 8;
BA_ "GenMsgILSupport" BO_ 823 1;
BA_ "GenMsgCycleTimeFast" BO_ 822 100;
BA_ "GenMsgNrOfRepetition" BO_ 822 2;
BA_ "GenMsgSendType" BO_ 822 8;
BA_ "GenMsgILSupport" BO_ 822 1;
BA_ "GenMsgCycleTimeFast" BO_ 828 100;
BA_ "GenMsgNrOfRepetition" BO_ 828 2;
BA_ "GenMsgSendType" BO_ 828 8;
BA_ "GenMsgILSupport" BO_ 828 1;
BA_ "GenMsgILSupport" BO_ 827 1;
BA_ "GenMsgSendType" BO_ 827 8;
BA_ "GenMsgNrOfRepetition" BO_ 827 2;
BA_ "GenMsgCycleTimeFast" BO_ 827 100;
BA_ "GenMsgILSupport" BO_ 1073 1;
BA_ "GenMsgSendType" BO_ 1073 8;
BA_ "GenMsgNrOfRepetition" BO_ 1073 2;
BA_ "GenMsgCycleTimeFast" BO_ 1073 100;
BA_ "GenMsgNrOfRepetition" BO_ 1015 0;
BA_ "GenMsgCycleTime" BO_ 1015 100;
BA_ "GenMsgILSupport" BO_ 1015 1;
BA_ "GenMsgNrOfRepetition" BO_ 934 0;
BA_ "GenMsgCycleTime" BO_ 934 100;
BA_ "GenMsgILSupport" BO_ 934 1;
BA_ "GenMsgILSupport" BO_ 1105 1;
BA_ "GenMsgCycleTime" BO_ 1105 100;
BA_ "GenMsgNrOfRepetition" BO_ 1105 0;
BA_ "GenMsgILSupport" BO_ 746 1;
BA_ "GenMsgCycleTime" BO_ 746 20;
BA_ "GenMsgNrOfRepetition" BO_ 746 0;
BA_ "GenMsgNrOfRepetition" BO_ 1216 0;
BA_ "GenMsgCycleTime" BO_ 1216 500;
BA_ "GenMsgILSupport" BO_ 1216 1;
BA_ "GenMsgILSupport" BO_ 1041 1;
BA_ "GenMsgCycleTime" BO_ 1041 100;
BA_ "GenMsgNrOfRepetition" BO_ 1041 0;
BA_ "GenMsgILSupport" BO_ 1040 1;
BA_ "GenMsgSendType" BO_ 1040 8;
BA_ "GenMsgNrOfRepetition" BO_ 1040 2;
BA_ "GenMsgCycleTimeFast" BO_ 1040 100;
BA_ "GenMsgILSupport" BO_ 1167 1;
BA_ "GenMsgSendType" BO_ 1167 8;
BA_ "GenMsgNrOfRepetition" BO_ 1167 2;
BA_ "GenMsgCycleTimeFast" BO_ 1167 50;
BA_ "GenMsgILSupport" BO_ 1143 1;
BA_ "GenMsgCycleTime" BO_ 1143 100;
BA_ "GenMsgNrOfRepetition" BO_ 1143 0;
BA_ "GenMsgILSupport" BO_ 1299 1;
BA_ "GenMsgCycleTime" BO_ 1299 500;
BA_ "GenMsgNrOfRepetition" BO_ 1299 0;
BA_ "GenMsgNrOfRepetition" BO_ 1336 0;
BA_ "GenMsgCycleTime" BO_ 1336 500;
BA_ "GenMsgILSupport" BO_ 1336 1;
BA_ "GenMsgNrOfRepetition" BO_ 1526 0;
BA_ "GenMsgCycleTime" BO_ 1526 500;
BA_ "GenMsgILSupport" BO_ 1526 1;
BA_ "GenMsgILSupport" BO_ 1298 1;
BA_ "GenMsgCycleTime" BO_ 1298 1000;
BA_ "GenMsgNrOfRepetition" BO_ 1298 2;
BA_ "GenMsgCycleTimeFast" BO_ 1298 100;
BA_ "GenMsgILSupport" BO_ 1434 1;
BA_ "GenMsgCycleTime" BO_ 1434 1000;
BA_ "GenMsgNrOfRepetition" BO_ 1434 0;
BA_ "GenMsgNrOfRepetition" BO_ 1184 0;
BA_ "GenMsgCycleTime" BO_ 1184 500;
BA_ "GenMsgILSupport" BO_ 1184 1;
BA_ "GenMsgILSupport" BO_ 1418 1;
BA_ "GenMsgCycleTime" BO_ 1418 100;
BA_ "GenMsgNrOfRepetition" BO_ 1418 0;
BA_ "GenMsgSendType" BO_ 1521 8;
BA_ "GenMsgILSupport" BO_ 1521 1;
BA_ "GenMsgCycleTime" BO_ 1521 100;
BA_ "GenMsgNrOfRepetition" BO_ 1521 2;
BA_ "GenMsgSendType" BO_ 1520 8;
BA_ "GenMsgNrOfRepetition" BO_ 1520 2;
BA_ "GenMsgILSupport" BO_ 1520 1;
BA_ "GenMsgCycleTimeFast" BO_ 1520 100;
BA_ "GenMsgNrOfRepetition" BO_ 1487 0;
BA_ "GenMsgCycleTime" BO_ 1487 100;
BA_ "GenMsgILSupport" BO_ 1487 1;
BA_ "GenMsgNrOfRepetition" BO_ 1349 2;
BA_ "GenMsgCycleTime" BO_ 1349 100;
BA_ "GenMsgILSupport" BO_ 1349 1;
BA_ "GenMsgCycleTimeFast" BO_ 1349 20;
BA_ "GenMsgILSupport" BO_ 809 1;
BA_ "GenMsgCycleTime" BO_ 809 50;
BA_ "GenMsgNrOfRepetition" BO_ 809 0;
BA_ "GenMsgILSupport" BO_ 1444 1;
BA_ "GenMsgCycleTime" BO_ 1444 100;
BA_ "GenMsgNrOfRepetition" BO_ 1444 0;
BA_ "GenMsgCycleTime" BO_ 1534 500;
BA_ "GenMsgILSupport" BO_ 1534 1;
BA_ "GenMsgNrOfRepetition" BO_ 1534 0;
BA_ "GenMsgNrOfRepetition" BO_ 1480 0;
BA_ "GenMsgCycleTime" BO_ 1480 10000;
BA_ "GenMsgILSupport" BO_ 1480 1;
BA_ "GenMsgCycleTimeFast" BO_ 1416 100;
BA_ "GenMsgNrOfRepetition" BO_ 1416 2;
BA_ "GenMsgSendType" BO_ 1416 8;
BA_ "GenMsgILSupport" BO_ 1416 1;
BA_ "GenMsgILSupport" BO_ 1330 1;
BA_ "GenMsgSendType" BO_ 1330 8;
BA_ "GenMsgNrOfRepetition" BO_ 1330 2;
BA_ "GenMsgCycleTimeFast" BO_ 1330 100;
BA_ "GenMsgILSupport" BO_ 805 1;
BA_ "GenMsgCycleTime" BO_ 805 20;
BA_ "GenMsgNrOfRepetition" BO_ 805 0;
BA_ "GenMsgILSupport" BO_ 896 1;
BA_ "GenMsgCycleTime" BO_ 896 100;
BA_ "GenMsgNrOfRepetition" BO_ 896 0;
BA_ "GenMsgILSupport" BO_ 913 1;
BA_ "GenMsgCycleTime" BO_ 913 20;
BA_ "GenMsgCycleTimeFast" BO_ 913 20;
BA_ "GenMsgILSupport" BO_ 554 1;
BA_ "GenMsgCycleTime" BO_ 554 20;
BA_ "GenMsgNrOfRepetition" BO_ 554 0;
BA_ "GenMsgILSupport" BO_ 1421 1;
BA_ "GenMsgCycleTime" BO_ 1421 500;
BA_ "GenMsgNrOfRepetition" BO_ 1421 0;
BA_ "GenMsgILSupport" BO_ 1253 1;
BA_ "GenMsgCycleTime" BO_ 1253 20;
BA_ "GenMsgNrOfRepetition" BO_ 1253 0;
BA_ "GenMsgILSupport" BO_ 745 1;
BA_ "GenMsgCycleTime" BO_ 745 10;
BA_ "GenMsgNrOfRepetition" BO_ 745 0;
BA_ "GenMsgILSupport" BO_ 250 1;
BA_ "GenMsgCycleTime" BO_ 250 10;
BA_ "GenMsgNrOfRepetition" BO_ 250 0;
BA_ "GenMsgCycleTime" BO_ 932 100;
BA_ "GenMsgILSupport" BO_ 932 1;
BA_ "GenMsgNrOfRepetition" BO_ 932 0;
BA_ "GenMsgILSupport" BO_ 1414 1;
BA_ "GenMsgSendType" BO_ 1414 8;
BA_ "GenMsgCycleTimeFast" BO_ 1414 100;
BA_ "GenMsgNrOfRepetition" BO_ 1414 2;
BA_ "GenMsgILSupport" BO_ 1413 1;
BA_ "GenMsgSendType" BO_ 1413 8;
BA_ "GenMsgCycleTimeFast" BO_ 1413 100;
BA_ "GenMsgNrOfRepetition" BO_ 1413 2;
BA_ "GenMsgILSupport" BO_ 923 1;
BA_ "GenMsgCycleTime" BO_ 923 100;
BA_ "GenMsgNrOfRepetition" BO_ 923 0;
BA_ "GenMsgILSupport" BO_ 922 1;
BA_ "GenMsgCycleTime" BO_ 922 100;
BA_ "GenMsgNrOfRepetition" BO_ 922 0;
BA_ "GenMsgILSupport" BO_ 1114 1;
BA_ "GenMsgSendType" BO_ 1114 8;
BA_ "GenMsgCycleTimeFast" BO_ 1114 20;
BA_ "GenMsgNrOfRepetition" BO_ 1114 2;
BA_ "GenMsgILSupport" BO_ 804 1;
BA_ "GenMsgCycleTime" BO_ 804 20;
BA_ "GenMsgNrOfRepetition" BO_ 804 0;
BA_ "GenMsgCycleTimeFast" BO_ 1360 50;
BA_ "GenMsgSendType" BO_ 1360 8;
BA_ "GenMsgILSupport" BO_ 1360 1;
BA_ "GenMsgNrOfRepetition" BO_ 1240 0;
BA_ "GenMsgCycleTime" BO_ 1240 100;
BA_ "GenMsgILSupport" BO_ 1240 1;
BA_ "GenMsgNrOfRepetition" BO_ 1245 0;
BA_ "GenMsgCycleTime" BO_ 1245 100;
BA_ "GenMsgILSupport" BO_ 1245 1;
BA_ "GenMsgILSupport" BO_ 1276 1;
BA_ "GenMsgCycleTimeFast" BO_ 1276 100;
BA_ "GenMsgSendType" BO_ 1276 8;
BA_ "GenMsgNrOfRepetition" BO_ 1276 2;
BA_ "GenMsgNrOfRepetition" BO_ 1251 0;
BA_ "GenMsgCycleTime" BO_ 1251 100;
BA_ "GenMsgILSupport" BO_ 1251 1;
BA_ "GenMsgILSupport" BO_ 1262 1;
BA_ "GenMsgCycleTime" BO_ 1262 500;
BA_ "GenMsgNrOfRepetition" BO_ 1262 0;
BA_ "GenMsgILSupport" BO_ 1322 1;
BA_ "GenMsgCycleTime" BO_ 1322 1000;
BA_ "GenMsgCycleTimeFast" BO_ 1322 100;
BA_ "GenMsgNrOfRepetition" BO_ 1322 2;
BA_ "GenMsgNrOfRepetition" BO_ 295 0;
BA_ "GenMsgCycleTime" BO_ 295 20;
BA_ "GenMsgILSupport" BO_ 295 1;
BA_ "GenMsgILSupport" BO_ 1111 1;
BA_ "GenMsgNrOfRepetition" BO_ 1111 0;
BA_ "GenMsgCycleTime" BO_ 1111 100;
BA_ "GenMsgILSupport" BO_ 1067 1;
BA_ "GenMsgNrOfRepetition" BO_ 1067 0;
BA_ "GenMsgCycleTime" BO_ 1067 100;
BA_ "GenMsgILSupport" BO_ 1057 1;
BA_ "GenMsgNrOfRepetition" BO_ 1057 0;
BA_ "GenMsgCycleTime" BO_ 1057 100;
BA_ "GenMsgILSupport" BO_ 1046 1;
BA_ "GenMsgNrOfRepetition" BO_ 1046 0;
BA_ "GenMsgCycleTime" BO_ 1046 100;
BA_ "GenMsgILSupport" BO_ 1142 1;
BA_ "GenMsgNrOfRepetition" BO_ 1142 0;
BA_ "GenMsgCycleTime" BO_ 1142 100;
BA_ "GenMsgILSupport" BO_ 1044 1;
BA_ "GenMsgNrOfRepetition" BO_ 1044 0;
BA_ "GenMsgCycleTime" BO_ 1044 100;
BA_ "GenMsgILSupport" BO_ 1034 1;
BA_ "GenMsgNrOfRepetition" BO_ 1034 0;
BA_ "GenMsgCycleTime" BO_ 1034 100;
BA_ "GenMsgILSupport" BO_ 1183 1;
BA_ "GenMsgNrOfRepetition" BO_ 1183 0;
BA_ "GenMsgCycleTime" BO_ 1183 100;
BA_ "GenMsgILSupport" BO_ 1472 1;
BA_ "GenMsgNrOfRepetition" BO_ 1472 0;
BA_ "GenMsgCycleTime" BO_ 1472 1000;
BA_ "GenMsgILSupport" BO_ 1449 1;
BA_ "GenMsgNrOfRepetition" BO_ 1449 0;
BA_ "GenMsgCycleTime" BO_ 1449 1000;
BA_ "GenMsgILSupport" BO_ 1448 1;
BA_ "GenMsgNrOfRepetition" BO_ 1448 0;
BA_ "GenMsgCycleTime" BO_ 1448 1000;
BA_ "GenMsgILSupport" BO_ 1436 1;
BA_ "GenMsgNrOfRepetition" BO_ 1436 0;
BA_ "GenMsgCycleTime" BO_ 1436 1000;
BA_ "GenMsgILSupport" BO_ 1103 1;
BA_ "GenMsgNrOfRepetition" BO_ 1103 0;
BA_ "GenMsgCycleTime" BO_ 1103 100;
BA_ "GenMsgILSupport" BO_ 1083 1;
BA_ "GenMsgNrOfRepetition" BO_ 1083 0;
BA_ "GenMsgCycleTime" BO_ 1083 100;
BA_ "GenMsgILSupport" BO_ 2047 1;
BA_ "GenMsgSendType" BO_ 2047 8;
BA_ "GenMsgCycleTimeFast" BO_ 2047 100;
BA_ "GenMsgILSupport" BO_ 856 1;
BA_ "GenMsgNrOfRepetition" BO_ 856 0;
BA_ "GenMsgCycleTime" BO_ 856 50;
BA_ "GenMsgILSupport" BO_ 1314 1;
BA_ "GenMsgNrOfRepetition" BO_ 1314 0;
BA_ "GenMsgCycleTime" BO_ 1314 500;
BA_ "GenMsgILSupport" BO_ 1025 1;
BA_ "GenMsgNrOfRepetition" BO_ 1025 0;
BA_ "GenMsgCycleTime" BO_ 1025 500;
BA_ "GenMsgILSupport" BO_ 803 1;
BA_ "GenMsgNrOfRepetition" BO_ 803 0;
BA_ "GenMsgCycleTime" BO_ 803 20;
BA_ "GenMsgILSupport" BO_ 1120 1;
BA_ "GenMsgNrOfRepetition" BO_ 1120 0;
BA_ "GenMsgCycleTime" BO_ 1120 500;
BA_ "GenMsgILSupport" BO_ 1338 1;
BA_ "GenMsgNrOfRepetition" BO_ 1338 0;
BA_ "GenMsgCycleTime" BO_ 1338 1000;
BA_ "GenMsgILSupport" BO_ 787 1;
BA_ "GenMsgNrOfRepetition" BO_ 787 0;
BA_ "GenMsgCycleTime" BO_ 787 20;
BA_ "GenMsgILSupport" BO_ 1136 1;
BA_ "GenMsgNrOfRepetition" BO_ 1136 0;
BA_ "GenMsgCycleTime" BO_ 1136 20;
BA_ "GenMsgILSupport" BO_ 1141 1;
BA_ "GenMsgNrOfRepetition" BO_ 1141 0;
BA_ "GenMsgCycleTime" BO_ 1141 100;
BA_ "GenMsgILSupport" BO_ 1050 1;
BA_ "GenMsgNrOfRepetition" BO_ 1050 0;
BA_ "GenMsgCycleTime" BO_ 1050 100;
BA_ "GenMsgILSupport" BO_ 1288 1;
BA_ "GenMsgNrOfRepetition" BO_ 1288 0;
BA_ "GenMsgCycleTime" BO_ 1288 500;
BA_ "GenMsgILSupport" BO_ 773 1;
BA_ "GenMsgNrOfRepetition" BO_ 773 0;
BA_ "GenMsgCycleTime" BO_ 773 50;
BA_ "GenMsgILSupport" BO_ 1241 1;
BA_ "GenMsgNrOfRepetition" BO_ 1241 0;
BA_ "GenMsgCycleTime" BO_ 1241 100;
BA_ "GenMsgILSupport" BO_ 632 1;
BA_ "GenMsgNrOfRepetition" BO_ 632 0;
BA_ "GenMsgCycleTime" BO_ 632 50;
BA_ "GenMsgILSupport" BO_ 1202 1;
BA_ "GenMsgNrOfRepetition" BO_ 1202 0;
BA_ "GenMsgCycleTime" BO_ 1202 20;
BA_ "GenMsgILSupport" BO_ 1507 1;
BA_ "GenMsgCycleTime" BO_ 1507 1000;
BA_ "GenMsgCycleTimeFast" BO_ 1507 20;
BA_ "GenMsgILSupport" BO_ 1518 1;
BA_ "GenMsgSendType" BO_ 1518 8;
BA_ "GenMsgCycleTimeFast" BO_ 1518 100;
BA_ "GenMsgILSupport" BO_ 1517 1;
BA_ "GenMsgCycleTimeFast" BO_ 1517 100;
BA_ "GenMsgCycleTime" BO_ 1517 1000;
BA_ "GenMsgILSupport" BO_ 1504 1;
BA_ "GenMsgCycleTime" BO_ 1504 1000;
BA_ "GenMsgCycleTimeFast" BO_ 1504 20;
BA_ "GenMsgILSupport" BO_ 1168 1;
BA_ "GenMsgNrOfRepetition" BO_ 1168 0;
BA_ "GenMsgCycleTime" BO_ 1168 100;
BA_ "GenMsgILSupport" BO_ 936 1;
BA_ "GenMsgNrOfRepetition" BO_ 936 0;
BA_ "GenMsgCycleTime" BO_ 936 100;
BA_ "GenMsgILSupport" BO_ 1492 1;
BA_ "GenMsgNrOfRepetition" BO_ 1492 0;
BA_ "GenMsgCycleTime" BO_ 1492 100;
BA_ "GenMsgILSupport" BO_ 1476 1;
BA_ "GenMsgNrOfRepetition" BO_ 1476 0;
BA_ "GenMsgCycleTime" BO_ 1476 1000;
BA_ "GenSigSendType" SG_ 3221225472 SET_Rmirror_UD_Locaton 4;
BA_ "GenSigSendType" SG_ 3221225472 SET_Rmirror_LR_Locaton 4;
BA_ "GenSigSendType" SG_ 3221225472 SET_Lmirror_UD_Locaton 4;
BA_ "GenSigSendType" SG_ 3221225472 SET_Lmirror_LR_Locaton 4;
BA_ "GenSigSendType" SG_ 3221225472 IHU_StopChargeSW 2;
BA_ "GenSigSendType" SG_ 1796 eLSD_Request_frame_type 2;
BA_ "GenSigSendType" SG_ 1812 eLSD_response_frame_type 2;
BA_ "GenSigSendType" SG_ 1794 AWD_Request_frame_type 2;
BA_ "GenSigSendType" SG_ 1810 AWD_response_frame_type 2;
BA_ "GenSigSendType" SG_ 1854 Diag_FCM_RES 2;
BA_ "GenSigSendType" SG_ 1838 FCM_Request_Frame_Type 2;
BA_ "GenSigSendType" SG_ 1906 Diag_CGW_RES 2;
BA_ "GenSigSendType" SG_ 1890 Diag_CGW_REQ 2;
BA_ "GenSigSendType" SG_ 2015 Request_Broadcast 1;
BA_ "GenSigSendType" SG_ 1793 DVR_Request_Frame_Type 1;
BA_ "GenSigSendType" SG_ 1798 FPLA_Request_Frame_Type 1;
BA_ "GenSigSendType" SG_ 1804 EAC_Request_Frame_Type 1;
BA_ "GenSigSendType" SG_ 1809 DVR_Response_Frame_Type 1;
BA_ "GenSigSendType" SG_ 1814 FPLA_Response_Frame_Type 1;
BA_ "GenSigSendType" SG_ 1820 EAC_response_frame_type 1;
BA_ "GenSigSendType" SG_ 1827 DWD_Request_Frame_Type 1;
BA_ "GenSigSendType" SG_ 1830 PLG_Request 1;
BA_ "GenSigSendType" SG_ 1833 ATCM_Request_frame_type 1;
BA_ "GenSigSendType" SG_ 1843 DWD_Response_Frame_Type 1;
BA_ "GenSigSendType" SG_ 1846 PLG_response 1;
BA_ "GenSigSendType" SG_ 1849 ATCMResponse_Frame_Type 1;
BA_ "GenSigSendType" SG_ 1860 WCM_Request_Frame_Type 1;
BA_ "GenSigSendType" SG_ 1864 BSD_Request_frame_type 1;
BA_ "GenSigSendType" SG_ 1867 IPM_Request_Frame_Type 1;
BA_ "GenSigSendType" SG_ 1869 IMMO_Request_Frame_Type 1;
BA_ "GenSigSendType" SG_ 1870 PTC_Request_Frame_Type 1;
BA_ "GenSigSendType" SG_ 1876 WCM_Response_Frame_Type 1;
BA_ "GenSigSendType" SG_ 1880 BSD_response_frame_type 1;
BA_ "GenSigSendType" SG_ 1883 IPM_response_frame_type 1;
BA_ "GenSigSendType" SG_ 1885 IMMO_response_frame_type 1;
BA_ "GenSigSendType" SG_ 1886 PTC_response_frame_type 1;
BA_ "GenSigSendType" SG_ 1888 CEM_Request_frame_type 1;
BA_ "GenSigSendType" SG_ 1891 Radar_Request_Frame_Type 1;
BA_ "GenSigSendType" SG_ 1898 RFR_Request_Frame_Type 1;
BA_ "GenSigSendType" SG_ 1899 APM_Request_Frame_Type 1;
BA_ "GenSigSendType" SG_ 1904 CEM_response_frame_type 1;
BA_ "GenSigSendType" SG_ 1907 Radar_response_frame_type 1;
BA_ "GenSigSendType" SG_ 1914 RFR_response_frame_type 1;
BA_ "GenSigSendType" SG_ 1915 APM_response_frame_type 1;
BA_ "GenSigSendType" SG_ 1927 AMPRequest_Frame_Type 1;
BA_ "GenSigSendType" SG_ 1943 AMPResponse_Frame_Type 1;
BA_ "GenSigSendType" SG_ 1997 TRM_Request_frame_type 1;
BA_ "GenSigSendType" SG_ 2013 TRM_response_frame_type 1;
BA_ "GenSigSendType" SG_ 1811 DIAG_RESP_TCU 1;
BA_ "GenSigSendType" SG_ 2017 Diag_TCU_REQ 1;
BA_ "GenSigSendType" SG_ 1884 Diag_TBOX_RES 1;
BA_ "GenSigSendType" SG_ 1868 Diag_TBOX_REQ 1;
BA_ "GenSigSendType" SG_ 1940 Diag_RRCR_RES 1;
BA_ "GenSigSendType" SG_ 1924 RRCR_Request_Frame_Type 1;
BA_ "GenSigSendType" SG_ 1939 Diag_RLCR_RES 1;
BA_ "GenSigSendType" SG_ 1923 RLCR_Request_Frame_Type 1;
BA_ "GenSigSendType" SG_ 1795 DIAG_REQ_TCU 1;
BA_ "GenSigSendType" SG_ 2031 Diag_OBD_ESP_RES 1;
BA_ "GenSigSendType" SG_ 2023 Diag_OBD_ESP_REQ 1;
BA_ "GenSigSendType" SG_ 2025 DIAG_OBD_RESP_TCU 1;
BA_ "GenSigSendType" SG_ 2042 Diag_OBD_ESP_RES 1;
BA_ "GenSigSendType" SG_ 2034 Diag_OBD_ESP_REQ 1;
BA_ "GenSigSendType" SG_ 1844 Diag_OBD_EPS_RES 1;
BA_ "GenSigSendType" SG_ 1828 Diag_OBD_EPS_REQ 1;
BA_ "GenSigSendType" SG_ 1919 MFS_response_frame_type 1;
BA_ "GenSigSendType" SG_ 1903 MFS_Request_Frame_Type 1;
BA_ "GenSigSendType" SG_ 1918 MFS_response_frame_type 1;
BA_ "GenSigSendType" SG_ 1902 MFS_Request_Frame_Type 1;
BA_ "GenSigSendType" SG_ 1946 Diag_MCUR_RES 1;
BA_ "GenSigSendType" SG_ 1818 Diag_MCUR_REQ 1;
BA_ "GenSigSendType" SG_ 2027 Diag_MCUF_RES 1;
BA_ "GenSigSendType" SG_ 2019 Diag_MCUF_REQ 1;
BA_ "GenSigSendType" SG_ 1819 Diag_ISGF_RES 1;
BA_ "GenSigSendType" SG_ 1803 Diag_ISGF_REQ 1;
BA_ "GenSigSendType" SG_ 1972 Diag_IPB2_RES 1;
BA_ "GenSigSendType" SG_ 1953 Diag_IPB2_REQ 1;
BA_ "GenSigSendType" SG_ 1840 Diag_IPB_RES 1;
BA_ "GenSigSendType" SG_ 1824 Diag_IPB_REQ 1;
BA_ "GenSigSendType" SG_ 1882 IHU_Response_Frame_Type_1 1;
BA_ "GenSigSendType" SG_ 1866 HUD_Request_Frame_Type 1;
BA_ "GenSigSendType" SG_ 2026 DIAG_HCU_RES 1;
BA_ "GenSigSendType" SG_ 2018 DIAG_HCU_REQ 1;
BA_ "GenSigSendType" SG_ 1855 Diag_FRM_RES 1;
BA_ "GenSigSendType" SG_ 1839 FRM_Request_Frame_Type 1;
BA_ "GenSigSendType" SG_ 1841 DIAG_EPB_RES 1;
BA_ "GenSigSendType" SG_ 1825 DIAG_EPB_REQ 1;
BA_ "GenSigSendType" SG_ 1822 Diag_EOP_RES 1;
BA_ "GenSigSendType" SG_ 1806 Diag_EOP_REQ 1;
BA_ "GenSigSendType" SG_ 2024 Diag_EMS_RES 1;
BA_ "GenSigSendType" SG_ 2016 Diag_EMS_REQ 1;
BA_ "GenSigSendType" SG_ 1947 EGS_Response_Frame_Type 1;
BA_ "GenSigSendType" SG_ 1931 EGS_Request_Frame_type 1;
BA_ "GenSigSendType" SG_ 2008 EGS_Response_Frame_Type1 1;
BA_ "GenSigSendType" SG_ 2000 EGS_Request_Frame_type1 1;
BA_ "GenSigSendType" SG_ 2030 Diag_CDU_RES 1;
BA_ "GenSigSendType" SG_ 2022 Diag_CDU_REQ 1;
BA_ "GenSigSendType" SG_ 1942 BSCU_response_frame_type 1;
BA_ "GenSigSendType" SG_ 1926 BSCU_Request_Frame_Type 1;
BA_ "GenSigSendType" SG_ 2029 Diag_BMS_RES 1;
BA_ "GenSigSendType" SG_ 2021 Diag_BMS_REQ 1;
BA_ "GenSigSendType" SG_ 1968 BBCM_response_frame_type 1;
BA_ "GenSigSendType" SG_ 1952 BBCM_Request_Frame_Type 1;
BA_ "GenSigSendType" SG_ 1975 AVAS_Response_Frame_Type 1;
BA_ "GenSigSendType" SG_ 1959 AVAS_Request_frame_type 1;
BA_ "GenSigSendType" SG_ 1910 APA_response_frame_type 1;
BA_ "GenSigSendType" SG_ 1894 APA_Request_Frame_Type 1;
BA_ "GenSigSendType" SG_ 1845 Diag_ADCC_RES 1;
BA_ "GenSigSendType" SG_ 1829 ADCC_Request_Frame_Type 1;
BA_ "GenSigSendType" SG_ 2041 ABM_Response_Frame_Type_1 1;
BA_ "GenSigSendType" SG_ 2033 ABM_Request_Frame_Type_1 1;
BA_ "GenSigSendType" SG_ 1887 CLM_response_frame_type 1;
BA_ "GenSigSendType" SG_ 1871 CLM_Request_Frame_Type 1;
BA_ "GenSigSendType" SG_ 1533 AVM_1_BlindModeFeedback 2;
BA_ "GenSigSendType" SG_ 1533 AVM_1_AVM_Assist_DisplayMode 2;
BA_ "GenSigSendType" SG_ 1533 GearR_Open_APA_AVM_Feedback 2;
BA_ "GenSigSendType" SG_ 1533 AVM_1_SetPDCTriggerClassFeedback 2;
BA_ "GenSigSendType" SG_ 1533 AVM_1_OverspeedSwFeedback 2;
BA_ "GenSigSendType" SG_ 1533 AVM_1_BVSetFeedback 2;
BA_ "GenSigSendType" SG_ 826 Area_Parking_Frame_Selected_Area 2;
BA_ "GenSigStartValue" SG_ 826 Area_Parking_Frame_Selected_Area 1024;
BA_ "SystemSignalLongSymbol" SG_ 826 Area_Parking_Frame_Selected_Area "Area_Parking_Frame_Selected_Area__Upper_left__Point_Abscissa_Y";
BA_ "GenSigSendType" SG_ 826 Area_Parking_Frame_Selected_0000 2;
BA_ "GenSigStartValue" SG_ 826 Area_Parking_Frame_Selected_0000 1024;
BA_ "SystemSignalLongSymbol" SG_ 826 Area_Parking_Frame_Selected_0000 "Area_Parking_Frame_Selected_Area__Upper_left_Point__Abscissa_X";
BA_ "GenSigSendType" SG_ 826 SDK_Opposite_End_Application_Unr 2;
BA_ "SystemSignalLongSymbol" SG_ 826 SDK_Opposite_End_Application_Unr "SDK_Opposite_End_Application_Unresponsive";
BA_ "GenSigSendType" SG_ 826 SDK_Unknow_Error 2;
BA_ "GenSigSendType" SG_ 826 SDK_Network_Link_Error 2;
BA_ "GenSigSendType" SG_ 826 SDK_Opposite_End_Application_Err 2;
BA_ "SystemSignalLongSymbol" SG_ 826 SDK_Opposite_End_Application_Err "SDK_Opposite_End_Application_Error";
BA_ "GenSigSendType" SG_ 826 USB_TBOX_Connection_Status 2;
BA_ "GenSigSendType" SG_ 824 APA_Target_Parking_Space_ID 2;
BA_ "GenSigSendType" SG_ 824 VPA_User_Chooses_to_Delete_Map_I 2;
BA_ "SystemSignalLongSymbol" SG_ 824 VPA_User_Chooses_to_Delete_Map_I "VPA_User_Chooses_to_Delete_Map_Identifier";
BA_ "GenSigSendType" SG_ 824 Map_Uploda_ID 2;
BA_ "GenSigSendType" SG_ 824 Area_Parking_Frame_Selected_0001 2;
BA_ "GenSigStartValue" SG_ 824 Area_Parking_Frame_Selected_0001 1024;
BA_ "SystemSignalLongSymbol" SG_ 824 Area_Parking_Frame_Selected_0001 "Area_Parking_Frame_Selected_Area_Bottom_Right_Point_Abscissa_Y";
BA_ "GenSigSendType" SG_ 824 Area_Parking_Frame_Selected_0002 2;
BA_ "GenSigStartValue" SG_ 824 Area_Parking_Frame_Selected_0002 1024;
BA_ "SystemSignalLongSymbol" SG_ 824 Area_Parking_Frame_Selected_0002 "Area_Parking_Frame_Selected_Area_Bottom_Right_Point_Abscissa_X";
BA_ "GenSigSendType" SG_ 824 Target_Map_ID_Selected_By_User 2;
BA_ "GenSigSendType" SG_ 824 TICE_Appointed_Parking_Space_ID 2;
BA_ "GenSigSendType" SG_ 823 IHU_GearR_APA_AVM_OP_SW 2;
BA_ "GenSigSendType" SG_ 823 Over_Speed_Remind_Warning_Mode_S 2;
BA_ "SystemSignalLongSymbol" SG_ 823 Over_Speed_Remind_Warning_Mode_S "Over_Speed_Remind_Warning_Mode_Set_Request";
BA_ "GenSigSendType" SG_ 823 Map_Train_Type 2;
BA_ "GenSigSendType" SG_ 823 IHU_AVM_Set_BV_OP_SW 2;
BA_ "GenSigSendType" SG_ 823 Low_Speed_Auto_Parking_Space_Det 2;
BA_ "SystemSignalLongSymbol" SG_ 823 Low_Speed_Auto_Parking_Space_Det "Low_Speed_Auto_Parking_Space_Detection_Function_Switch_Set_Request";
BA_ "GenSigSendType" SG_ 823 Map_Operation_Command 2;
BA_ "GenSigSendType" SG_ 823 Trained_Parking_Mode_Selection 2;
BA_ "GenSigSendType" SG_ 823 TRA_Command 2;
BA_ "GenSigSendType" SG_ 823 TICE_Vehicle_Restore_Factory_Set 2;
BA_ "SystemSignalLongSymbol" SG_ 823 TICE_Vehicle_Restore_Factory_Set "TICE_Vehicle_Restore_Factory_Set_Request_Status";
BA_ "GenSigSendType" SG_ 823 TICE_Vehicle_Restore_Factor_0000 2;
BA_ "SystemSignalLongSymbol" SG_ 823 TICE_Vehicle_Restore_Factor_0000 "TICE_Vehicle_Restore_Factory_Set_Request";
BA_ "GenSigSendType" SG_ 823 Initial_D_Gear_Open_AVM_Switch_S 2;
BA_ "SystemSignalLongSymbol" SG_ 823 Initial_D_Gear_Open_AVM_Switch_S "Initial_D_Gear_Open_AVM_Switch_Set_Request";
BA_ "GenSigSendType" SG_ 823 Low_Speed_Auto_Location_Function 2;
BA_ "SystemSignalLongSymbol" SG_ 823 Low_Speed_Auto_Location_Function "Low_Speed_Auto_Location_Function__Switch_Set_Request";
BA_ "GenSigSendType" SG_ 823 TICE_Trained_Parking_Command 2;
BA_ "GenSigSendType" SG_ 823 TICE_Trained_Parking_Out_Command 2;
BA_ "GenSigSendType" SG_ 823 Trained_Parking_Self_Learning_An 2;
BA_ "SystemSignalLongSymbol" SG_ 823 Trained_Parking_Self_Learning_An "Trained_Parking_Self_Learning_And_Self_Positioning_Function_User_Set_Request";
BA_ "GenSigSendType" SG_ 823 Driving_Function_User_Learning_S 2;
BA_ "SystemSignalLongSymbol" SG_ 823 Driving_Function_User_Learning_S "Driving_Function_User_Learning_Status";
BA_ "GenSigSendType" SG_ 823 MOD_Route_Map_Operation_Command 2;
BA_ "GenSigSendType" SG_ 823 Location_Command 2;
BA_ "GenSigSendType" SG_ 823 VPA_Request_to_Display_Route_Lis 2;
BA_ "SystemSignalLongSymbol" SG_ 823 VPA_Request_to_Display_Route_Lis "VPA_Request_to_Display_Route_List";
BA_ "GenSigSendType" SG_ 823 Parking_Function_User_Learning_S 2;
BA_ "SystemSignalLongSymbol" SG_ 823 Parking_Function_User_Learning_S "Parking_Function_User_Learning_Status";
BA_ "GenSigSendType" SG_ 823 MOD_Function_Run_Operation_Comma 2;
BA_ "SystemSignalLongSymbol" SG_ 823 MOD_Function_Run_Operation_Comma "MOD_Function_Run_Operation_Command";
BA_ "GenSigSendType" SG_ 823 MOD_Request_to_Display_Route_Lis 2;
BA_ "SystemSignalLongSymbol" SG_ 823 MOD_Request_to_Display_Route_Lis "MOD_Request_to_Display_Route_List";
BA_ "GenSigSendType" SG_ 822 IHU_AVM_Set_EmergencyBrake 2;
BA_ "GenSigSendType" SG_ 822 Over_Speed_Close_AVM_Set_Request 2;
BA_ "GenSigStartValue" SG_ 822 Over_Speed_Close_AVM_Set_Request 2;
BA_ "GenSigSendType" SG_ 822 VPA_User_Requests_Single_Map_Ide 2;
BA_ "SystemSignalLongSymbol" SG_ 822 VPA_User_Requests_Single_Map_Ide "VPA_User_Requests_Single_Map_Identifier";
BA_ "GenSigSendType" SG_ 822 VPA_User_Specify_Target_Floor_Id 2;
BA_ "SystemSignalLongSymbol" SG_ 822 VPA_User_Specify_Target_Floor_Id "VPA_User_Specify_Target_Floor_Identifier";
BA_ "GenSigSendType" SG_ 822 VPA_User_Select_Top_Map_Identifi 2;
BA_ "SystemSignalLongSymbol" SG_ 822 VPA_User_Select_Top_Map_Identifi "VPA_User_Select_Top_Map_Identifier";
BA_ "GenSigSendType" SG_ 822 MOD_User_Selects_Delete_Map_Iden 2;
BA_ "SystemSignalLongSymbol" SG_ 822 MOD_User_Selects_Delete_Map_Iden "MOD_User_Selects_Delete_Map_Identifier";
BA_ "GenSigSendType" SG_ 822 MOD_Preview_Map_Identifier 2;
BA_ "GenSigSendType" SG_ 822 MOD_User_Selects_Top_Map_Identif 2;
BA_ "SystemSignalLongSymbol" SG_ 822 MOD_User_Selects_Top_Map_Identif "MOD_User_Selects_Top_Map_Identifier";
BA_ "GenSigSendType" SG_ 822 MOD_User_Selects_Enable_Map_Iden 2;
BA_ "SystemSignalLongSymbol" SG_ 822 MOD_User_Selects_Enable_Map_Iden "MOD_User_Selects_Enable_Map_Identifier";
BA_ "GenSigSendType" SG_ 828 APA_Pullout_Engage_Confirm 2;
BA_ "GenSigSendType" SG_ 828 IHU_APA_PullOut_Direction 2;
BA_ "GenSigSendType" SG_ 828 IHU_APA_Combi_Sw 2;
BA_ "GenSigSendType" SG_ 828 IHU_APA_Prompt_Confirm 2;
BA_ "GenSigSendType" SG_ 828 IHU_APA_Heartbeat 2;
BA_ "GenSigSendType" SG_ 828 IHU_RPA_Engage_Confirm 2;
BA_ "GenSigSendType" SG_ 828 IHU_RPA_OP_SW 2;
BA_ "GenSigSendType" SG_ 828 IHU_AVM_Set_AutoExit 2;
BA_ "GenSigSendType" SG_ 828 IHU_AVM_Set_LicensePlate 2;
BA_ "GenSigSendType" SG_ 828 IHU_AVM_Set_GuideLine 2;
BA_ "GenSigSendType" SG_ 828 IHU_AVM_Set_FactoryDefault 2;
BA_ "GenSigSendType" SG_ 828 IHU_AVM_Set_PASTrigger 2;
BA_ "GenSigSendType" SG_ 828 APA_Parkin_Engage_Confirm 2;
BA_ "GenSigSendType" SG_ 828 DataCollAuthSw 2;
BA_ "GenSigSendType" SG_ 828 FCTASwtSet 2;
BA_ "GenSigSendType" SG_ 828 FCTBrkSwtSet 2;
BA_ "GenSigSendType" SG_ 828 IHU_AVM_Set_TurnIndication 2;
BA_ "GenSigSendType" SG_ 828 IHU_AVM_Set_BodyColor 2;
BA_ "GenSigSendType" SG_ 828 IHU_AVM_Set_AutoZoom 2;
BA_ "GenSigSendType" SG_ 828 IHU_AVM_OP_SW 2;
BA_ "GenSigSendType" SG_ 828 IHU_AVM_Set_SteeringWheel 2;
BA_ "GenSigSendType" SG_ 828 IHU_AVM_Set_Language 2;
BA_ "GenSigSendType" SG_ 828 IHU_AVM_Set_RadarWarining 2;
BA_ "GenSigSendType" SG_ 828 IHU_APA_PullOut_Option 2;
BA_ "GenSigSendType" SG_ 828 IHU_APA_ParkIn_Direction 2;
BA_ "GenSigSendType" SG_ 828 IHU_APA_Suspend_Resume 2;
BA_ "GenSigSendType" SG_ 828 IHU_APA_Engage_Confirm 2;
BA_ "GenSigSendType" SG_ 828 IHU_APA_Slot_Chosen 2;
BA_ "GenSigSendType" SG_ 828 IHU_APA_OP_SW 2;
BA_ "GenSigSendType" SG_ 827 SelfSelectionParking_OP_SW 2;
BA_ "GenSigSendType" SG_ 827 IHU_AVM_Set_PASTrigger_Class 2;
BA_ "GenSigSendType" SG_ 827 IHU_AVM_Set_Blind_Mode_OP_SW 2;
BA_ "GenSigSendType" SG_ 827 IHU_AVM_Zoom_Request 2;
BA_ "GenSigSendType" SG_ 827 APA_ActivateReq 2;
BA_ "GenSigSendType" SG_ 827 IHU_Frontcamera_CalibrationReq 2;
BA_ "GenSigSendType" SG_ 827 IHU_Rearcamera_CalibrationReq 2;
BA_ "GenSigSendType" SG_ 827 IHU_AVM_TransparentHoodSwitch 2;
BA_ "GenSigSendType" SG_ 827 IHU_AVM_TrailSwitch 2;
BA_ "GenSigSendType" SG_ 827 IHU_AVM_CalibrationReq 2;
BA_ "GenSigSendType" SG_ 827 IHU_AVM_TouchEvt 2;
BA_ "GenSigSendType" SG_ 827 IHU_AVM_ViewModeSwitch 2;
BA_ "GenSigSendType" SG_ 827 IHU_AVM_BtnPressInputValueY 2;
BA_ "GenSigSendType" SG_ 827 IHU_AVM_BtnPressInputValueX 2;
BA_ "GenSigSendType" SG_ 1073 CEM_CarMode 2;
BA_ "SystemSignalLongSymbol" SG_ 1015 ADCC_9_SentinelMode_SensitivityS "ADCC_9_SentinelMode_SensitivitySts";
BA_ "GenSigStartValue" SG_ 934 BCM_12_EBS_Current 65534.72;
BA_ "GenSigStartValue" SG_ 934 BCM_12_EBS_Voltage 16373.76;
BA_ "GenSigSendType" SG_ 1040 Set_AMPExSoundmode 2;
BA_ "GenSigSendType" SG_ 1040 Set_AMPA2BConfig 2;
BA_ "GenSigSendType" SG_ 1040 Set_AMPSoundBypass 2;
BA_ "GenSigSendType" SG_ 1040 Set_VirtualSbwfrOnOff 2;
BA_ "GenSigSendType" SG_ 1167 ICC_DrivePowerDispSet 2;
BA_ "GenSigSendType" SG_ 1167 ICC_V2L_IntlDisChg 2;
BA_ "GenSigStartValue" SG_ 1336 LPN_Info7 127;
BA_ "GenSigStartValue" SG_ 1336 LPN_Info8 127;
BA_ "GenSigStartValue" SG_ 1336 LPN_Info6 127;
BA_ "GenSigStartValue" SG_ 1336 LPN_Info5 127;
BA_ "GenSigStartValue" SG_ 1336 LPN_Info4 127;
BA_ "GenSigStartValue" SG_ 1336 LPN_Info3 127;
BA_ "GenSigStartValue" SG_ 1336 LPN_Info2 127;
BA_ "GenSigStartValue" SG_ 1336 LPN_Info1 127;
BA_ "GenSigSendType" SG_ 1298 IHU_RestAreaSet 2;
BA_ "GenSigSendType" SG_ 1298 SET_DriverSeat_MassageModeReq 2;
BA_ "GenSigSendType" SG_ 1298 SET_DriverSeat_MassageStsReq 2;
BA_ "GenSigSendType" SG_ 1298 SET_DriverSeat_MassageVibrationR 2;
BA_ "SystemSignalLongSymbol" SG_ 1298 SET_DriverSeat_MassageVibrationR "SET_DriverSeat_MassageVibrationReq";
BA_ "GenSigSendType" SG_ 1521 DVR_IHU_Data7 2;
BA_ "GenSigSendType" SG_ 1521 DVR_IHU_Data6 2;
BA_ "GenSigSendType" SG_ 1521 DVR_IHU_Data5 2;
BA_ "GenSigSendType" SG_ 1521 DVR_IHU_Data4 2;
BA_ "GenSigSendType" SG_ 1521 DVR_IHU_Data3 2;
BA_ "GenSigSendType" SG_ 1521 DVR_IHU_Data2 2;
BA_ "GenSigSendType" SG_ 1521 DVR_IHU_Data1 2;
BA_ "GenSigSendType" SG_ 1521 DVR_IHU_Data0 2;
BA_ "GenSigSendType" SG_ 1520 IHU_DVR_Data7 2;
BA_ "GenSigSendType" SG_ 1520 IHU_DVR_Data6 2;
BA_ "GenSigSendType" SG_ 1520 IHU_DVR_Data5 2;
BA_ "GenSigSendType" SG_ 1520 IHU_DVR_Data4 2;
BA_ "GenSigSendType" SG_ 1520 IHU_DVR_Data3 2;
BA_ "GenSigSendType" SG_ 1520 IHU_DVR_Data2 2;
BA_ "GenSigSendType" SG_ 1520 IHU_DVR_Data1 2;
BA_ "GenSigSendType" SG_ 1520 IHU_DVR_Data0 2;
BA_ "GenSigSendType" SG_ 1349 IPM1_FRTempSwitchReq 2;
BA_ "GenSigSendType" SG_ 1349 IPM1_SetFrontDeforestSts 2;
BA_ "GenSigSendType" SG_ 1349 IPM1_RearDefrostSwitchReq 2;
BA_ "GenSigSendType" SG_ 1349 IPM1_RecyModeReq 2;
BA_ "GenSigSendType" SG_ 1349 IPM1_FrontAutoACSwitchReq 2;
BA_ "GenSigStartValue" SG_ 1349 IPM1_FrontBlowModeSwitchReq 7;
BA_ "GenSigSendType" SG_ 1349 IPM1_FrontBlowModeSwitchReq 2;
BA_ "GenSigStartValue" SG_ 1349 IPM1_FrontBlowSpdCtrlSwitchReq 15;
BA_ "GenSigSendType" SG_ 1349 IPM1_FrontBlowSpdCtrlSwitchReq 2;
BA_ "GenSigSendType" SG_ 1349 IPM1_ACSwitchReq 2;
BA_ "GenSigSendType" SG_ 1349 IPM1_FLTempSwitchReq 2;
BA_ "GenSigStartValue" SG_ 1480 NextTrafficSts 3;
BA_ "GenSigStartValue" SG_ 1480 TrafficSts 3;
BA_ "GenSigSendType" SG_ 1416 IHU_24_Reservation_SentinelReq 2;
BA_ "GenSigSendType" SG_ 1416 IHU_24_TimeToStopSentinelMinuteS 2;
BA_ "SystemSignalLongSymbol" SG_ 1416 IHU_24_TimeToStopSentinelMinuteS "IHU_24_TimeToStopSentinelMinuteSet";
BA_ "GenSigSendType" SG_ 1416 IHU_24_TimeToStopSentinelHourSet 2;
BA_ "GenSigSendType" SG_ 1416 IHU_24_TimeToStartSentinelMinute 2;
BA_ "SystemSignalLongSymbol" SG_ 1416 IHU_24_TimeToStartSentinelMinute "IHU_24_TimeToStartSentinelMinuteSet";
BA_ "GenSigSendType" SG_ 1416 IHU_24_TimeToStartSentinelHourSe 2;
BA_ "SystemSignalLongSymbol" SG_ 1416 IHU_24_TimeToStartSentinelHourSe "IHU_24_TimeToStartSentinelHourSet";
BA_ "GenSigSendType" SG_ 1416 IHU_24_TimeToStartSentinelDaySet 2;
BA_ "GenSigSendType" SG_ 1416 IHU_24_SentinelMode_SensitivityR 2;
BA_ "SystemSignalLongSymbol" SG_ 1416 IHU_24_SentinelMode_SensitivityR "IHU_24_SentinelMode_SensitivityReq";
BA_ "GenSigSendType" SG_ 1416 IHU_24_SentinelModeSwitchReq 2;
BA_ "GenSigSendType" SG_ 1416 IHU_24_Sentinel_RemoteLockFeedba 2;
BA_ "SystemSignalLongSymbol" SG_ 1416 IHU_24_Sentinel_RemoteLockFeedba "IHU_24_Sentinel_RemoteLockFeedbackReq";
BA_ "GenSigSendType" SG_ 1416 FollowingTrackToReverse 2;
BA_ "GenSigSendType" SG_ 1416 RPASwitch 2;
BA_ "GenSigSendType" SG_ 1416 Ready2GoSwitch 2;
BA_ "GenSigSendType" SG_ 1416 IESSwtSet 2;
BA_ "GenSigSendType" SG_ 1416 IHU_11_TSISwtSet 2;
BA_ "GenSigSendType" SG_ 1416 ELK_Switch 2;
BA_ "GenSigSendType" SG_ 1416 DCLC_Switch 2;
BA_ "GenSigSendType" SG_ 1416 RCW_OnOffSt 2;
BA_ "GenSigSendType" SG_ 1416 RCTB_OnOffSt 2;
BA_ "GenSigSendType" SG_ 1330 ElectcUnlckCmd 2;
BA_ "GenSigSendType" SG_ 1330 IHU_29_DchaSet 2;
BA_ "GenSigSendType" SG_ 1414 IHU_AMP_2_Set_AMPENCReq 2;
BA_ "GenSigSendType" SG_ 1414 IHU_AMP_2__AMPA2BENCSound 2;
BA_ "GenSigSendType" SG_ 1414 IHU_AMP_2_SoundEffectMidtreble 2;
BA_ "GenSigSendType" SG_ 1414 IHU_AMP_2_SoundEffectBassMid 2;
BA_ "GenSigSendType" SG_ 1414 IHU_19_Set_HdrestSpkrMod 2;
BA_ "GenSigSendType" SG_ 1414 REQ_AMPA2BMediaSound 2;
BA_ "GenSigSendType" SG_ 1414 IHU_19_SetIHUAlarm 2;
BA_ "GenSigSendType" SG_ 1414 IHU_19_Set_AMPESEVol 2;
BA_ "GenSigSendType" SG_ 1414 IHU_19_Set_AMPWelVol 2;
BA_ "GenSigSendType" SG_ 1414 IHU_19_Set_AMPBTMediVol 2;
BA_ "GenSigSendType" SG_ 1414 IHU_19_REQ_AMPA2BMediSound 2;
BA_ "GenSigSendType" SG_ 1414 IHU_19_REQ_AMPA2BESESound 2;
BA_ "GenSigSendType" SG_ 1414 REQ_AMPA2BKeyTone 2;
BA_ "GenSigSendType" SG_ 1414 REQ_AMPA2BTTSSound 2;
BA_ "GenSigSendType" SG_ 1414 REQ_AMPA2BVRSound 2;
BA_ "GenSigSendType" SG_ 1414 REQ_AMPA2BNaviSound 2;
BA_ "GenSigSendType" SG_ 1414 Set_AMPMute 2;
BA_ "GenSigSendType" SG_ 1414 Set_AMPSpeedVolume 2;
BA_ "GenSigSendType" SG_ 1414 REQ_AMPA2BPhoneSound 2;
BA_ "GenSigSendType" SG_ 1413 Set_AMPAlarmVolume 2;
BA_ "GenSigSendType" SG_ 1413 Set_AMPLoudness 2;
BA_ "GenSigSendType" SG_ 1413 Set_AMPLiveAcoustics 2;
BA_ "GenSigSendType" SG_ 1413 Set_AMPSoundFieldFader 2;
BA_ "GenSigSendType" SG_ 1413 Set_AMPSoundFieldBalance 2;
BA_ "GenSigSendType" SG_ 1413 Set_AMPSoundEffectTreble 2;
BA_ "GenSigSendType" SG_ 1413 Set_AMPSoundEffectMidrange 2;
BA_ "GenSigSendType" SG_ 1413 Set_AMPSoundEffectBass 2;
BA_ "GenSigSendType" SG_ 1413 Set_AMPSoundEffect 2;
BA_ "GenSigSendType" SG_ 1413 Set_AMPRestoreDefaults 2;
BA_ "GenSigSendType" SG_ 1413 Set_AMPDefaultVolume 2;
BA_ "GenSigSendType" SG_ 1413 Set_AMPSoundFocus 2;
BA_ "GenSigSendType" SG_ 1413 Set_AMPPhoneVolume 2;
BA_ "GenSigSendType" SG_ 1413 Set_AMPMediaVolume 2;
BA_ "GenSigSendType" SG_ 1413 Set_AMPKeyTone 2;
BA_ "GenSigSendType" SG_ 1413 Set_AMPVRVolume 2;
BA_ "GenSigSendType" SG_ 1413 Set_AMPNaviVolume 2;
BA_ "GenSigSendType" SG_ 1114 IHU_APA_3_MEB_Switch 2;
BA_ "GenSigSendType" SG_ 1114 IHU_APA_3_VoiceCtrldPrkgCmd 2;
BA_ "GenSigSendType" SG_ 1114 IHU_APA_3_AVMFloat 2;
BA_ "GenSigSendType" SG_ 1114 IHU_APA_3_KeySts 2;
BA_ "GenSigSendType" SG_ 1114 IHU_APA_3_CalibrationReq 2;
BA_ "GenSigSendType" SG_ 1114 IHU_APA_3_TouchEvt 2;
BA_ "GenSigStartValue" SG_ 1114 IHU_APA_3_NaviBtnPressInputValue 65535;
BA_ "GenSigSendType" SG_ 1114 IHU_APA_3_NaviBtnPressInputValue 2;
BA_ "SystemSignalLongSymbol" SG_ 1114 IHU_APA_3_NaviBtnPressInputValue "IHU_APA_3_NaviBtnPressInputValueY";
BA_ "GenSigStartValue" SG_ 1114 IHU_APA_3_NaviBtnPressInput_0000 65535;
BA_ "GenSigSendType" SG_ 1114 IHU_APA_3_NaviBtnPressInput_0000 2;
BA_ "SystemSignalLongSymbol" SG_ 1114 IHU_APA_3_NaviBtnPressInput_0000 "IHU_APA_3_NaviBtnPressInputValueX";
BA_ "GenSigSendType" SG_ 1114 IHU_APA_3_I_isplayAVMOff 2;
BA_ "GenSigSendType" SG_ 1114 IHU_APA_3_AVMSwt 2;
BA_ "GenSigSendType" SG_ 1360 ATCM_1_ESCOFF_ON_OFF 2;
BA_ "GenSigSendType" SG_ 1360 ATCM_1_AVH_ON_OFF 2;
BA_ "GenSigSendType" SG_ 1360 ATCM_CTP_EDL 2;
BA_ "GenSigSendType" SG_ 1360 ATCM_CCOSwtReq 2;
BA_ "GenSigSendType" SG_ 1360 ATCM_AVM 2;
BA_ "GenSigSendType" SG_ 1360 ATCM_XModeSw 2;
BA_ "GenSigStartValue" SG_ 1360 ATCM_DriveModeSw 6;
BA_ "GenSigSendType" SG_ 1360 ATCM_DriveModeSw 2;
BA_ "GenSigSendType" SG_ 1276 IHU_11_HMASwtSet 2;
BA_ "GenSigSendType" SG_ 1276 IHU_11_ELKSwtSet 2;
BA_ "GenSigSendType" SG_ 1276 IHU_11_LDWLDPSnvtySet 2;
BA_ "GenSigSendType" SG_ 1276 IHU_11_LDPSwtSet 2;
BA_ "GenSigSendType" SG_ 1276 IHU_11_WarnModSwtSet 2;
BA_ "GenSigSendType" SG_ 1276 IHU_11_LDWSwtSet 2;
BA_ "GenSigSendType" SG_ 1276 IHU_11_TLISwtSet 2;
BA_ "GenSigSendType" SG_ 1276 IHU_11_TSISwtSet 2;
BA_ "GenSigSendType" SG_ 1276 IHU_11_IESSwtSet 2;
BA_ "GenSigSendType" SG_ 1276 IHU_11_DAISwtSet 2;
BA_ "GenSigSendType" SG_ 1276 IHU_11_SCFSwtSet 2;
BA_ "GenSigSendType" SG_ 1276 IHU_11_SLASwtSet 2;
BA_ "GenSigSendType" SG_ 1276 IHU_11_TJAICAExitTextInfoSwtSet 2;
BA_ "GenSigSendType" SG_ 1276 IHU_11_FCWSnvtySet 2;
BA_ "GenSigSendType" SG_ 1276 IHU_11_FCWSwtSet 2;
BA_ "GenSigSendType" SG_ 1276 IHU_11_AEBSwtSet 2;
BA_ "GenSigSendType" SG_ 1322 IHU_OFFROAD_COOL 2;
BA_ "GenSigSendType" SG_ 1322 IHU_RBCM_EnergysavingMode 2;
BA_ "GenSigSendType" SG_ 1322 IHU_All_weather_light_switch 4;
BA_ "GenSigSendType" SG_ 1322 IHU_SET_LampLEDSwitch 4;
BA_ "GenSigStartValue" SG_ 1322 IHU_SET_LampLEDSwitch 2;
BA_ "GenSigSendType" SG_ 1322 SET_FrontWindscreenHeatiReq 4;
BA_ "GenSigSendType" SG_ 1322 SET_RRSeatHeatVentSwReq 4;
BA_ "GenSigSendType" SG_ 1322 SET_LRSeatHeatVentSwReq 4;
BA_ "GenSigStartValue" SG_ 295 YAS_1_LateraAccaleleration 2000;
BA_ "GenSigStartValue" SG_ 1067 OBC_ChargerTemp 40;
BA_ "GenSigStartValue" SG_ 1057 CruiseLimitSpeedValue 1;
BA_ "GenSigStartValue" SG_ 1142 HCU_4_G_SumEgyCns 250;
BA_ "GenSigStartValue" SG_ 1142 HCU_4_G_AvgEnergyCns 250;
BA_ "GenSigStartValue" SG_ 1142 HCU_4_G_AvgElecCns 1000;
BA_ "GenSigStartValue" SG_ 1034 HCU_EmPwr 128;
BA_ "GenSigStartValue" SG_ 1183 BMSH_BatteryCurrent 32000;
BA_ "GenSigStartValue" SG_ 1448 BMSH_TempSensor_MinTemp 40;
BA_ "GenSigStartValue" SG_ 1448 BMSH_TempSensor_MaxTemp 40;
BA_ "GenSigStartValue" SG_ 1103 BMSH_LeftChargeTime 1022;
BA_ "GenSigStartValue" SG_ 1083 BMSH_PackPowerRealTime 2000;
BA_ "GenSigSendType" SG_ 2047 Start_Aging 1;
BA_ "GenSigStartValue" SG_ 856 TBOX_TimeToStopChargeMinuteFed 62;
BA_ "GenSigStartValue" SG_ 856 TBOX_TimeToStopChargeHourFed 30;
BA_ "GenSigStartValue" SG_ 856 TBOX_TimeToStartChargeMinuteFed 62;
BA_ "GenSigStartValue" SG_ 856 TBOX_TimeToStartChargeHourFed 30;
BA_ "GenSigStartValue" SG_ 1338 PM2_5_Outdensity 65535;
BA_ "GenSigStartValue" SG_ 1338 PM2_5_Indensity 65535;
BA_ "GenSigStartValue" SG_ 1136 YAS_2_LongitudinalAcceleration 2000;
BA_ "GenSigStartValue" SG_ 1141 RAD2_LHSFRadarSensorDistance 126;
BA_ "GenSigStartValue" SG_ 1141 RAD2_RHSFRadarSensorDistance 126;
BA_ "GenSigStartValue" SG_ 1141 RAD2_LHSRRadarSensorDistance 126;
BA_ "GenSigStartValue" SG_ 1141 RAD2_RHSRRadarSensorDistance 126;
BA_ "SystemSignalLongSymbol" SG_ 1050 APA_AVM_3_Exterior_rearview_mirr "APA_AVM_3_Exterior_rearview_mirror_adjustment_Sts";
BA_ "GenSigSendType" SG_ 1507 DHM_1_Doorkonb_time_freeback 4;
BA_ "GenSigSendType" SG_ 1518 CEM_DHM_handlelockswitchfeedback 2;
BA_ "GenSigSendType" SG_ 1518 CEM_DHM_handleunlockswitchfeedba 2;
BA_ "SystemSignalLongSymbol" SG_ 1518 CEM_DHM_handleunlockswitchfeedba "CEM_DHM_handleunlockswitchfeedback";
BA_ "GenSigSendType" SG_ 1517 CEM_key_position_feedback 4;
BA_ "GenSigSendType" SG_ 1517 CEM_SRF_lockingreason 4;
BA_ "GenSigSendType" SG_ 1517 CEM_RR_window_up_Reason_feedback 4;
BA_ "GenSigSendType" SG_ 1517 CEM_LR_window_up_Reason_feedback 4;
BA_ "GenSigSendType" SG_ 1517 CEM_Passenger_window_up_Reason_f 4;
BA_ "SystemSignalLongSymbol" SG_ 1517 CEM_Passenger_window_up_Reason_f "CEM_Passenger_window_up_Reason_feedback";
BA_ "GenSigSendType" SG_ 1517 CEM_Driver_window_up_Reason_feed 4;
BA_ "SystemSignalLongSymbol" SG_ 1517 CEM_Driver_window_up_Reason_feed "CEM_Driver_window_up_Reason_feedback";
BA_ "GenSigSendType" SG_ 1504 CEM_SRFclosingConditions 4;
BA_ "GenSigSendType" SG_ 1504 CEM_Abat_VentCMDSts 4;
BA_ "GenSigSendType" SG_ 1504 CEM_PSRFCMDSts 4;
BA_ "SystemSignalLongSymbol" SG_ 1168 CEM_ALM_1_SceneMode_ControlSwitc "CEM_ALM_1_SceneMode_ControlSwitch";
BA_ "GenSigStartValue" SG_ 1168 CEM_ALM_1_STAT_WelcomeWaterLamp 1;
BA_ "SystemSignalLongSymbol" SG_ 1168 CEM_ALM_1_STAT_AssociatedWithDri "CEM_ALM_1_STAT_AssociatedWithDriverMode";
BA_ "GenSigStartValue" SG_ 1168 CEM_ALM_1_STAT_Apiluminance 7;
BA_ "GenSigStartValue" SG_ 1168 CEM_ALM_1_STAT_StaticEffect 7;
BA_ "GenSigStartValue" SG_ 1168 CEM_ALM_1_STAT_ControlSwitch 2;
BA_ "GenSigStartValue" SG_ 936 BCM_13_EBS_SOC 255;
BA_ "SystemSignalLongSymbol" SG_ 1492 CEM_DriverSeat_FrontendUD_Locato "CEM_DriverSeat_FrontendUD_Locaton";
BA_ "GenSigStartValue" SG_ 1492 CEM_Rmirror_UD_Locaton 1;
BA_ "GenSigStartValue" SG_ 1492 CEM_Rmirror_LR_Locaton 1;
BA_ "GenSigStartValue" SG_ 1492 CEM_Lmirror_UD_Locaton 1;
BA_ "GenSigStartValue" SG_ 1492 CEM_Lmirror_LR_Locaton 1;
BA_REL_ "GenSigTimeoutTime" BU_SG_REL_ IHU SG_ 1262 LightShowSts 4000;
BA_REL_ "GenSigTimeoutTime" BU_SG_REL_ IHU SG_ 295 YAS_1_LateraAccaleleration 400;
BA_REL_ "GenSigTimeoutTime" BU_SG_REL_ IHU SG_ 1111 AVAS_FunctionSts 2000;
BA_REL_ "GenSigTimeoutTime" BU_SG_REL_ IHU SG_ 1067 OBC_CC_ConnectSts 2000;
BA_REL_ "GenSigTimeoutTime" BU_SG_REL_ IHU SG_ 1057 LimitSpeedSts 2000;
BA_REL_ "GenSigTimeoutTime" BU_SG_REL_ IHU SG_ 1057 CruiseLimitSpeedValue 2000;
BA_REL_ "GenSigTimeoutTime" BU_SG_REL_ IHU SG_ 1046 HCU_3_G_SumElecCns 2000;
BA_REL_ "GenSigTimeoutTime" BU_SG_REL_ IHU SG_ 1046 HCU_3_G_SumFuCns 2000;
BA_REL_ "GenSigTimeoutTime" BU_SG_REL_ IHU SG_ 1142 HCU_4_G_SumEgyCns 2000;
BA_REL_ "GenSigTimeoutTime" BU_SG_REL_ IHU SG_ 1142 HCU_4_G_AvgEnergyCns 2000;
BA_REL_ "GenSigTimeoutTime" BU_SG_REL_ IHU SG_ 1142 HCU_4_G_AvgElecCns 2000;
BA_REL_ "GenSigTimeoutTime" BU_SG_REL_ IHU SG_ 1142 HCU_4_G_AvgFuCns 2000;
BA_REL_ "GenSigTimeoutTime" BU_SG_REL_ IHU SG_ 1142 FuelTankLidSts 2000;
BA_REL_ "GenSigTimeoutTime" BU_SG_REL_ IHU SG_ 1044 HCU_2_G_ChrgnFctMemSt 2000;
BA_REL_ "GenSigTimeoutTime" BU_SG_REL_ IHU SG_ 1044 HCU_RegenerateLevel 2000;
BA_REL_ "GenSigTimeoutTime" BU_SG_REL_ IHU SG_ 1044 HCU_SetSOCFed 2000;
BA_REL_ "GenSigTimeoutTime" BU_SG_REL_ IHU SG_ 1044 HCU_SocManageFed 2000;
BA_REL_ "GenSigTimeoutTime" BU_SG_REL_ IHU SG_ 1044 HCU_RangeAval 2000;
BA_REL_ "GenSigTimeoutTime" BU_SG_REL_ IHU SG_ 1044 HCU_EnergyFlow 2000;
BA_REL_ "GenSigTimeoutTime" BU_SG_REL_ IHU SG_ 1034 HCU_PTReady 2000;
BA_REL_ "GenSigTimeoutTime" BU_SG_REL_ IHU SG_ 1034 HCU_PowertrainFault 2000;
BA_REL_ "GenSigTimeoutTime" BU_SG_REL_ IHU SG_ 1034 HCU_PowerModeFed 2000;
BA_REL_ "GenSigTimeoutTime" BU_SG_REL_ IHU SG_ 1183 BMSH_PackChargingThermalSt 2000;
BA_REL_ "GenSigTimeoutTime" BU_SG_REL_ IHU SG_ 1183 BMSH_BattVolt 2000;
BA_REL_ "GenSigTimeoutTime" BU_SG_REL_ IHU SG_ 1183 BMSH_BatteryCurrent 2000;
BA_REL_ "GenSigTimeoutTime" BU_SG_REL_ IHU SG_ 1472 BMSH_SingleDisChargeEnergy 4000;
BA_REL_ "GenSigTimeoutTime" BU_SG_REL_ IHU SG_ 1472 BMSH_SingleChargeEnergy 4000;
BA_REL_ "GenSigTimeoutTime" BU_SG_REL_ IHU SG_ 1449 BMSH_CellVoltMin 4000;
BA_REL_ "GenSigTimeoutTime" BU_SG_REL_ IHU SG_ 1449 BMSH_CellVoltMax 4000;
BA_REL_ "GenSigTimeoutTime" BU_SG_REL_ IHU SG_ 1448 BMSH_TempSensor_MinTemp 4000;
BA_REL_ "GenSigTimeoutTime" BU_SG_REL_ IHU SG_ 1448 BMSH_TempSensor_MaxTemp 4000;
BA_REL_ "GenSigTimeoutTime" BU_SG_REL_ IHU SG_ 1436 BMSH_InsulationResis 4000;
BA_REL_ "GenSigTimeoutTime" BU_SG_REL_ IHU SG_ 1103 BMS_8_CC2Sts 2000;
BA_REL_ "GenSigTimeoutTime" BU_SG_REL_ IHU SG_ 1103 BMSH_SOH 2000;
BA_REL_ "GenSigTimeoutTime" BU_SG_REL_ IHU SG_ 1103 BMS_8_PackDCChargingSt 2000;
BA_REL_ "GenSigTimeoutTime" BU_SG_REL_ IHU SG_ 1103 BMSH_LeftChargeTime 2000;
BA_REL_ "GenSigTimeoutTime" BU_SG_REL_ IHU SG_ 1083 BMSH_PackPowerRealTime 2000;
BA_REL_ "GenSigTimeoutTime" BU_SG_REL_ IHU SG_ 1083 BMSH_PackRemainEnergy 2000;
BA_REL_ "GenSigTimeoutTime" BU_SG_REL_ IHU SG_ 1083 BMSH_SOCDisp 2000;
BA_REL_ "GenSigTimeoutTime" BU_SG_REL_ IHU SG_ 856 TBOX_TimeToStopChargeMinuteFed 1000;
BA_REL_ "GenSigTimeoutTime" BU_SG_REL_ IHU SG_ 856 TBOX_TimeToStopChargeHourFed 1000;
BA_REL_ "GenSigTimeoutTime" BU_SG_REL_ IHU SG_ 856 TBOX_TimeToStartChargeMinuteFed 1000;
BA_REL_ "GenSigTimeoutTime" BU_SG_REL_ IHU SG_ 856 TBOX_TimeToStartChargeHourFed 1000;
BA_REL_ "GenSigTimeoutTime" BU_SG_REL_ IHU SG_ 856 TBOX_ChargeModeSts 1000;
BA_REL_ "GenSigTimeoutTime" BU_SG_REL_ IHU SG_ 1314 TBOX_3_BatteryPowerLimit 4000;
BA_REL_ "GenSigTimeoutTime" BU_SG_REL_ IHU SG_ 1025 Welcome_OutsoundSts 4000;
BA_REL_ "GenSigTimeoutTime" BU_SG_REL_ IHU SG_ 1025 Person_RemindSts 4000;
BA_REL_ "GenSigTimeoutTime" BU_SG_REL_ IHU SG_ 1025 Welcome_Outsound_SwitchSts 4000;
BA_REL_ "GenSigTimeoutTime" BU_SG_REL_ IHU SG_ 803 L_GearSubSW 200;
BA_REL_ "GenSigTimeoutTime" BU_SG_REL_ IHU SG_ 803 PA_SW 200;
BA_REL_ "GenSigTimeoutTime" BU_SG_REL_ IHU SG_ 803 L_RESPlus_SW 200;
BA_REL_ "GenSigTimeoutTime" BU_SG_REL_ IHU SG_ 803 L_RIGHT_SW 200;
BA_REL_ "GenSigTimeoutTime" BU_SG_REL_ IHU SG_ 803 L_LEFT_SW 200;
BA_REL_ "GenSigTimeoutTime" BU_SG_REL_ IHU SG_ 803 L_DW_SW 200;
BA_REL_ "GenSigTimeoutTime" BU_SG_REL_ IHU SG_ 803 L_UP_SW 200;
BA_REL_ "GenSigTimeoutTime" BU_SG_REL_ IHU SG_ 1120 Enter_super_fast_charge 4000;
BA_REL_ "GenSigTimeoutTime" BU_SG_REL_ IHU SG_ 1120 WCM_Electricity_decimal 4000;
BA_REL_ "GenSigTimeoutTime" BU_SG_REL_ IHU SG_ 1120 WCM_Electricity_integer 4000;
BA_REL_ "GenSigTimeoutTime" BU_SG_REL_ IHU SG_ 1120 WCM_PhoneDetectionStatus 4000;
BA_REL_ "GenSigTimeoutTime" BU_SG_REL_ IHU SG_ 1120 WCM_WirelessChargingStatus 4000;
BA_REL_ "GenSigTimeoutTime" BU_SG_REL_ IHU SG_ 1120 WCM_WirelessChargingSetStatus 4000;
BA_REL_ "GenSigTimeoutTime" BU_SG_REL_ IHU SG_ 1338 PM2_5_ErrSts 4000;
BA_REL_ "GenSigTimeoutTime" BU_SG_REL_ IHU SG_ 1338 PM2_5_Sts 4000;
BA_REL_ "GenSigTimeoutTime" BU_SG_REL_ IHU SG_ 1338 PM2_5_AirIOutQLevel 4000;
BA_REL_ "GenSigTimeoutTime" BU_SG_REL_ IHU SG_ 1338 PM2_5_AirInQLevel 4000;
BA_REL_ "GenSigTimeoutTime" BU_SG_REL_ IHU SG_ 1338 PM2_5_Outdensity 4000;
BA_REL_ "GenSigTimeoutTime" BU_SG_REL_ IHU SG_ 1338 PM2_5_Indensity 4000;
BA_REL_ "GenSigTimeoutTime" BU_SG_REL_ IHU SG_ 787 ESP_3_AVHSts 400;
BA_REL_ "GenSigTimeoutTime" BU_SG_REL_ IHU SG_ 1136 YAS_2_LongitudinalAcceleration 400;
BA_REL_ "GenSigTimeoutTime" BU_SG_REL_ IHU SG_ 1141 RAD2_Radar_FunctionModel_Status 2000;
BA_REL_ "GenSigTimeoutTime" BU_SG_REL_ IHU SG_ 1141 RAD2_LHSFRadarSensorDistance 2000;
BA_REL_ "GenSigTimeoutTime" BU_SG_REL_ IHU SG_ 1141 RAD2_RHSFRadarSensorDistance 2000;
BA_REL_ "GenSigTimeoutTime" BU_SG_REL_ IHU SG_ 1141 RAD2_LHSRRadarSensorDistance 2000;
BA_REL_ "GenSigTimeoutTime" BU_SG_REL_ IHU SG_ 1141 RAD2_RHSRRadarSensorDistance 2000;
BA_REL_ "GenSigTimeoutTime" BU_SG_REL_ IHU SG_ 1050 APA_AVM_3_SystemSts_Body_1 2000;
BA_REL_ "GenSigTimeoutTime" BU_SG_REL_ IHU SG_ 1050 APA_Parking_Space_Search_Sts 2000;
BA_REL_ "GenSigTimeoutTime" BU_SG_REL_ IHU SG_ 1050 AVM_FactoryMode 2000;
BA_REL_ "GenSigTimeoutTime" BU_SG_REL_ IHU SG_ 1050 APA_3AVMFeedbackSts_RemoteMode 2000;
BA_REL_ "GenSigTimeoutTime" BU_SG_REL_ IHU SG_ 1050 APA_AVM_3_AVMDisplaySts 2000;
BA_REL_ "GenSigTimeoutTime" BU_SG_REL_ IHU SG_ 1288 APA_2_AVMStatusFault 4000;
BA_REL_ "GenSigTimeoutTime" BU_SG_REL_ IHU SG_ 1288 APA_2_AVMFaultStatusCameraRight 4000;
BA_REL_ "GenSigTimeoutTime" BU_SG_REL_ IHU SG_ 1288 APA_2_AVMFaultStatusCameraRear 4000;
BA_REL_ "GenSigTimeoutTime" BU_SG_REL_ IHU SG_ 1288 APA_2_AVMFaultStatusCameraLeft 4000;
BA_REL_ "GenSigTimeoutTime" BU_SG_REL_ IHU SG_ 1288 APA_2_AVMFaultStatusCameraFront 4000;
BA_REL_ "GenSigTimeoutTime" BU_SG_REL_ IHU SG_ 773 FRM_3_CRC 1000;
BA_REL_ "GenSigTimeoutTime" BU_SG_REL_ IHU SG_ 773 FRM_3_MessageCounter 1000;
BA_REL_ "GenSigTimeoutTime" BU_SG_REL_ IHU SG_ 773 FRM_3_AEB_ON_OFF_Sts 1000;
BA_REL_ "GenSigTimeoutTime" BU_SG_REL_ IHU SG_ 773 FRM_3_FCW_OPTION_Sts 1000;
BA_REL_ "GenSigTimeoutTime" BU_SG_REL_ IHU SG_ 773 FRM_3_FCW_ON_OFF_Sts 1000;
BA_REL_ "GenSigTimeoutTime" BU_SG_REL_ IHU SG_ 773 FRM_3_FCW_PreWarning 1000;
BA_REL_ "GenSigTimeoutTime" BU_SG_REL_ IHU SG_ 773 FRM_3_DistanceWarning 1000;
BA_REL_ "GenSigTimeoutTime" BU_SG_REL_ IHU SG_ 773 FRM_3_AEBMode 1000;
BA_REL_ "GenSigTimeoutTime" BU_SG_REL_ IHU SG_ 773 FRM_3_FCWMode 1000;
BA_REL_ "GenSigTimeoutTime" BU_SG_REL_ IHU SG_ 773 FRM_3_Obiect_Dx 1000;
BA_REL_ "GenSigTimeoutTime" BU_SG_REL_ IHU SG_ 773 FRM_3_ACCMode 1000;
BA_REL_ "GenSigTimeoutTime" BU_SG_REL_ IHU SG_ 773 FRM_3_TimeGapSet_ICM 1000;
BA_REL_ "GenSigTimeoutTime" BU_SG_REL_ IHU SG_ 773 FRM_3_TakeOverReq 1000;
BA_REL_ "GenSigTimeoutTime" BU_SG_REL_ IHU SG_ 773 FRM_3_Textinfo 1000;
BA_REL_ "GenSigTimeoutTime" BU_SG_REL_ IHU SG_ 773 FRM_3_FrontObject_Type 1000;
BA_REL_ "GenSigTimeoutTime" BU_SG_REL_ IHU SG_ 773 FRM_3_ObjValid 1000;
BA_REL_ "GenSigTimeoutTime" BU_SG_REL_ IHU SG_ 773 FRM_3_DxTarObj 1000;
BA_REL_ "GenSigTimeoutTime" BU_SG_REL_ IHU SG_ 773 FRM_3_VSetDis 1000;
BA_REL_ "GenSigTimeoutTime" BU_SG_REL_ IHU SG_ 1241 FuelTankLidSystemFailureSts 2000;
BA_REL_ "GenSigTimeoutTime" BU_SG_REL_ IHU SG_ 1241 FuelTankPressureConditionReached 2000;
BA_REL_ "GenSigTimeoutTime" BU_SG_REL_ IHU SG_ 632 EMS_4_IntakeAirPressure 1000;
BA_REL_ "GenSigTimeoutTime" BU_SG_REL_ IHU SG_ 632 EMS_4_EngineSts 1000;
BA_REL_ "GenSigTimeoutTime" BU_SG_REL_ IHU SG_ 1202 GSM_STAT_ShifterLeverFault 400;
BA_REL_ "GenSigTimeoutTime" BU_SG_REL_ IHU SG_ 1202 GSM_ALIVE_GSM_1 400;
BA_REL_ "GenSigTimeoutTime" BU_SG_REL_ IHU SG_ 1202 GSM_STAT_ParkButton 400;
BA_REL_ "GenSigTimeoutTime" BU_SG_REL_ IHU SG_ 1202 GSM_GearShiftPosInverse 400;
BA_REL_ "GenSigTimeoutTime" BU_SG_REL_ IHU SG_ 1202 GSM_CHKSM_GSM_1 400;
BA_REL_ "GenSigTimeoutTime" BU_SG_REL_ IHU SG_ 1202 ACC_Cruise_Control 400;
BA_REL_ "GenSigTimeoutTime" BU_SG_REL_ IHU SG_ 1202 GSM_GearShiftPos 400;
BA_REL_ "GenSigTimeoutTime" BU_SG_REL_ IHU SG_ 1507 DHM_1_Doorkonb_time_freeback 4000;
BA_REL_ "GenSigTimeoutTime" BU_SG_REL_ IHU SG_ 1517 CEM_SRF_lockingreason 4000;
BA_REL_ "GenSigTimeoutTime" BU_SG_REL_ IHU SG_ 1517 CEM_RR_window_up_Reason_feedback 4000;
BA_REL_ "GenSigTimeoutTime" BU_SG_REL_ IHU SG_ 1517 CEM_LR_window_up_Reason_feedback 4000;
BA_REL_ "GenSigTimeoutTime" BU_SG_REL_ IHU SG_ 1517 CEM_Passenger_window_up_Reason_f 4000;
BA_REL_ "GenSigTimeoutTime" BU_SG_REL_ IHU SG_ 1517 CEM_Driver_window_up_Reason_feed 4000;
BA_REL_ "GenSigTimeoutTime" BU_SG_REL_ IHU SG_ 1504 CEM_SRFclosingConditions 4000;
BA_REL_ "GenSigTimeoutTime" BU_SG_REL_ IHU SG_ 1504 CEM_Abat_VentCMDSts 4000;
BA_REL_ "GenSigTimeoutTime" BU_SG_REL_ IHU SG_ 1504 CEM_PSRFCMDSts 4000;
BA_REL_ "GenSigTimeoutTime" BU_SG_REL_ IHU SG_ 1168 CEM_ALM_1_SceneMode_ControlSwitc 2000;
BA_REL_ "GenSigTimeoutTime" BU_SG_REL_ IHU SG_ 1168 CEM_ALM_1_DeletePeronalSet_FB 2000;
BA_REL_ "GenSigTimeoutTime" BU_SG_REL_ IHU SG_ 1168 CEM_ALM_1_PersonalBeamEn 2000;
BA_REL_ "GenSigTimeoutTime" BU_SG_REL_ IHU SG_ 1168 CEM_ALM_1_PersonalSeatEn 2000;
BA_REL_ "GenSigTimeoutTime" BU_SG_REL_ IHU SG_ 1168 CEM_ALM_1_Seat_Set_Status 2000;
BA_REL_ "GenSigTimeoutTime" BU_SG_REL_ IHU SG_ 1168 CEM_ALM_1_Seat_Set_Pop_Up 2000;
BA_REL_ "GenSigTimeoutTime" BU_SG_REL_ IHU SG_ 1168 CEM_ALM_1_Wash_Car_Status 2000;
BA_REL_ "GenSigTimeoutTime" BU_SG_REL_ IHU SG_ 1168 CEM_ALM_1_PersonalSetSts 2000;
BA_REL_ "GenSigTimeoutTime" BU_SG_REL_ IHU SG_ 1168 CEM_ALM_1_STAT_WelcomeWaterLamp 2000;
BA_REL_ "GenSigTimeoutTime" BU_SG_REL_ IHU SG_ 1168 CEM_ALM_1_STAT_AssociatedWithDri 2000;
BA_REL_ "GenSigTimeoutTime" BU_SG_REL_ IHU SG_ 1168 CEM_ALM_1_STAT_Music 2000;
BA_REL_ "GenSigTimeoutTime" BU_SG_REL_ IHU SG_ 1168 CEM_ALM_1_STAT_Apiluminance 2000;
BA_REL_ "GenSigTimeoutTime" BU_SG_REL_ IHU SG_ 1168 CEM_ALM_1_STAT_Static_Colour 2000;
BA_REL_ "GenSigTimeoutTime" BU_SG_REL_ IHU SG_ 1168 CEM_ALM_1_STAT_StaticEffect 2000;
BA_REL_ "GenSigTimeoutTime" BU_SG_REL_ IHU SG_ 1168 CEM_ALM_1_STAT_ControlSwitch 2000;
BA_REL_ "GenSigTimeoutTime" BU_SG_REL_ IHU SG_ 1168 CEM_ALM_1_STAT_DMSMonitoring 2000;
BA_REL_ "GenSigTimeoutTime" BU_SG_REL_ IHU SG_ 1168 CEM_ALM_1_STAT_PM2_5Monitoring 2000;
BA_REL_ "GenSigTimeoutTime" BU_SG_REL_ IHU SG_ 1168 CEM_ALM_1_STAT_DriveApiluminance 2000;
BA_REL_ "GenSigTimeoutTime" BU_SG_REL_ IHU SG_ 1168 CEM_ALM_1_STAT_64Colour 2000;
BA_REL_ "GenSigTimeoutTime" BU_SG_REL_ IHU SG_ 936 BCM_13_EBS_SOC 2000;
BA_REL_ "GenSigTimeoutTime" BU_SG_REL_ IHU SG_ 1492 CEM_DriverLumbart_UD_Locaton 2000;
BA_REL_ "GenSigTimeoutTime" BU_SG_REL_ IHU SG_ 1492 CEM_PassengerSeat_LegUD_Locaton 2000;
BA_REL_ "GenSigTimeoutTime" BU_SG_REL_ IHU SG_ 1492 CEM_PassengerSeat_FR_Locaton 2000;
BA_REL_ "GenSigTimeoutTime" BU_SG_REL_ IHU SG_ 1492 CEM_PassengerSeat_BackFR_Locaton 2000;
BA_REL_ "GenSigTimeoutTime" BU_SG_REL_ IHU SG_ 1492 CEM_DriverSeat_RearendUD_Locaton 2000;
BA_REL_ "GenSigTimeoutTime" BU_SG_REL_ IHU SG_ 1492 CEM_DriverSeat_FrontendUD_Locato 2000;
BA_REL_ "GenSigTimeoutTime" BU_SG_REL_ IHU SG_ 1492 CEM_DriverSeat_FR_Locaton 2000;
BA_REL_ "GenSigTimeoutTime" BU_SG_REL_ IHU SG_ 1492 CEM_DriverSeat_BackFR_Locaton 2000;
BA_REL_ "GenSigTimeoutTime" BU_SG_REL_ IHU SG_ 1492 CEM_Rmirror_UD_Locaton 2000;
BA_REL_ "GenSigTimeoutTime" BU_SG_REL_ IHU SG_ 1492 CEM_Rmirror_LR_Locaton 2000;
BA_REL_ "GenSigTimeoutTime" BU_SG_REL_ IHU SG_ 1492 CEM_Lmirror_UD_Locaton 2000;
BA_REL_ "GenSigTimeoutTime" BU_SG_REL_ IHU SG_ 1492 CEM_Lmirror_LR_Locaton 2000;
BA_REL_ "GenSigTimeoutTime" BU_SG_REL_ IHU SG_ 1476 CEM_massagemodeSts 4000;
BA_REL_ "GenSigTimeoutTime" BU_SG_REL_ IHU SG_ 1476 CEM_passageVibrationSts 4000;
BA_REL_ "GenSigTimeoutTime" BU_SG_REL_ IHU SG_ 1476 CEM_Passenger_massageSts 4000;
BA_REL_ "GenSigTimeoutTime" BU_SG_REL_ IHU SG_ 1476 CEM_DriverLumbart_FR_Locaton 4000;
BA_REL_ "GenSigTimeoutTime" BU_SG_REL_ IHU SG_ 1476 CEM_Mirror_Driverseat_Location 4000;
BA_REL_ "GenSigTimeoutTime" BU_SG_REL_ IHU SG_ 1476 CEM_UnderVoltageSts 4000;
BA_REL_ "GenSigTimeoutTime" BU_SG_REL_ IHU SG_ 1476 CEM_RearWiper_SwitchSts 4000;
BA_REL_ "GenSigTimeoutTime" BU_SG_REL_ IHU SG_ 1476 CEM_Wiper_MaintenanceSts 4000;
BA_REL_ "GenSigTimeoutTime" BU_SG_REL_ IHU SG_ 1476 CEM_Mirror_Fold_SwitchSts 4000;
BA_REL_ "GenSigTimeoutTime" BU_SG_REL_ IHU SG_ 1476 CEM_IPM__FRSeatHeatVentSwSts 4000;
BA_REL_ "GenSigTimeoutTime" BU_SG_REL_ IHU SG_ 1476 CEM_IPM_FLSeatHeatVentSwSts 4000;
BA_REL_ "GenSigTimeoutTime" BU_SG_REL_ IHU SG_ 1476 CEM_DriverLumbart_UDSts 4000;
BA_REL_ "GenSigTimeoutTime" BU_SG_REL_ IHU SG_ 1476 CEM_DriverLumbart_FRSts 4000;
BA_REL_ "GenSigTimeoutTime" BU_SG_REL_ IHU SG_ 1476 CEM_DriverSeat_RearendUDSts 4000;
BA_REL_ "GenSigTimeoutTime" BU_SG_REL_ IHU SG_ 1476 CEM_DriverSeat_FrontendUDSts 4000;
BA_REL_ "GenSigTimeoutTime" BU_SG_REL_ IHU SG_ 1476 CEM_DriverSeat_FRSts 4000;
BA_REL_ "GenSigTimeoutTime" BU_SG_REL_ IHU SG_ 1476 CEM_DriverSeat_BackFRSts 4000;
BA_REL_ "GenSigTimeoutTime" BU_SG_REL_ IHU SG_ 1476 CEM_MirrorFlip_CFGSts 4000;
BA_REL_ "GenSigTimeoutTime" BU_SG_REL_ IHU SG_ 1476 CEM_RightMirrorCtrlSts 4000;
BA_REL_ "GenSigTimeoutTime" BU_SG_REL_ IHU SG_ 1476 CEM_LeftMirrorCtrlSts 4000;
BA_REL_ "GenSigTimeoutTime" BU_SG_REL_ IHU SG_ 1476 CEM_RHRdoor_buttonsts 4000;
BA_REL_ "GenSigTimeoutTime" BU_SG_REL_ IHU SG_ 1476 CEM_LHRdoor_buttonsts 4000;
BA_REL_ "GenSigTimeoutTime" BU_SG_REL_ IHU SG_ 1476 CEM_PsngrDoor_buttonsts 4000;
BA_REL_ "GenSigTimeoutTime" BU_SG_REL_ IHU SG_ 1476 CEM_Smart_HighBeamSts 4000;
BA_REL_ "GenSigTimeoutTime" BU_SG_REL_ IHU SG_ 1476 CEM_HighBeam_AdjustSts 4000;
VAL_ 3221225472 CEM_IPM_FRSeatHeatVentSwSts 7 "Level_3_Ventilation_Request(7)" 6 "Level_2_Ventilation_Request(6)" 5 "Level_1_Ventilation_Request(5)" 4 "Level_3_Heat_Request(4)" 3 "Level_2_Heat_Request(3)" 2 "Level_1_Heat_Request(2)" 1 "OFF(1)" 0 "NO_Request(0)" ;
VAL_ 3221225472 CEM_IPM_FLSeatHeatVentSwSts 7 "Level_3_Ventilation_Request(7)" 6 "Level_2_Ventilation_Request(6)" 5 "Level_1_Ventilation_Request(5)" 4 "Level_3_Heat_Request(4)" 3 "Level_2_Heat_Request(3)" 2 "Level_1_Heat_Request(2)" 1 "OFF(1)" 0 "NO_Request(0)" ;
VAL_ 3221225472 IHU_StopChargeSW 1 "Press(1)" 0 "Startup_Default(0)" ;
VAL_ 804 R_MUTE_SW 3 "invalid(3)" 2 "Stuck(2)" 1 "Pressed(1)" 0 "Notaction(0)" ;
VAL_ 804 R_RIGHT_SW 3 "invalid(3)" 2 "Stuck(2)" 1 "Pressed(1)" 0 "Notaction(0)" ;
VAL_ 804 R_LEFT_SW 3 "invalid(3)" 2 "Stuck(2)" 1 "Pressed(1)" 0 "Notaction(0)" ;
VAL_ 804 R_DW_SW 3 "error(3)" 2 "Fake button(2)" 1 "Scroll Once(1)" 0 "Button not pressed(0)" ;
VAL_ 804 R_UP_SW 3 "error(3)" 2 "Fake button(2)" 1 "Scroll Once(1)" 0 "Button not pressed(0)" ;
VAL_ 1262 LightShowSts 31 "Reserved" 30 "Reserved" 29 "Reserved" 28 "Reserved" 27 "Reserved" 26 "Reserved" 25 "Reserved" 24 "Reserved" 23 "Reserved" 22 "Reserved" 21 "Reserved" 20 "Reserved" 19 "Reserved" 18 "Reserved" 17 "Reserved" 16 "Reserved" 15 "Reserved" 14 "Reserved" 13 "Reserved" 12 "Reserved" 11 "Reserved" 10 "Reserved" 9 "Reserved" 8 "Reserved" 7 "Reserved" 6 "Reserved" 5 "Reserved" 4 "Reserved" 3 "Reserved" 2 "Light show Animation Close" 1 "Light show Animation Open" 0 "No_Request" ;
VAL_ 1322 SET_FrontWindscreenHeatiReq 3 "Reserved" 2 "Active" 1 "NotActive" 0 "Invalid" ;
VAL_ 1322 SET_RRSeatHeatVentSwReq 7 "Reserved" 6 "Reserved" 5 "Reserved" 4 "Level_3_Heat_Request" 3 "Level_2_Heat_Request" 2 "Level_1_Heat_Request" 1 "OFF" 0 "NoActive" ;
VAL_ 1322 SET_LRSeatHeatVentSwReq 7 "Reserved" 6 "Reserved" 5 "Reserved" 4 "Level_3_Heat_Request" 3 "Level_2_Heat_Request" 2 "Level_1_Heat_Request" 1 "OFF" 0 "NoActive" ;
VAL_ 1111 AVAS_FunctionSts 1 " OFF(1)" 0 " ON(0)" ;
VAL_ 1057 LimitSpeedSts 5 "Kickdown(5)" 4 "Cancel(4)" 3 "Limit(3)" 2 "Overspeed(2)" 1 "Standby(1)" 0 "Off(0)" ;
VAL_ 1142 FuelTankLidSts 1 "Open(1)" 0 "Close(0)" ;
VAL_ 1044 HCU_2_G_ChrgnFctMemSt 3 " Reserved(3)" 2 " No Remember(2)" 1 " Remember (1)" 0 " Not Active(0)" ;
VAL_ 1044 HCU_RegenerateLevel 3 " Reserved(3)" 2 " low level(2)" 1 " middle level (1)" 0 " high level(0)" ;
VAL_ 1044 HCU_SetSOCFed 7 "Reserved(7)" 6 "Reserved(6)" 5 "72%(5)" 4 "64%(4)" 3 "56%(3)" 2 "48%(2)" 1 "40%(1)" 0 "30%(0)" ;
VAL_ 1044 HCU_SocManageFed 7 " Reserved(7)" 6 " Reserved(6)" 5 " Reserved(5)" 4 " Reserved(4)" 3 "Charge(3)" 2 " Auto(2)" 1 " SAVE (1)" 0 " Default(0)" ;
VAL_ 1044 HCU_EnergyFlow 31 "Reserved(31)" 30 "Reserved(30)" 29 "Reserved(29)" 28 "Reserved(28)" 27 "Reserved(27)" 26 "Reserved(26)" 25 "Reserved(25)" 24 "Reserved(24)" 23 "Reserved(23)" 22 "Reserved(22)" 21 "Reserved(21)" 20 "Reserved(20)" 19 "Reserved(19)" 18 "Reserved(18)" 17 "Reserved(17)" 16 "Reserved(16)" 15 "Charge(15)" 14 "4WD_ReGenerateBrake(14)" 13 "2WD_ReGenerateBrake(13)" 12 "Parking_Generate(12)" 11 "Running_Generate(11)" 10 "Engine(10)" 9 "4WD_Parallel(9)" 8 "2WD_Parallel(8)" 7 "4WD_ExtendRangeCharge(7)" 6 "4WD_ExtendRangeDisCharge(6)" 5 "2WD_ExtendRangeCharge(5)" 4 "2WD_ExtendRangeDisCharge(4)" 3 "4WD_EV(3)" 2 "2WD_EV(2)" 1 "Ready(1)" 0 "OFF(0)" ;
VAL_ 1034 HCU_PTReady 1 "LmpON" 0 "LmpOFF" ;
VAL_ 1034 HCU_PowertrainFault 1 " Fault(1)" 0 " No Fault(0)" ;
VAL_ 1034 HCU_PowerModeFed 3 " Reserved(3)" 2 " HEV                                     (2)" 1 " EV (1)" 0 " Not Active                                   (0)" ;
VAL_ 1183 BMSH_PackChargingThermalSt 0 "None" 7 " cooling(Reserved)(7)" 6 " Balance temperature(Reserved)(6)" 5 "ThermalError(5)" 4 "ChargeFinish(4)" 3 "Charging(3)" 2 "CoolingAndCharging(2)" 1 "Heating(1)" ;
VAL_ 1103 BMS_8_CC2Sts 1 "Connecyed" 0 "No Connect" ;
VAL_ 1103 BMS_8_PackDCChargingSt 15 "Reserved(15)" 14 "Reserved(14)" 13 "Reserved(13)" 12 "Reserved(12)" 11 "Reserved(11)" 10 "Reserved(10)" 9 "Fault(9)" 8 "CoolingAndCharging(8)" 7 " Cooling(7)" 6 " Balance temperature(6)" 5 " ThermalError (5)" 4 " ChargeFinish(4)" 3 " Charging(3)" 2 " HeatingAndCharging(2)" 1 " Heating(1)" 0 " None(0)" ;
VAL_ 2047 Start_Aging 1 "ON(1)" 0 "OFF(0)" ;
VAL_ 856 TBOX_TimeToStopChargeHourFed 31 "Invalid" 30 "Inactive" 29 "Reserved(29)" 28 "Reserved(28)" 27 "Reserved(27)" 26 "Reserved(26)" 25 "Reserved(25)" 24 "Reserved" 23 "23" 22 "22" 21 "21" 20 "20" 19 "19" 18 "18" 17 "17" 16 "16" 15 "15" 14 "14" 13 "13" 12 "12" 11 "11" 10 "10" 9 "9" 8 "8" 7 "7" 6 "6" 5 "5" 4 "4" 3 "3" 2 "2" 1 "1" 0 "0" ;
VAL_ 856 TBOX_TimeToStartChargeMinuteFed 63 "Invalid" 62 "Inactive" 61 " Reserved(61)" 60 "Reserved" 59 "59" 58 "58" 57 "57" 56 "56" 55 "55" 54 "54" 53 "53" 52 "52" 51 "51" 50 "50" 49 "49" 48 "48" 47 "47" 46 "46" 45 "45" 44 "44" 43 "43" 42 "42" 41 "41" 40 "40" 39 "39" 38 "38" 37 "37" 36 "36" 35 "35" 34 "34" 33 "33" 32 "32" 31 "31" 30 "30" 29 "29" 28 "28" 27 "27" 26 "26" 25 "25" 24 "24" 23 "23" 22 "22" 21 "21" 20 "20" 19 "19" 18 "18" 17 "17" 16 "16" 15 "15" 14 "14" 13 "13" 12 "12" 11 "11" 10 "10" 9 "9" 8 "8" 7 "7" 6 "6" 5 "5" 4 "4" 3 "3" 2 "2" 1 "1" 0 "0" ;
VAL_ 856 TBOX_TimeToStartChargeHourFed 31 "Invalid" 30 "Inactive" 29 " Reserved(29)" 28 " Reserved(28)" 27 " Reserved(27)" 26 " Reserved(26)" 25 " Reserved(25)" 24 "Reserved" 23 "23" 22 "22" 21 "21" 20 "20" 19 "19" 18 "18" 17 "17" 16 "16" 15 "15" 14 "14" 13 "13" 12 "12" 11 "11" 10 "10" 9 "9" 8 "8" 7 "7" 6 "6" 5 "5" 4 "4" 3 "3" 2 "2" 1 "1" 0 "0" ;
VAL_ 856 TBOX_ChargeModeSts 3 "Cycel Reservation Charge(3)" 2 "Singel Reservation Charge(2)" 1 "Immediate_Charge(1)" 0 "No_Charge(0)" ;
VAL_ 1314 TBOX_3_BatteryPowerLimit 2 "Level_2_BatteryPowerLimit(2)" 1 "Level_1_BatteryPowerLimit(1)" 0 "Startup(0)" ;
VAL_ 1025 Welcome_OutsoundSts 3 "Music_4(3)" 2 "Music_3(2)" 1 "Music_2 (1)" 0 "Music_1(0)" ;
VAL_ 1025 Person_RemindSts 1 "Active(1)" 0 "Not_Active(0)" ;
VAL_ 1025 Welcome_Outsound_SwitchSts 1 "Active(1)" 0 "Not_Active(0)" ;
VAL_ 803 L_RIGHT_SW 3 "invalid(3)" 2 "Stuck(2)" 1 "Pressed(1)" 0 "Notaction(0)" ;
VAL_ 803 L_LEFT_SW 3 "invalid(3)" 2 "Stuck(2)" 1 "Pressed(1)" 0 "Notaction(0)" ;
VAL_ 803 L_DW_SW 3 "error(3)" 2 "Fake button(2)" 1 "Scroll Once(1)" 0 "Button not pressed(0)" ;
VAL_ 803 L_UP_SW 3 "error(3)" 2 "Fake button(2)" 1 "Scroll Once(1)" 0 "Button not pressed(0)" ;
VAL_ 1120 Enter_super_fast_charge 255 "Reserved(255)" 254 "Reserved(254)" 253 "Reserved(253)" 252 "Reserved(252)" 251 "Reserved(251)" 250 "Reserved(250)" 249 "Reserved(249)" 248 "Reserved(248)" 247 "Reserved(247)" 246 "Reserved(246)" 245 "Reserved(245)" 244 "Reserved(244)" 243 "Reserved(243)" 242 "Reserved(242)" 241 "Reserved(241)" 240 "Reserved(240)" 239 "Reserved(239)" 238 "Reserved(238)" 237 "Reserved(237)" 236 "Reserved(236)" 235 "Reserved(235)" 234 "Reserved(234)" 233 "Reserved(233)" 232 "Reserved(232)" 231 "Reserved(231)" 230 "Reserved(230)" 229 "Reserved(229)" 228 "Reserved(228)" 227 "Reserved(227)" 226 "Reserved(226)" 225 "Reserved(225)" 224 "Reserved(224)" 223 "Reserved(223)" 222 "Reserved(222)" 221 "Reserved(221)" 220 "Reserved(220)" 219 "Reserved(219)" 218 "Reserved(218)" 217 "Reserved(217)" 216 "Reserved(216)" 215 "Reserved(215)" 214 "Reserved(214)" 213 "Reserved(213)" 212 "Reserved(212)" 211 "Reserved(211)" 210 "Reserved(210)" 209 "Reserved(209)" 208 "Reserved(208)" 207 "Reserved(207)" 206 "Reserved(206)" 205 "Reserved(205)" 204 "Reserved(204)" 203 "Reserved(203)" 202 "Reserved(202)" 201 "Reserved(201)" 200 "Reserved(200)" 199 "Reserved(199)" 198 "Reserved(198)" 197 "Reserved(197)" 196 "Reserved(196)" 195 "Reserved(195)" 194 "Reserved(194)" 193 "Reserved(193)" 192 "Reserved(192)" 191 "Reserved(191)" 190 "Reserved(190)" 189 "Reserved(189)" 188 "Reserved(188)" 187 "Reserved(187)" 186 "Reserved(186)" 185 "Reserved(185)" 184 "Reserved(184)" 183 "Reserved(183)" 182 "Reserved(182)" 181 "Reserved(181)" 180 "Reserved(180)" 179 "Reserved(179)" 178 "Reserved(178)" 177 "Reserved(177)" 176 "Reserved(176)" 175 "Reserved(175)" 174 "Reserved(174)" 173 "Reserved(173)" 172 "Reserved(172)" 171 "Reserved(171)" 170 "Reserved(170)" 169 "Reserved(169)" 168 "Reserved(168)" 167 "Reserved(167)" 166 "Reserved(166)" 165 "Reserved(165)" 164 "Reserved(164)" 163 "Reserved(163)" 162 "Reserved(162)" 161 "Reserved(161)" 160 "Reserved(160)" 159 "Reserved(159)" 158 "Reserved(158)" 157 "Reserved(157)" 156 "Reserved(156)" 155 "Reserved(155)" 154 "Reserved(154)" 153 "Reserved(153)" 152 "Reserved(152)" 151 "Reserved(151)" 150 "Reserved(150)" 149 "Reserved(149)" 148 "Reserved(148)" 147 "Reserved(147)" 146 "Reserved(146)" 145 "Reserved(145)" 144 "Reserved(144)" 143 "Reserved(143)" 142 "Reserved(142)" 141 "Reserved(141)" 140 "Reserved(140)" 139 "Reserved(139)" 138 "Reserved(138)" 137 "Reserved(137)" 136 "Reserved(136)" 135 "Reserved(135)" 134 "Reserved(134)" 133 "Reserved(133)" 132 "Reserved(132)" 131 "Reserved(131)" 130 "Reserved(130)" 129 "Reserved(129)" 128 "Reserved(128)" 127 "Reserved(127)" 126 "Reserved(126)" 125 "Reserved(125)" 124 "Reserved(124)" 123 "Reserved(123)" 122 "Reserved(122)" 121 "Reserved(121)" 120 "Reserved(120)" 119 "Reserved(119)" 118 "Reserved(118)" 117 "Reserved(117)" 116 "Reserved(116)" 115 "Reserved(115)" 114 "Reserved(114)" 113 "Reserved(113)" 112 "Reserved(112)" 111 "Reserved(111)" 110 "Reserved(110)" 109 "Reserved(109)" 108 "Reserved(108)" 107 "Reserved(107)" 106 "Reserved(106)" 105 "Reserved(105)" 104 "Reserved(104)" 103 "Reserved(103)" 102 "Reserved(102)" 101 "Reserved(101)" 100 "Reserved(100)" 99 "Reserved(99)" 98 "Reserved(98)" 97 "Reserved(97)" 96 "Reserved(96)" 95 "Reserved(95)" 94 "Reserved(94)" 93 "Reserved(93)" 92 "Reserved(92)" 91 "Reserved(91)" 90 "Reserved(90)" 89 "Reserved(89)" 88 "Reserved(88)" 87 "Reserved(87)" 86 "Reserved(86)" 85 "Reserved(85)" 84 "Reserved(84)" 83 "Reserved(83)" 82 "Reserved(82)" 81 "Reserved(81)" 80 "Reserved(80)" 79 "Reserved(79)" 78 "Reserved(78)" 77 "Reserved(77)" 76 "Reserved(76)" 75 "Reserved(75)" 74 "Reserved(74)" 73 "Reserved(73)" 72 "Reserved(72)" 71 "Reserved(71)" 70 "Reserved(70)" 69 "Reserved(69)" 68 "Reserved(68)" 67 "Reserved(67)" 66 "Reserved(66)" 65 "Reserved(65)" 64 "Reserved(64)" 63 "Reserved(63)" 62 "Reserved(62)" 61 "Reserved(61)" 60 "Reserved(60)" 59 "Reserved(59)" 58 "Reserved(58)" 57 "Reserved(57)" 56 "Reserved(56)" 55 "Reserved(55)" 54 "Reserved(54)" 53 "Reserved(53)" 52 "Reserved(52)" 51 "Reserved(51)" 50 "Reserved(50)" 49 "Reserved(49)" 48 "Reserved(48)" 47 "Reserved(47)" 46 "Reserved(46)" 45 "Reserved(45)" 44 "Reserved(44)" 43 "Reserved(43)" 42 "Reserved(42)" 41 "Reserved(41)" 40 "Reserved(40)" 39 "Reserved(39)" 38 "Reserved(38)" 37 "Reserved(37)" 36 "Reserved(36)" 35 "Reserved(35)" 34 "Reserved(34)" 33 "Reserved(33)" 32 "Reserved(32)" 31 "Reserved(31)" 30 "Reserved(30)" 29 "Reserved(29)" 28 "Reserved(28)" 27 "Reserved(27)" 26 "Reserved(26)" 25 "Reserved(25)" 24 "Reserved(24)" 23 "Reserved(23)" 22 "Reserved(22)" 21 "Reserved(21)" 20 "Reserved(20)" 19 "Reserved(19)" 18 "Reserved(18)" 17 "Reserved(17)" 16 "Reserved(16)" 15 "Reserved(15)" 14 "Reserved(14)" 13 "Reserved(13)" 12 "Reserved(12)" 11 "Reserved(11)" 10 "Reserved(10)" 9 "Reserved(9)" 8 "Reserved(8)" 7 "Reserved(7)" 6 "Reserved(6)" 5 "Reserved(5)" 4 "Reserved(4)" 3 "Enter OPPO super fast charge(3)" 2 "Enter MI super fast charge(2)" 1 "Enter HUAWEI super fast charge(1)" 0 "Not entering super fast charge(0)" ;
VAL_ 1120 WCM_Electricity_decimal 99 " .99%(99)" 1 " .01%(1)" 0 " .00%(0)" ;
VAL_ 1120 WCM_Electricity_integer 100 "100%(100)" 99 "99%(99)" 1 "1%(1)" 0 "0%(0)" ;
VAL_ 1120 WCM_PhoneDetectionStatus 1 "Phone forget reminder(1)" 0 "Default Value(0)" ;
VAL_ 1120 WCM_WirelessChargingStatus 15 "Reserved(15)" 14 "Reserved(14)" 13 "Reserved(13)" 12 "Reserved(12)" 11 "Reserved(11)" 10 "Reserved(10)" 9 "PEPS Stop Charging(9)" 8 "Other Faults(8)" 7 "Finished Charging(7)" 6 "Over temperature protection(6)" 5 "FOD(5)" 4 "Input Undervoltage protection(4)" 3 "Input Overvoltage protection(3)" 2 "Charging(2)" 1 "Standby(1)" ;
VAL_ 1120 WCM_WirelessChargingSetStatus 1 "Open(1)" 0 "Closed(0)" ;
VAL_ 1338 PM2_5_ErrSts 3 "Reserved(3)" 2 "Reserved(2)" 1 "Error(1)" 0 "No_Error(0)" ;
VAL_ 1338 PM2_5_Sts 1 "Active(1)" 0 "Standby(0)" ;
VAL_ 1338 PM2_5_AirIOutQLevel 5 "Level_6_PM25<999_And_PM25≥250(5)" 3 "Level_4_PM25<150_And_PM25≥115(3)" 2 "Level_3_PM25<115_And_PM25≥75(2)" 1 "Level_2_PM25<75_And_PM25≥35(1)" 0 "Level_1_PM25<35(0)" ;
VAL_ 1338 PM2_5_AirInQLevel 5 "Level_6_PM25<999_And_PM25≥250(5)" 3 "Level_4_PM25<150_And_PM25≥115(3)" 2 "Level_3_PM25<115_And_PM25≥75(2)" 1 "Level_2_PM25<75_And_PM25≥35(1)" 0 "Level_1_PM25<35(0)" ;
VAL_ 787 ESP_3_AVHSts 3 "Not_Used(3)" 2 "Active(2)" 1 "Standby(1)" 0 "Off(0)" ;
VAL_ 1141 RAD2_Radar_FunctionModel_Status 7 "Reserved(7)" 6 "Reserved(6)" 5 "Reserved(5)" 4 "Reserved(4)" 3 "Radar Block(3)" 2 "Radar Failure(2)" 1 "Radar Normal (1)" 0 "Default(0)" ;
VAL_ 1050 APA_AVM_3_SystemSts_Body_1 7 "Invalid(7)" 6 "Terminated(6)" 5 "Failure(5)" 4 "Completed(4)" 3 "Guidance_active(3)" 2 "Searching(2)" 1 "Standby(1)" 0 "off(0)" ;
VAL_ 1050 APA_Parking_Space_Search_Sts 1 "Parking_Space_Detected(1)" 0 "No_Parking_Space(0)" ;
VAL_ 1050 AVM_FactoryMode 1 "Factory_Mode(1)" 0 "Normal_Mode(0)" ;
VAL_ 1050 APA_3AVMFeedbackSts_RemoteMode 1 "On(1)" 0 "Off(0)" ;
VAL_ 1050 APA_AVM_3_AVMDisplaySts 1 "On(1)" 0 "Off(0)" ;
VAL_ 1288 APA_2_AVMStatusFault 1 "Failure(1)" 0 "Not_Failure(0)" ;
VAL_ 1288 APA_2_AVMFaultStatusCameraRight 1 "Failure(1)" 0 "Not_Failure(0)" ;
VAL_ 1288 APA_2_AVMFaultStatusCameraRear 1 "Active(1)" 0 "Not_Active(0)" ;
VAL_ 1288 APA_2_AVMFaultStatusCameraLeft 1 "Failure(1)" 0 "Normal(0)" ;
VAL_ 1288 APA_2_AVMFaultStatusCameraFront 1 "Failure(1)" 0 "Normal(0)" ;
VAL_ 773 FRM_3_AEB_ON_OFF_Sts 1 "On(1)" 0 "Off(0)" ;
VAL_ 773 FRM_3_FCW_OPTION_Sts 3 "Earlier(3)" 2 "Laster(2)" 1 "Midder(1)" 0 "Reserved(0)" ;
VAL_ 773 FRM_3_FCW_ON_OFF_Sts 1 "On(1)" 0 "Off(0)" ;
VAL_ 773 FRM_3_FCW_PreWarning 1 "Warning(1)" 0 "No_Warning(0)" ;
VAL_ 773 FRM_3_DistanceWarning 1 "Warning(1)" 0 "No_Warning(0)" ;
VAL_ 773 FRM_3_AEBMode 3 "Failure_Mode(3)" 2 "Active_Mode(2)" 1 "On_Mode(1)" 0 "OFF_Mode(0)" ;
VAL_ 773 FRM_3_FCWMode 3 "Failure_Mode(3)" 2 "Active_Mode(2)" 1 "On_Mode(1)" 0 "OFF_Mode(0)" ;
VAL_ 773 FRM_3_ACCMode 9 "Failure_Mode(9)" 8 "reserved(8)" 7 "Override(7)" 6 "Stand_Wait(6)" 5 "Stand_Active(5)" 4 "Brake_Only_Mode(4)" 3 "Active_Control_Mode(3)" 2 "Stand_By_Mode(2)" 1 "Passive_Mode(1)" 0 "OFF_Mode(0)" ;
VAL_ 773 FRM_3_TimeGapSet_ICM 3 "No_Display(3)" 2 "TauGap_2(2)" 1 "TauGap_1(1)" 0 "TauGap_0(0)" ;
VAL_ 773 FRM_3_TakeOverReq 1 "Requst(1)" 0 "No_Requst(0)" ;
VAL_ 773 FRM_3_Textinfo 31 "Reserved" 30 "Reserved" 29 "unabletoactiveACCduetospeedlimit" 28 "activeACCduetonotinDgear" 27 "activeACCduetobrakepedalpressed" 26 "activeACCduetoseatbeltunbuckled" 25 "unabletoactiveACCduetotrunkopen" 24 "unabletoactiveACCduetohoodopen" 23 "unabletoactiveACCduetodoorsopen" 22 "ACC_Is_Stand_Wait(22)" 21 "ACC_Is_Stand_Active(21)" 20 "Radar_Is_In_Error_Mode(20)" 19 "FCW_Is_In_Error_Mode(19)" 18 "FCW_Is_Active(18)" 17 "distanceWarning_Is_Active(17)" 16 "unable_To_Active_FCW(16)" 15 "FCW_Is_Switched_On(15)" 14 "FCW_Is_Switched_Off(14)" 13 "Radar_Is_Covered(13)" 12 "AEB_Is_In_Error_Mode(12)" 11 "AEB_Is_Active(11)" 10 "unable_To_Active_AEB(10)" 9 "AEB_Is_Switched_On(9)" 8 "AEB_Is_Switched_Off(8)" 7 "Driver_Take_Over(7)" 6 "ACC_Is_In_Error_Mode(6)" 5 "ACC_Is_Active(5)" 4 "unable_To_Active_ACC(4)" 3 "ACC_Is_Switched_On(3)" 2 "ACC_Is_Switched_Off(2)" 1 "ACC_Is_Cancelled(1)" 0 "No_Display(0)" ;
VAL_ 773 FRM_3_FrontObject_Type 7 "Reserved(7)" 6 "Reserved(6)" 5 "Others(5)" 4 "Bike(4)" 3 "Pedestrian(3)" 2 "Truck(2)" 1 "Car(1)" 0 "No_Display(0)" ;
VAL_ 773 FRM_3_ObjValid 1 "Target object detected(1)" 0 "No object(0)" ;
VAL_ 773 FRM_3_DxTarObj 7 "Reserved(7)" 6 "Reserved(6)" 5 "Reserved(5)" 4 "Reserved(4)" 3 "Distance_3(3)" 2 "Distance_2(2)" 1 "Distance_1(1)" 0 "No_Display(0)" ;
VAL_ 1241 FuelTankLidSystemFailureSts 1 "Failure(1)" 0 "No_Failure(0)" ;
VAL_ 1241 FuelTankPressureConditionReached 3 "Reserved(3)" 2 "Ready_To_Refuel(2)" 1 "Wait_To_Refuel(1)" 0 "Not_Active(0)" ;
VAL_ 632 EMS_4_EngineSts 0 "Not_Run(0)" 1 "Run(1)" ;
VAL_ 1202 GSM_STAT_ShifterLeverFault 0 "Shift_Sensors_Both_Ok(0)" 1 "Shift_Sensor_1_Fault(1)" 2 "Shift_Sensor_2_Fault(2)" 3 "Shift_Sensors_Both_Fault(3)" 4 "Reserve(4)" 5 "Reserve(5)" 6 "Reserve(6)" 7 "Invalid(7)" ;
VAL_ 1202 GSM_STAT_ParkButton 0 "no_Request(0)" 1 "driver_Request_Park_Button(1)" 2 "Park_Button_Fault(2)" 3 "reserved(3)" ;
VAL_ 1202 GSM_GearShiftPosInverse 0 "Reserved(0)" 1 "Reserved(1)" 2 "Reserved(2)" 3 "Reserved(3)" 4 "Reserved(4)" 5 "Reserved(5)" 6 "Reserved(6)" 7 "Shifter_Not_Initialized_INIT(7)" 8 "Tip-_Manual_Shift_Down_(8)" 9 "Tip+_Manual_Shift_Up_(9)" 10 "POS_FIVE_Backwards_Twice_Y2_(10)" 11 "POS_FOUR_Backwards_Once_Y1_(11)" 12 "POS_THREE_Forward_Once_X1_(12)" 13 "POS_TWO_Forward_Twice_X2_(13)" 14 "POS_ONE_Z_Manual_Position_(14)" 15 "POS_ZERO_Z_(15)" ;
VAL_ 1202 ACC_Cruise_Control 3 "OFF_Pressed(3)" 2 "Stuck(2)" 1 "ON_Pressed(1)" 0 "Notaction(0)" ;
VAL_ 1202 GSM_GearShiftPos 0 "POS_ZERO_Z(0)" 1 "POS_ONE_Z_Manual_Position(1)" 2 "POS_TWO_Forward_Twice_X2(2)" 3 "POS_THREE_Forward_Once_X1(3)" 4 "POS_FOUR_Backwards_Once_Y1(4)" 5 "POS_FIVE_Backwards_Twice_Y2(5)" 6 "Tip+_Manual_Shift_Up(6)" 7 "Tip-_Manual_Shift_Down(7)" 8 "Shifter_Not_Initialized_INIT(8)" 9 "Reserved(9)" 10 "Reserved(10)" 11 "Reserved(11)" 12 "Reserved(12)" 13 "Reserved(13)" 14 "Reserved(14)" 15 "Reserved(15)" ;
VAL_ 1507 DHM_1_Doorkonb_time_freeback 3 "180S(3)" 2 "90S(2)" 1 "30S(1)" 0 "Invalid_Default(0)" ;
VAL_ 1518 CEM_DHM_handlelockswitchfeedback 0 "close(0)" 1 "Open(1)" ;
VAL_ 1518 CEM_DHM_handleunlockswitchfeedba 0 "close(0)" 1 "Open(1)" ;
VAL_ 1517 CEM_SRF_lockingreason 7 "预留(7)" 6 "预留(6)" 5 "预留(5)" 4 "预留(4)" 3 "高速关天窗(3)" 2 "雨天关天窗(2)" 1 ":设防成功关闭(1)" 0 "默认值无效(0)" ;
VAL_ 1517 CEM_RR_window_up_Reason_feedback 7 "雨天关窗(7)" 6 "洗车模式(6)" 5 "TBOX(5)" 4 "设防成功(4)" 3 "IHU(3)" 2 "本地开关(2)" 1 "主驾LIN开关(1)" 0 "默认值(0)" ;
VAL_ 1517 CEM_LR_window_up_Reason_feedback 7 "雨天关窗(7)" 6 "洗车模式(6)" 5 "TBOX(5)" 4 "设防成功(4)" 3 "IHU(3)" 2 "本地开关(2)" 1 "主驾LIN开关(1)" 0 "默认值(0)" ;
VAL_ 1517 CEM_Passenger_window_up_Reason_f 7 "雨天关窗(7)" 6 "洗车模式(6)" 5 "TBOX(5)" 4 "设防成功(4)" 3 "IHU(3)" 2 "本地开关(2)" 1 "主驾LIN开关(1)" 0 "默认值(0)" ;
VAL_ 1517 CEM_Driver_window_up_Reason_feed 7 "雨天关窗(7)" 6 "预留(6)" 5 "洗车模式(5)" 4 "TBOX(4)" 3 "设防成功(3)" 2 "IHU(2)" 1 "主驾LIN开关(1)" 0 "默认值(0)" ;
VAL_ 1504 CEM_SRFclosingConditions 15 "Not used(15)" 14 "Not used(14)" 13 "Not used(13)" 12 "Not used(12)" 11 "Not used(11)" 10 "Not used(10)" 9 "Not used(9)" 8 "Not used(8)" 7 "Not used(7)" 6 "Not used(6)" 5 "Not used(5)" 4 "Not used(4)" 3 "vehicle speed(3)" 2 "rainy(2)" 1 "Remote control locking car(1)" 0 "NoAcitive(0)" ;
VAL_ 1504 CEM_Abat_VentCMDSts 15 "Not used(15)" 14 "Not used(14)" 13 "Not used(13)" 12 "tilt(12)" 11 "100%(11)" 10 "90%(10)" 9 "80%(9)" 8 "70%(8)" 7 "60%(7)" 6 "50%(6)" 5 "40%(5)" 4 "30%(4)" 3 "20%(3)" 2 "10%(2)" 1 "0%(1)" 0 "NoAcitive(0)" ;
VAL_ 1504 CEM_PSRFCMDSts 15 "Not used(15)" 14 "Not used(14)" 13 "Not used(13)" 12 "tilt(12)" 11 "100%(11)" 10 "90%(10)" 9 "80%(9)" 8 "70%(8)" 7 "60%(7)" 6 "50%(6)" 5 "40%(5)" 4 "30%(4)" 3 "20%(3)" 2 "10%(2)" 1 "0%(1)" 0 "NoAcitive(0)" ;
VAL_ 1168 CEM_ALM_1_SceneMode_ControlSwitc 3 "Reserved(3)" 2 "Reserved(2)" 1 "ON(1)" 0 "OFF(0)" ;
VAL_ 1168 CEM_ALM_1_DeletePeronalSet_FB 15 "Invaild(15)" 14 "Reserved(14)" 13 "Reserved(13)" 12 "Reserved(12)" 11 "Reserved(11)" 10 "Reserved(10)" 9 "Reserved(9)" 8 "Reserved(8)" 7 "Reserved(7)" 6 "Reserved(6)" 5 "Reset_User_ID_X(5)" 4 "Reset_User_ID_X(4)" 3 "Reset_User_ID_X(3)" 2 "Reset_User_ID_X(2)" 1 "Reset_User_ID_X(1)" 0 "Sartup_Default(0)" ;
VAL_ 1168 CEM_ALM_1_PersonalBeamEn 3 "Reserved(3)" 2 "Disable(2)" 1 "Enable(1)" 0 "Default(0)" ;
VAL_ 1168 CEM_ALM_1_PersonalSeatEn 3 "Reserved(3)" 2 "Disable(2)" 1 "Enable(1)" 0 "Default(0)" ;
VAL_ 1168 CEM_ALM_1_Seat_Set_Status 15 "Reserved(15)" 14 "Reserved(14)" 13 "Reserved(13)" 12 "Reserved(12)" 11 "Reserved(11)" 10 "Reserved(10)" 9 "Reserved(9)" 8 "return to position 3(8)" 7 "return to position 2(7)" 6 "return to position 1(6)" 5 "Adjustment Failed(5)" 4 "Setup Failed(4)" 3 "Setting position 3 succeeded(3)" 2 "Setting position 2 succeeded(2)" 1 "Setting position 1 succeeded(1)" 0 "Invalid(0)" ;
VAL_ 1168 CEM_ALM_1_Seat_Set_Pop_Up 2 "No_Active(2)" 1 "Active(1)" 0 "No_Request(0)" ;
VAL_ 1168 CEM_ALM_1_Wash_Car_Status 2 "No_Active(2)" 1 "Active(1)" 0 "No_Request(0)" ;
VAL_ 1168 CEM_ALM_1_PersonalSetSts 0 "NotActive(0)" 1 "Active(1)" ;
VAL_ 1168 CEM_ALM_1_STAT_WelcomeWaterLamp 3 "Reserved(3)" 2 "Reserved(2)" 1 "ON(1)" 0 "OFF(0)" ;
VAL_ 1168 CEM_ALM_1_STAT_AssociatedWithDri 3 "Reserved(3)" 2 "Reserved(2)" 1 "ON(1)" 0 "OFF(0)" ;
VAL_ 1168 CEM_ALM_1_STAT_Music 3 "Reserved(3)" 2 "Reserved(2)" 1 "ON(1)" 0 "OFF(0)" ;
VAL_ 1168 CEM_ALM_1_STAT_Apiluminance 15 "Invalid(15)" 14 "Reserved(14)" 13 "Reserved(13)" 12 "Reserved(12)" 11 "Reserved(11)" 10 "Reserved(10)" 9 "Reserved(9)" 8 "Reserved(8)" 7 "Level8(7)" 6 "Level7(6)" 5 "Level6(5)" 4 "Level5(4)" 3 "Level4(3)" 2 "Level3(2)" 1 "Level2(1)" 0 "Level1(0)" ;
VAL_ 1168 CEM_ALM_1_STAT_Static_Colour 15 "Invalid(15)" 14 "Reserved(14)" 13 "Reserved(13)" 12 "Reserved(12)" 11 "Reserved(11)" 10 "Reserved(10)" 9 "Reserved(9)" 8 "Reserved(8)" 7 "Purple(7)" 6 "Pink(6)" 5 "Red(5)" 4 "Orange(4)" 3 "Yellow(3)" 2 "Green(2)" 1 "Cyan(1)" 0 "Blue(0)" ;
VAL_ 1168 CEM_ALM_1_STAT_StaticEffect 7 "Startup(7)" 3 "All_Discolour_Breath(3)" 2 "Discolour_Breath(2)" 1 "Monochrome_Breath(1)" 0 "Monochrome_Static(0)" ;
VAL_ 1168 CEM_ALM_1_STAT_ControlSwitch 2 "Force(2)" 1 "OFF(1)" 0 "Control(0)" ;
VAL_ 1168 CEM_ALM_1_STAT_DMSMonitoring 3 "Reserved(3)" 2 "Reserved(2)" 1 "ON(1)" 0 "OFF(0)" ;
VAL_ 1168 CEM_ALM_1_STAT_PM2_5Monitoring 3 "Reserved(3)" 2 "Reserved(2)" 1 "ON(1)" 0 "OFF(0)" ;
VAL_ 1168 CEM_ALM_1_STAT_DriveApiluminance 2 "Close(2)" 1 "Dark(1)" 0 "Normal(0)" ;
VAL_ 1476 CEM_massagemodeSts 4 "5 Mode(4)" 3 "4 Mode(3)" 2 "3 Mode(2)" 1 "2 Mode(1)" 0 "1 Mode(0)" ;
VAL_ 1476 CEM_passageVibrationSts 2 "High(2)" 1 "Middle(1)" 0 "Low(0)" ;
VAL_ 1476 CEM_Passenger_massageSts 1 "Active(1)" 0 "No_Active(0)" ;
VAL_ 1476 CEM_Mirror_Driverseat_Location 21 "M+10(21)" 20 "M+9(20)" 19 "M+8(19)" 18 "M+7(18)" 17 "M+6(17)" 16 "M+5(16)" 15 "M+4(15)" 14 "M+3(14)" 13 "M+2(13)" 12 "M+1(12)" 10 "location 10(10)" 9 "location 9(9)" 8 "location 8(8)" 7 "location 7(7)" 6 "location 6(6)" 5 "location 5(5)" 4 "location 4(4)" 3 "location 3(3)" 2 "location 2(2)" 1 "location 1(1)" 0 "Startup/Default(0)" ;
VAL_ 1476 CEM_UnderVoltageSts 1 "Active(1)" 0 "Not Active(0)" ;
VAL_ 1476 CEM_RearWiper_SwitchSts 1 "Active(1)" 0 "Not Active(0)" ;
VAL_ 1476 CEM_Wiper_MaintenanceSts 1 "Active(1)" 0 "Not Active(0)" ;
VAL_ 1476 CEM_Mirror_Fold_SwitchSts 1 "Active(1)" 0 "Not Active(0)" ;
VAL_ 1476 CEM_IPM__FRSeatHeatVentSwSts 7 "Level_3_Ventilation_Request(7)" 6 "Level_2_Ventilation_Request(6)" 5 "Level_1_Ventilation_Request(5)" 4 "Level_3_Heat_Request(4)" 3 "Level_2_Heat_Request(3)" 2 "Level_1_Heat_Request(2)" 1 "OFF(1)" 0 "NO_Request(0)" ;
VAL_ 1476 CEM_IPM_FLSeatHeatVentSwSts 7 "Level_3_Ventilation_Request(7)" 6 "Level_2_Ventilation_Request(6)" 5 "Level_1_Ventilation_Request(5)" 4 "Level_3_Heat_Request(4)" 3 "Level_2_Heat_Request(3)" 2 "Level_1_Heat_Request(2)" 1 "OFF(1)" 0 "NO_Request(0)" ;
VAL_ 1476 CEM_DriverLumbart_UDSts 2 "Move Down(2)" 1 "Move Up(1)" 0 "Null(0)" ;
VAL_ 1476 CEM_DriverLumbart_FRSts 2 "Move Rear(2)" 1 "Move Front(1)" 0 "Null(0)" ;
VAL_ 1476 CEM_DriverSeat_RearendUDSts 2 "Move Down(2)" 1 "Move Up(1)" 0 "Null(0)" ;
VAL_ 1476 CEM_DriverSeat_FrontendUDSts 2 "Move Down(2)" 1 "Move Up(1)" 0 "Null(0)" ;
VAL_ 1476 CEM_DriverSeat_FRSts 2 "Move Rear(2)" 1 "Move Front(1)" 0 "Null(0)" ;
VAL_ 1476 CEM_DriverSeat_BackFRSts 2 "Move Rear(2)" 1 "Move Front(1)" 0 "Null(0)" ;
VAL_ 1476 CEM_MirrorFlip_CFGSts 3 "Left side and right side(3)" 2 "Right side(2)" 1 "Left side(1)" 0 "off(0)" ;
VAL_ 1476 CEM_RightMirrorCtrlSts 7 "Invalid Value(7)" 6 "Error Value(6)" 5 "Reserved(5)" 4 "Move Right(4)" 3 "Move Left(3)" 2 "Move Down(2)" 1 "Move Up(1)" 0 "Null(0)" ;
VAL_ 1476 CEM_LeftMirrorCtrlSts 7 "Invalid Value(7)" 6 "Error Value(6)" 5 "Reserved(5)" 4 "Move Right(4)" 3 "Move Left(3)" 2 "Move Down(2)" 1 "Move Up(1)" 0 "Null(0)" ;
VAL_ 1476 CEM_RHRdoor_buttonsts 1 "Pressed(1)" 0 "Notaction (0)" ;
VAL_ 1476 CEM_LHRdoor_buttonsts 1 "Pressed(1)" 0 "Notaction (0)" ;
VAL_ 1476 CEM_PsngrDoor_buttonsts 1 "Pressed(1)" 0 "Notaction (0)" ;
VAL_ 1476 CEM_Smart_HighBeamSts 1 "Active(1)" 0 "No Active(0)" ;
VAL_ 1476 CEM_HighBeam_AdjustSts 3 "The third gear(3)" 2 "The second gear(2)" 1 "The first gear(1)" 0 "The Zeroth gear(0)" ;
SIG_GROUP_ 826 New_Signal_Group_33A 1 : USB_TBOX_Connection_Status SDK_Opposite_End_Application_Err SDK_Network_Link_Error SDK_Unknow_Error SDK_Opposite_End_Application_Unr Area_Parking_Frame_Selected_0000 Area_Parking_Frame_Selected_Area;
SIG_GROUP_ 824 New_Signal_Group_337 1 : TICE_Appointed_Parking_Space_ID Target_Map_ID_Selected_By_User Area_Parking_Frame_Selected_0002 Area_Parking_Frame_Selected_0001 Map_Uploda_ID VPA_User_Chooses_to_Delete_Map_I APA_Target_Parking_Space_ID;
SIG_GROUP_ 823 New_Signal_Group_337 1 : MOD_Request_to_Display_Route_Lis MOD_Function_Run_Operation_Comma Parking_Function_User_Learning_S VPA_Request_to_Display_Route_Lis Location_Command MOD_Route_Map_Operation_Command Driving_Function_User_Learning_S Trained_Parking_Self_Learning_An TICE_Trained_Parking_Out_Command TICE_Trained_Parking_Command Low_Speed_Auto_Location_Function Initial_D_Gear_Open_AVM_Switch_S TICE_Vehicle_Restore_Factor_0000 TICE_Vehicle_Restore_Factory_Set TRA_Command Trained_Parking_Mode_Selection Map_Operation_Command Low_Speed_Auto_Parking_Space_Det IHU_AVM_Set_BV_OP_SW Map_Train_Type Over_Speed_Remind_Warning_Mode_S IHU_GearR_APA_AVM_OP_SW;
SIG_GROUP_ 822 New_Signal_Group_336 1 : MOD_User_Selects_Enable_Map_Iden MOD_User_Selects_Top_Map_Identif MOD_Preview_Map_Identifier MOD_User_Selects_Delete_Map_Iden VPA_User_Select_Top_Map_Identifi VPA_User_Specify_Target_Floor_Id VPA_User_Requests_Single_Map_Ide Over_Speed_Close_AVM_Set_Request IHU_AVM_Set_EmergencyBrake;
SIG_GROUP_ 828 New_Signal_Group_33C 1 : IHU_APA_OP_SW IHU_APA_Slot_Chosen IHU_APA_Engage_Confirm IHU_APA_Suspend_Resume IHU_APA_ParkIn_Direction IHU_APA_PullOut_Option IHU_AVM_Set_RadarWarining IHU_AVM_Set_Language IHU_AVM_Set_SteeringWheel IHU_AVM_OP_SW IHU_AVM_Set_AutoZoom IHU_AVM_Set_BodyColor IHU_AVM_Set_TurnIndication FCTBrkSwtSet FCTASwtSet DataCollAuthSw APA_Parkin_Engage_Confirm IHU_AVM_Set_PASTrigger IHU_AVM_Set_FactoryDefault IHU_AVM_Set_GuideLine IHU_AVM_Set_LicensePlate IHU_AVM_Set_AutoExit IHU_RPA_OP_SW IHU_RPA_Engage_Confirm IHU_APA_Heartbeat IHU_APA_Prompt_Confirm IHU_APA_Combi_Sw IHU_APA_PullOut_Direction APA_Pullout_Engage_Confirm;
SIG_GROUP_ 1416 IHU_24_0x588_Group 1 : IHU_24_Sentinel_RemoteLockFeedba IHU_24_SentinelModeSwitchReq IHU_24_SentinelMode_SensitivityR IHU_24_TimeToStartSentinelDaySet IHU_24_TimeToStartSentinelHourSe IHU_24_TimeToStartSentinelMinute IHU_24_TimeToStopSentinelHourSet IHU_24_TimeToStopSentinelMinuteS IHU_24_Reservation_SentinelReq RPASwitch FollowingTrackToReverse RCTB_OnOffSt RCW_OnOffSt DCLC_Switch ELK_Switch IHU_11_TSISwtSet IESSwtSet Ready2GoSwitch;
SIG_GROUP_ 1414 IHU_AMP_0x586_group 1 : IHU_AMP_2__AMPA2BENCSound IHU_AMP_2_Set_AMPENCReq IHU_AMP_2_SoundEffectBassMid IHU_AMP_2_SoundEffectMidtreble REQ_AMPA2BPhoneSound Set_AMPSpeedVolume Set_AMPMute REQ_AMPA2BNaviSound REQ_AMPA2BVRSound REQ_AMPA2BTTSSound REQ_AMPA2BKeyTone IHU_19_REQ_AMPA2BESESound IHU_19_REQ_AMPA2BMediSound IHU_19_Set_AMPBTMediVol IHU_19_Set_AMPWelVol IHU_19_Set_AMPESEVol IHU_19_SetIHUAlarm REQ_AMPA2BMediaSound IHU_19_Set_HdrestSpkrMod;
SIG_GROUP_ 1413 IHU_AMP_0x585_group 1 : Set_AMPNaviVolume Set_AMPVRVolume Set_AMPMediaVolume Set_AMPPhoneVolume Set_AMPSoundFocus Set_AMPDefaultVolume Set_AMPRestoreDefaults Set_AMPSoundEffect Set_AMPSoundEffectBass Set_AMPSoundEffectMidrange Set_AMPSoundEffectTreble Set_AMPSoundFieldBalance Set_AMPSoundFieldFader Set_AMPLiveAcoustics Set_AMPLoudness Set_AMPAlarmVolume Set_AMPKeyTone;
SIG_GROUP_ 1114 IHU_APA_0x45A_group 1 : IHU_APA_3_AVMFloat IHU_APA_3_VoiceCtrldPrkgCmd IHU_APA_3_MEB_Switch IHU_APA_3_KeySts IHU_APA_3_CalibrationReq IHU_APA_3_TouchEvt IHU_APA_3_NaviBtnPressInputValue IHU_APA_3_NaviBtnPressInput_0000 IHU_APA_3_I_isplayAVMOff IHU_APA_3_AVMSwt;
SIG_GROUP_ 1276 IHU_11_0x4FC_group 1 : IHU_11_TLISwtSet IHU_11_WarnModSwtSet IHU_11_ELKSwtSet IHU_11_LDWLDPSnvtySet IHU_11_LDPSwtSet IHU_11_LDWSwtSet IHU_11_TSISwtSet IHU_11_IESSwtSet IHU_11_DAISwtSet IHU_11_SCFSwtSet IHU_11_SLASwtSet IHU_11_TJAICAExitTextInfoSwtSet IHU_11_FCWSwtSet IHU_11_FCWSnvtySet IHU_11_AEBSwtSet IHU_11_HMASwtSet;
